VERSION ""

NS_ :

BS_:

BU_: EPB SCC ACU MDPS PGS AFLS CLU LCA iBAU TPMS LDWS_LKAS CGW

BO_ 550 NAVI_STD_STUB_E: 8 CGW
 SG_ STUB_MessageType : 0|3@1+ (1,0) [0|7] ""  SCC
 SG_ STUB_Offset : 3|13@1+ (1,0) [0|8191] ""  SCC
 SG_ STUB_CyclicCounter : 16|2@1+ (1,0) [0|3] ""  SCC
 SG_ STUB_PathIndex : 18|6@1+ (1,0) [0|63] ""  SCC
 SG_ STUB_SubPathIndex : 24|6@1+ (1,0) [0|63] ""  SCC
 SG_ STUB_Retransmission : 30|1@1+ (1,0) [0|1] ""  SCC
 SG_ STUB_Update : 31|1@1+ (1,0) [0|1] ""  SCC
 SG_ STUB_RelativeProbability : 32|5@1+ (3.333,0) [0|103.323] ""  SCC
 SG_ STUB_FunctionalRoadClass : 37|3@1+ (1,0) [0|7] ""  SCC
 SG_ STUB_CalculatedRoute : 40|2@1+ (1,0) [0|3] ""  SCC
 SG_ STUB_ComplexIntersection : 42|2@1+ (1,0) [0|3] ""  SCC
 SG_ STUB_FormOfWay : 44|4@1+ (1,0) [0|15] ""  SCC
 SG_ STUB_TurnAngle : 48|8@1+ (1.417,0) [0|361.335] ""  SCC
 SG_ STUB_LastStubAtOffset : 56|1@1+ (1,0) [0|1] ""  SCC
 SG_ STUB_RightOfWay : 57|2@1+ (1,0) [0|3] ""  SCC
 SG_ STUB_OppositeLanes : 59|2@1+ (1,0) [0|3] ""  SCC
 SG_ STUB_DirectionLanes : 61|3@1+ (1,0) [0|7] ""  SCC

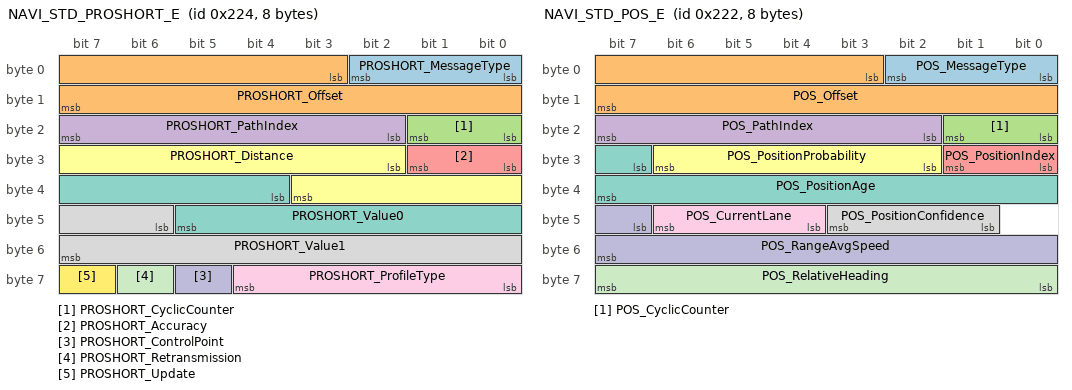
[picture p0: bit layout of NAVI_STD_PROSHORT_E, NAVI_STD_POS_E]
BO_ 548 NAVI_STD_PROSHORT_E: 8 CGW
 SG_ PROSHORT_MessageType : 0|3@1+ (1,0) [0|7] ""  SCC
 SG_ PROSHORT_Offset : 3|13@1+ (1,0) [0|8191] ""  SCC
 SG_ PROSHORT_CyclicCounter : 16|2@1+ (1,0) [0|3] ""  SCC
 SG_ PROSHORT_PathIndex : 18|6@1+ (1,0) [0|63] ""  SCC
 SG_ PROSHORT_Accuracy : 24|2@1+ (1,0) [0|3] ""  SCC
 SG_ PROSHORT_Distance : 26|10@1+ (1,0) [0|1023] ""  SCC
 SG_ PROSHORT_Value0 : 36|10@1+ (1,0) [0|1023] ""  SCC
 SG_ PROSHORT_Value1 : 46|10@1+ (1,0) [0|1023] ""  SCC
 SG_ PROSHORT_ProfileType : 56|5@1+ (1,0) [0|31] ""  SCC
 SG_ PROSHORT_ControlPoint : 61|1@1+ (1,0) [0|1] ""  SCC
 SG_ PROSHORT_Retransmission : 62|1@1+ (1,0) [0|1] ""  SCC
 SG_ PROSHORT_Update : 63|1@1+ (1,0) [0|1] ""  SCC

BO_ 549 NAVI_STD_SEG_E: 8 CGW
 SG_ SEG_MessageType : 0|3@1+ (1,0) [0|7] ""  SCC
 SG_ SEG_Offset : 3|13@1+ (1,0) [0|8191] ""  SCC
 SG_ SEG_CyclicCounter : 16|2@1+ (1,0) [0|3] ""  SCC
 SG_ SEG_PathIndex : 18|6@1+ (1,0) [0|63] ""  SCC
 SG_ SEG_Tunnel : 24|2@1+ (1,0) [0|3] ""  SCC
 SG_ SEG_Bridge : 26|2@1+ (1,0) [0|3] ""  SCC
 SG_ SEG_BuiltUpArea : 28|2@1+ (1,0) [0|3] ""  SCC
 SG_ SEG_Retransmission : 30|1@1+ (1,0) [0|1] ""  SCC
 SG_ SEG_Update : 31|1@1+ (1,0) [0|1] ""  SCC
 SG_ SEG_RelativeProbability : 32|5@1+ (3.333,0) [0|103.323] ""  SCC
 SG_ SEG_FunctionalRoadClass : 37|3@1+ (1,0) [0|7] ""  SCC
 SG_ SEG_CalculatedRoute : 40|2@1+ (1,0) [0|3] ""  SCC
 SG_ SEG_ComplexIntersection : 42|2@1+ (1,0) [0|3] ""  SCC
 SG_ SEG_FormOfWay : 44|4@1+ (1,0) [0|15] ""  SCC
 SG_ SEG_SpeedLimit : 48|5@1+ (1,0) [0|31] ""  SCC
 SG_ SEG_SpeedLimitType : 53|3@1+ (1,0) [0|7] ""  SCC
 SG_ SEG_DividedRoad : 57|2@1+ (1,0) [0|3] ""  SCC
 SG_ SEG_OppositeLanes : 59|2@1+ (1,0) [0|3] ""  SCC
 SG_ SEG_DirectionLanes : 61|3@1+ (1,0) [0|7] ""  SCC

BO_ 546 NAVI_STD_POS_E: 8 CGW
 SG_ POS_MessageType : 0|3@1+ (1,0) [0|7] ""  SCC
 SG_ POS_Offset : 3|13@1+ (1,0) [0|8191] ""  SCC
 SG_ POS_CyclicCounter : 16|2@1+ (1,0) [0|3] ""  SCC
 SG_ POS_PathIndex : 18|6@1+ (1,0) [0|63] ""  SCC
 SG_ POS_PositionIndex : 24|2@1+ (1,0) [0|3] ""  SCC
 SG_ POS_PositionProbability : 26|5@1+ (3.333,0) [0|103.323] ""  SCC
 SG_ POS_PositionAge : 31|9@1+ (5,0) [0|2555] ""  SCC
 SG_ POS_PositionConfidence : 41|3@1+ (1,0) [0|7] ""  SCC
 SG_ POS_CurrentLane : 44|3@1+ (1,0) [0|7] ""  SCC
 SG_ POS_RangeAvgSpeed : 47|9@1+ (1,0) [0|511] ""  SCC
 SG_ POS_RelativeHeading : 56|8@1+ (1.417,0) [0|361.335] ""  SCC

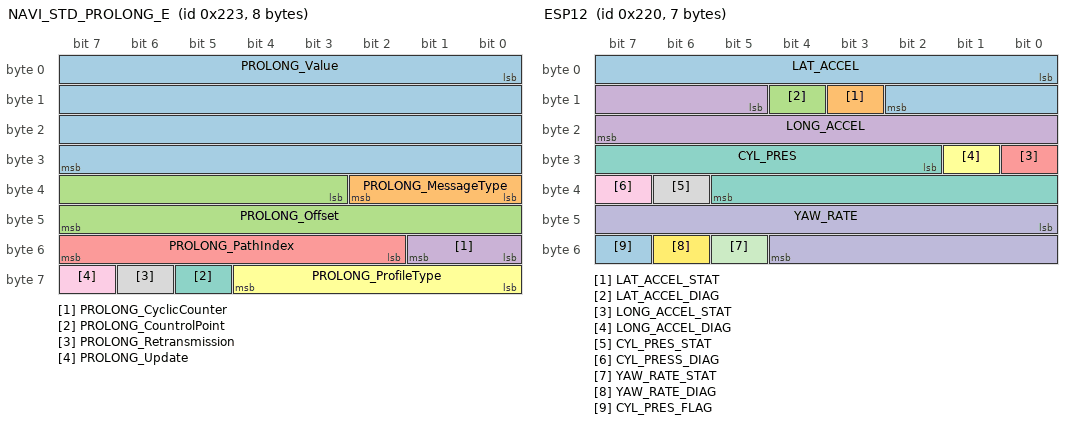
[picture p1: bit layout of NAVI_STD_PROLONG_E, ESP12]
BO_ 547 NAVI_STD_PROLONG_E: 8 CGW
 SG_ PROLONG_Value : 0|32@1+ (1,0) [0|4294967295] ""  SCC
 SG_ PROLONG_MessageType : 32|3@1+ (1,0) [0|7] ""  SCC
 SG_ PROLONG_Offset : 35|13@1+ (1,0) [0|8191] ""  SCC
 SG_ PROLONG_CyclicCounter : 48|2@1+ (1,0) [0|3] ""  SCC
 SG_ PROLONG_PathIndex : 50|6@1+ (1,0) [0|63] ""  SCC
 SG_ PROLONG_ProfileType : 56|5@1+ (1,0) [0|31] ""  SCC
 SG_ PROLONG_CountrolPoint : 61|1@1+ (1,0) [0|1] ""  SCC
 SG_ PROLONG_Retransmission : 62|1@1+ (1,0) [0|1] ""  SCC
 SG_ PROLONG_Update : 63|1@1+ (1,0) [0|1] ""  SCC

BO_ 544 ESP12: 7 iBAU
 SG_ LAT_ACCEL : 0|11@1+ (0.01,-10.23) [-10.23|10.24] "m/s^2"  LDWS_LKAS,SCC
 SG_ LAT_ACCEL_STAT : 11|1@1+ (1,0) [0|1] ""  LDWS_LKAS,SCC
 SG_ LAT_ACCEL_DIAG : 12|1@1+ (1,0) [0|1] ""  LDWS_LKAS,SCC
 SG_ LONG_ACCEL : 13|11@1+ (0.01,-10.23) [-10.23|10.24] "m/s^2"  EPB,LDWS_LKAS,SCC
 SG_ LONG_ACCEL_STAT : 24|1@1+ (1,0) [0|1] ""  EPB,LDWS_LKAS,SCC
 SG_ LONG_ACCEL_DIAG : 25|1@1+ (1,0) [0|1] ""  EPB,LDWS_LKAS,SCC
 SG_ CYL_PRES : 26|12@1+ (0.1,0) [0|409.5] "Bar"  EPB,LDWS_LKAS,SCC
 SG_ CYL_PRES_STAT : 38|1@1+ (1,0) [0|1] ""  CGW,EPB,LDWS_LKAS,SCC
 SG_ CYL_PRESS_DIAG : 39|1@1+ (1,0) [0|1] ""  EPB,LDWS_LKAS,SCC
 SG_ YAW_RATE : 40|13@1+ (0.01,-40.95) [-40.95|40.96] "˚/s"  AFLS,LCA,LDWS_LKAS,MDPS,SCC
 SG_ YAW_RATE_STAT : 53|1@1+ (1,0) [0|1] ""  AFLS,LDWS_LKAS,MDPS,SCC
 SG_ YAW_RATE_DIAG : 54|1@1+ (1,0) [0|1] ""  AFLS,LDWS_LKAS,MDPS,SCC
 SG_ CYL_PRES_FLAG : 55|1@1+ (1,0) [0|1] ""  CGW

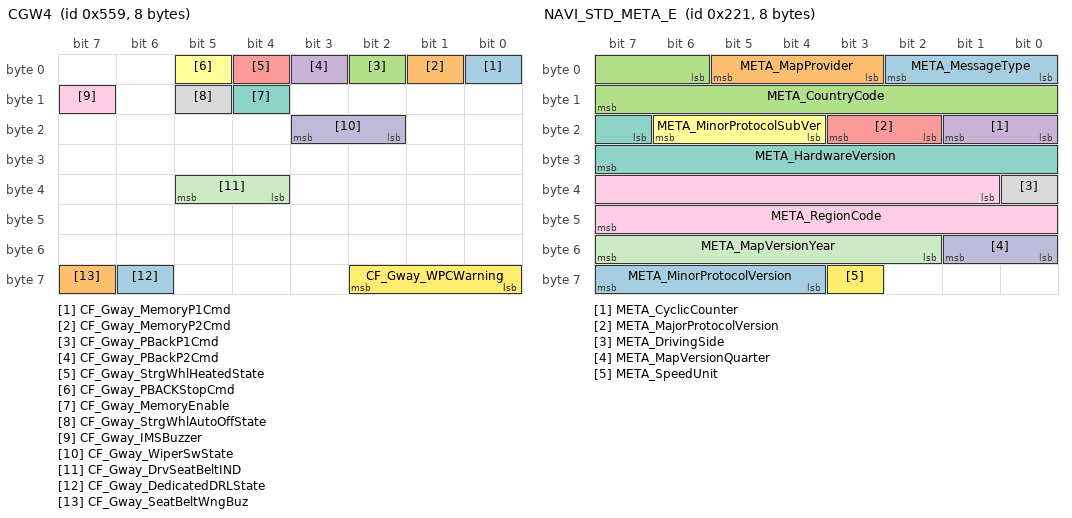
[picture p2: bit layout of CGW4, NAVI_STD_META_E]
BO_ 1369 CGW4: 8 CGW
 SG_ CF_Gway_MemoryP1Cmd : 0|1@1+ (1,0) [0|1] ""  CLU
 SG_ CF_Gway_MemoryP2Cmd : 1|1@1+ (1,0) [0|1] ""  CLU
 SG_ CF_Gway_PBackP1Cmd : 2|1@1+ (1,0) [0|1] ""  CLU
 SG_ CF_Gway_PBackP2Cmd : 3|1@1+ (1,0) [0|1] ""  CLU
 SG_ CF_Gway_StrgWhlHeatedState : 4|1@1+ (1,0) [0|1] ""  CLU
 SG_ CF_Gway_PBACKStopCmd : 5|1@1+ (1,0) [0|1] ""  CLU
 SG_ CF_Gway_MemoryEnable : 12|1@1+ (1,0) [0|1] ""  CLU
 SG_ CF_Gway_StrgWhlAutoOffState : 13|1@1+ (1,0) [0|1] ""  CLU
 SG_ CF_Gway_IMSBuzzer : 15|1@1+ (1,0) [0|1] ""  CLU
 SG_ CF_Gway_WiperSwState : 18|2@1+ (1,0) [0|3] ""  CLU
 SG_ CF_Gway_DrvSeatBeltIND : 36|2@1+ (1,0) [0|3] ""  CLU
 SG_ CF_Gway_WPCWarning : 56|3@1+ (1,0) [0|7] ""  CLU
 SG_ CF_Gway_DedicatedDRLState : 62|1@1+ (1,0) [0|1] ""  CLU
 SG_ CF_Gway_SeatBeltWngBuz : 63|1@1+ (1,0) [0|1] ""  CLU

BO_ 545 NAVI_STD_META_E: 8 CGW
 SG_ META_MessageType : 0|3@1+ (1,0) [0|7] ""  SCC
 SG_ META_MapProvider : 3|3@1+ (1,0) [0|7] ""  SCC
 SG_ META_CountryCode : 6|10@1+ (1,0) [0|1023] ""  SCC
 SG_ META_CyclicCounter : 16|2@1+ (1,0) [0|3] ""  SCC
 SG_ META_MajorProtocolVersion : 18|2@1+ (1,0) [0|3] ""  SCC
 SG_ META_MinorProtocolSubVer : 20|3@1+ (1,0) [0|7] ""  SCC
 SG_ META_HardwareVersion : 23|9@1+ (1,0) [0|511] ""  SCC
 SG_ META_DrivingSide : 32|1@1+ (1,0) [0|1] ""  SCC
 SG_ META_RegionCode : 33|15@1+ (1,0) [0|32767] ""  SCC
 SG_ META_MapVersionQuarter : 48|2@1+ (1,0) [0|3] ""  SCC
 SG_ META_MapVersionYear : 50|6@1+ (1,2000) [2000|2063] ""  SCC
 SG_ META_SpeedUnit : 59|1@1+ (1,0) [0|1] ""  SCC
 SG_ META_MinorProtocolVersion : 60|4@1+ (1,0) [0|15] ""  SCC

BO_ 1363 CGW2: 8 CGW
 SG_ CF_Gway_ExtTailAct : 8|2@1+ (1,0) [0|3] ""  CLU,LCA
 SG_ CF_Gway_AutoLightValue : 16|1@1+ (1,0) [0|1] ""  LCA
 SG_ CF_Gway_BrakeFluidSw : 17|1@1+ (1,0) [0|1] ""  CLU,iBAU
 SG_ CF_Gway_DrvSeatBeltInd : 18|2@1+ (1,0) [0|3] ""  CLU
 SG_ CF_Gway_AvTail : 20|1@1+ (1,0) [0|1] ""  CLU
 SG_ CF_Gway_RearFogAct : 21|1@1+ (1,0) [0|1] ""  CLU
 SG_ CF_Gway_RRDrSw : 23|1@1+ (1,0) [0|1] ""  CLU
 SG_ CF_Gway_RLDrSw : 24|1@1+ (1,0) [0|1] ""  CLU
 SG_ CF_Gway_IntTailAct : 25|1@1+ (1,0) [0|1] ""  CLU
 SG_ CF_Gway_WiperParkPosition : 32|1@1+ (1,0) [0|1] ""  LDWS_LKAS
 SG_ CF_Gway_ESCLFailWarn : 35|1@1+ (1,0) [0|1] ""  CLU
 SG_ CF_Gway_ESCLNotLockedWarn : 36|1@1+ (1,0) [0|1] ""  CLU
 SG_ CF_Gway_ESCLNotUnlockWarn : 37|1@1+ (1,0) [0|1] ""  CLU
 SG_ CF_Gway_IDoutWarn : 38|1@1+ (1,0) [0|1] ""  CLU
 SG_ CF_Gway_ImmoLp : 40|1@1+ (1,0) [0|1] ""  CLU
 SG_ CF_Gway_VehicleNotPWarn : 44|1@1+ (1,0) [0|1] ""  CLU
 SG_ CF_Gway_DeactivationWarn : 45|1@1+ (1,0) [0|1] ""  CLU
 SG_ CF_Gway_KeyBATDischargeWarn : 46|1@1+ (1,0) [0|1] ""  CLU
 SG_ CF_Gway_SSBWarn : 47|1@1+ (1,0) [0|1] ""  CLU
 SG_ CF_Gway_SMKRKECmd : 51|3@1+ (1,0) [0|7] ""  CLU
 SG_ CF_Gway_SJBDeliveryMode : 55|1@1+ (1,0) [0|1] ""  CLU
 SG_ CF_Gway_SMKDispWarn : 57|4@1+ (1,0) [0|15] ""  CLU
 SG_ CF_Gway_WngBuz : 61|3@1+ (1,0) [0|7] ""  CLU

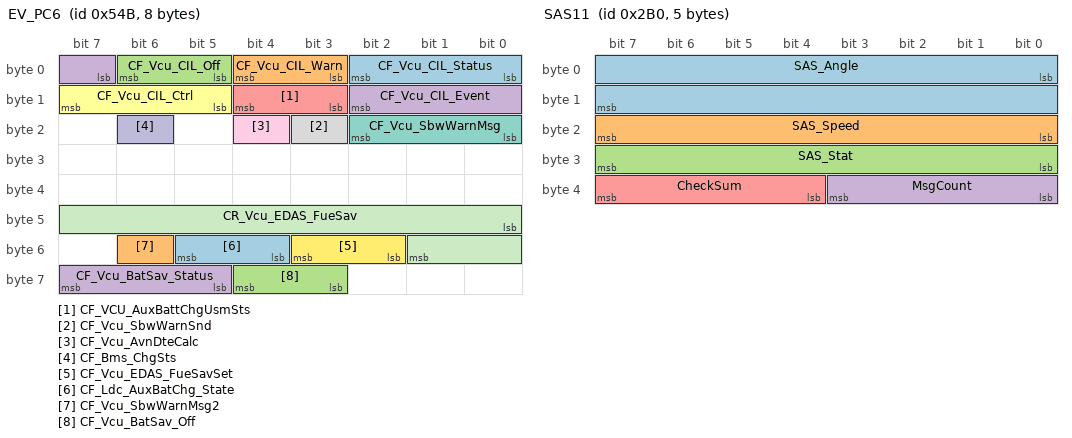
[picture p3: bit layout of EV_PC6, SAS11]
BO_ 1355 EV_PC6: 8 CGW
 SG_ CF_Vcu_CIL_Status : 0|3@1+ (1,0) [0|7] ""  CLU
 SG_ CF_Vcu_CIL_Warn : 3|2@1+ (1,0) [0|3] ""  CLU
 SG_ CF_Vcu_CIL_Off : 5|2@1+ (1,0) [0|3] ""  CLU
 SG_ CF_Vcu_CIL_Event : 7|4@1+ (1,0) [0|15] ""  CLU
 SG_ CF_VCU_AuxBattChgUsmSts : 11|2@1+ (1,0) [0|3] ""  CLU
 SG_ CF_Vcu_CIL_Ctrl : 13|3@1+ (1,0) [0|7] ""  CLU
 SG_ CF_Vcu_SbwWarnMsg : 16|3@1+ (1,0) [0|7] "flag"  CLU,EPB
 SG_ CF_Vcu_SbwWarnSnd : 19|1@1+ (1,0) [0|1] "flag"  CLU
 SG_ CF_Vcu_AvnDteCalc : 20|1@1+ (1,0) [0|1] "flag"  CLU
 SG_ CF_Bms_ChgSts : 22|1@1+ (1,0) [0|1] ""  CLU
 SG_ CR_Vcu_EDAS_FueSav : 40|10@1+ (0.01,0) [0|10] "liter"  CLU
 SG_ CF_Vcu_EDAS_FueSavSet : 50|2@1+ (1,0) [0|3] ""  CLU
 SG_ CF_Ldc_AuxBatChg_State : 52|2@1+ (1,0) [0|3] ""  CLU
 SG_ CF_Vcu_SbwWarnMsg2 : 54|1@1+ (1,0) [0|1] "flag"  CLU
 SG_ CF_Vcu_BatSav_Off : 59|2@1+ (1,0) [0|3] ""  CLU
 SG_ CF_Vcu_BatSav_Status : 61|3@1+ (1,0) [0|7] ""  CLU

BO_ 1348 NAVI_SLIF: 8 CGW
 SG_ HU_AliveStatus : 14|2@1+ (1,0) [0|3] ""  SCC

BO_ 688 SAS11: 5 MDPS
 SG_ SAS_Angle : 0|16@1- (0.1,0) [-3276.8|3276.7] "Deg"  AFLS,CGW,CLU,LCA,LDWS_LKAS,PGS,SCC,iBAU
 SG_ SAS_Speed : 16|8@1+ (4,0) [0|1016] ""  AFLS,LDWS_LKAS,SCC,iBAU
 SG_ SAS_Stat : 24|8@1+ (1,0) [0|255] ""  LDWS_LKAS,SCC,iBAU
 SG_ MsgCount : 32|4@1+ (1,0) [0|15] ""  LDWS_LKAS,SCC,iBAU
 SG_ CheckSum : 36|4@1+ (1,0) [0|15] ""  LDWS_LKAS,SCC,iBAU

BO_ 1345 CGW1: 8 CGW
 SG_ CF_Gway_IGNSw : 0|3@1+ (1,0) [0|7] ""  AFLS,CLU,EPB,LDWS_LKAS,MDPS
 SG_ CF_Gway_RKECmd : 3|3@1+ (1,0) [0|7] ""  CLU
 SG_ CF_Gway_DrvDrSw : 8|2@1+ (1,0) [0|3] ""  CLU,EPB,LDWS_LKAS,SCC
 SG_ CF_Gway_DrvSeatBeltSw : 10|2@1+ (1,0) [0|3] ""  EPB,LDWS_LKAS
 SG_ CF_Gway_TrunkTgSw : 12|2@1+ (1,0) [0|3] ""  CLU,EPB
 SG_ CF_Gway_SMKOption : 16|1@1+ (1,0) [0|1] ""  CLU
 SG_ CF_Gway_HoodSw : 17|2@1+ (1,0) [0|3] ""  CLU,EPB
 SG_ CF_Gway_TurnSigLh : 19|2@1+ (1,0) [0|3] ""  CLU,LCA,LDWS_LKAS,SCC
 SG_ CF_Gway_WiperIntT : 21|3@1+ (1,0) [0|7] ""  CLU,LDWS_LKAS
 SG_ CF_Gway_RainSnsState : 28|3@1+ (1,0) [0|7] ""  AFLS
 SG_ CF_Gway_HeadLampLow : 31|1@1+ (1,0) [0|1] ""  AFLS,CLU,LDWS_LKAS
 SG_ CF_Gway_HeadLampHigh : 32|1@1+ (1,0) [0|1] ""  AFLS,CLU,LDWS_LKAS
 SG_ CF_Gway_HazardSw : 33|2@1+ (1,0) [0|3] ""  LCA,LDWS_LKAS
 SG_ CF_Gway_AstDrSw : 35|1@1+ (1,0) [0|1] ""  CLU
 SG_ CF_Gway_LightSwState : 38|2@1+ (1,0) [0|3] ""  AFLS,CLU
 SG_ CF_Gway_TSigRHSw : 41|1@1+ (1,0) [0|1] ""  LDWS_LKAS
 SG_ CF_Gway_TSigLHSw : 42|1@1+ (1,0) [0|1] ""  LDWS_LKAS
 SG_ CF_Gway_DriveTypeOption : 43|1@1+ (1,0) [0|1] ""  CLU
 SG_ CF_Gway_PassiveAccessLock : 45|2@1+ (1,0) [0|3] ""  CLU
 SG_ CF_Gway_PassiveAccessUnlock : 48|2@1+ (1,0) [0|3] ""  CLU
 SG_ CF_Gway_PassingSW : 51|1@1+ (1,0) [0|1] ""  AFLS
 SG_ CF_Gway_HBAControlMode : 52|1@1+ (1,0) [0|1] ""  LDWS_LKAS
 SG_ CF_Gway_RainSnsOption : 56|1@1+ (1,0) [0|1] ""  CLU
 SG_ C_SunRoofOpenState : 57|1@1+ (1,0) [0|1] ""  CLU
 SG_ CF_Gway_TurnSigRh : 62|2@1+ (1,0) [0|3] ""  CLU,LCA,LDWS_LKAS,SCC

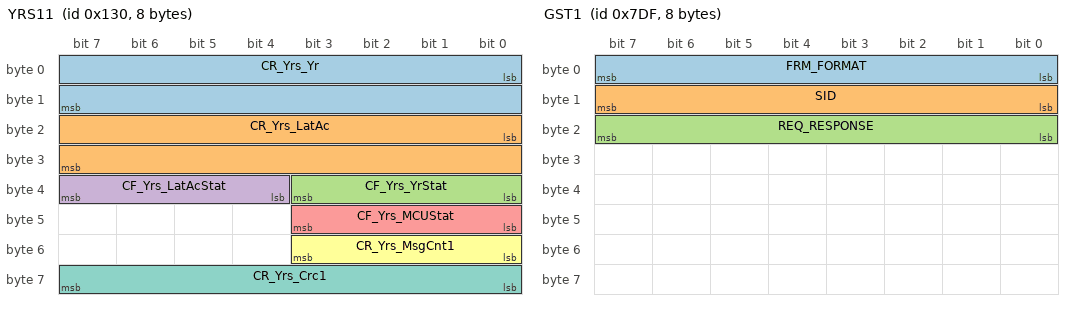
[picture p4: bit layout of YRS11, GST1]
BO_ 304 YRS11: 8 ACU
 SG_ CR_Yrs_Yr : 0|16@1+ (0.005,-163.84) [-163.84|163.83] "˚/s"  iBAU
 SG_ CR_Yrs_LatAc : 16|16@1+ (1.27465E-4,-4.17677312) [-4.17677312|4.17651819] "g"  iBAU
 SG_ CF_Yrs_YrStat : 32|4@1+ (1,0) [0|15] ""  iBAU
 SG_ CF_Yrs_LatAcStat : 36|4@1+ (1,0) [0|15] ""  iBAU
 SG_ CF_Yrs_MCUStat : 40|4@1+ (1,0) [0|15] ""  iBAU
 SG_ CR_Yrs_MsgCnt1 : 48|4@1+ (1,0) [0|15] ""  iBAU
 SG_ CR_Yrs_Crc1 : 56|8@1+ (1,0) [0|255] ""  iBAU

BO_ 1407 HU_MON_PE_01: 8 CGW
 SG_ HU_DistributeInfo : 24|8@1+ (1,0) [0|255] ""  SCC
 SG_ HU_AdasSupport : 56|3@1+ (1,0) [0|7] ""  SCC

BO_ 916 TCS13: 8 iBAU
 SG_ aBasis : 0|11@1+ (0.01,-10.23) [-10.23|10.24] "m/s^2"  Vector__XXX
 SG_ BrakeLight : 11|1@1+ (1,0) [0|1] ""  CLU,SCC
 SG_ DCEnable : 12|1@1+ (1,0) [0|1] ""  Vector__XXX
 SG_ AliveCounterTCS : 13|3@1+ (1,0) [0|7] ""  SCC
 SG_ ACCReqLim : 21|2@1+ (1,0) [0|3] ""  SCC
 SG_ TQI_ACC : 23|9@1+ (0.390625,0) [0|199.609375] "%"  Vector__XXX
 SG_ ACCEL_REF_ACC : 32|11@1+ (0.01,-10.23) [-10.23|10.24] "m/s^2"  Vector__XXX
 SG_ ACCEnable : 43|2@1+ (1,0) [0|3] ""  SCC
 SG_ DriverOverride : 45|2@1+ (1,0) [0|3] ""  SCC
 SG_ StandStill : 47|1@1+ (1,0) [0|1] ""  Vector__XXX
 SG_ CheckSum_TCS3 : 48|4@1+ (1,0) [0|15] ""  SCC
 SG_ ACC_EQUIP : 52|1@1+ (1,0) [0|1] ""  SCC
 SG_ PBRAKE_ACT : 53|1@1+ (1,0) [0|1] ""  SCC
 SG_ ACC_REQ : 54|1@1+ (1,0) [0|1] ""  Vector__XXX
 SG_ DriverBraking : 55|1@1+ (1,0) [0|1] ""  AFLS
 SG_ CF_VSM_Coded : 56|1@1+ (1,0) [0|1] ""  Vector__XXX
 SG_ CF_VSM_Avail : 57|2@1+ (1,0) [0|3] ""  CLU,SCC
 SG_ CF_VSM_Handshake : 59|1@1+ (1,0) [0|1] ""  Vector__XXX
 SG_ CF_DriBkeStat : 60|1@1+ (1,0) [0|1] ""  Vector__XXX
 SG_ CF_VSM_ConfSwi : 61|2@1+ (1,0) [0|3] ""  Vector__XXX
 SG_ AEB_EQUIP : 63|1@1+ (1,0) [0|1] ""  SCC

BO_ 1535 EV_PC10: 8 CGW
 SG_ BAT_SOC : 0|8@1+ (1,0) [0|100] "%"  CLU

BO_ 2015 GST1: 8 CGW
 SG_ FRM_FORMAT : 0|8@1+ (1,0) [0|31] ""  ACU,AFLS,EPB,LCA,LDWS_LKAS,iBAU
 SG_ SID : 8|8@1+ (1,0) [0|255] ""  ACU,AFLS,EPB,LCA,LDWS_LKAS,iBAU
 SG_ REQ_RESPONSE : 16|8@1+ (1,0) [0|2] ""  ACU,AFLS,EPB,LCA,LDWS_LKAS,iBAU

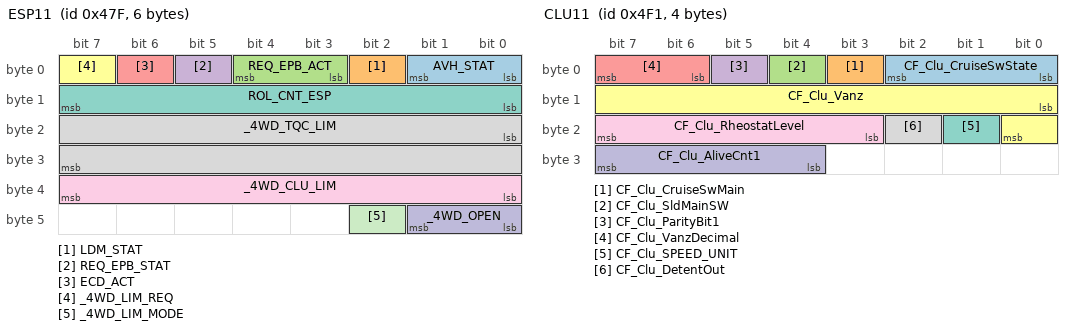
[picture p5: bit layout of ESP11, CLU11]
BO_ 1151 ESP11: 6 iBAU
 SG_ AVH_STAT : 0|2@1+ (1,0) [0|3] ""  CGW,EPB
 SG_ LDM_STAT : 2|1@1+ (1,0) [0|1] ""  EPB
 SG_ REQ_EPB_ACT : 3|2@1+ (1,0) [0|3] ""  EPB
 SG_ REQ_EPB_STAT : 5|1@1+ (1,0) [0|1] ""  EPB
 SG_ ECD_ACT : 6|1@1+ (1,0) [0|1] ""  EPB
 SG_ _4WD_LIM_REQ : 7|1@1+ (1,0) [0|1] ""  Vector__XXX
 SG_ ROL_CNT_ESP : 8|8@1+ (1,0) [0|255] ""  EPB
 SG_ _4WD_TQC_LIM : 16|16@1+ (1,0) [0|65535] "Nm"  Vector__XXX
 SG_ _4WD_CLU_LIM : 32|8@1+ (0.390625,0) [0|99.609375] "%"  Vector__XXX
 SG_ _4WD_OPEN : 40|2@1+ (1,0) [0|3] ""  Vector__XXX
 SG_ _4WD_LIM_MODE : 42|1@1+ (1,0) [0|1] ""  Vector__XXX

BO_ 1984 CAL_SAS11: 2 iBAU
 SG_ CCW : 0|4@1+ (1,0) [0|15] ""  Vector__XXX
 SG_ SAS_CID : 4|11@1+ (1,0) [0|2047] ""  Vector__XXX

BO_ 1507 VESS1: 8 CGW
 SG_ CR_VCU_EcoLvl : 0|1@1+ (1,0) [0|1] ""  CLU

BO_ 1265 CLU11: 4 CLU
 SG_ CF_Clu_CruiseSwState : 0|3@1+ (1,0) [0|7] ""  CGW,LDWS_LKAS,SCC
 SG_ CF_Clu_CruiseSwMain : 3|1@1+ (1,0) [0|1] ""  CGW,LDWS_LKAS,SCC
 SG_ CF_Clu_SldMainSW : 4|1@1+ (1,0) [0|1] ""  CGW
 SG_ CF_Clu_ParityBit1 : 5|1@1+ (1,0) [0|1] "pulse count"  Vector__XXX
 SG_ CF_Clu_VanzDecimal : 6|2@1+ (0.125,0) [0|0.375] ""  Vector__XXX
 SG_ CF_Clu_Vanz : 8|9@1+ (0.5,0) [0|255.5] "km/h or MPH"  CGW,LCA,LDWS_LKAS,MDPS,SCC,iBAU
 SG_ CF_Clu_SPEED_UNIT : 17|1@1+ (1,0) [0|1] ""  CGW,LCA,LDWS_LKAS,MDPS,SCC
 SG_ CF_Clu_DetentOut : 18|1@1+ (1,0) [0|1] ""  CGW,LCA
 SG_ CF_Clu_RheostatLevel : 19|5@1+ (1,0) [0|31] ""  CGW,LCA,MDPS
 SG_ CF_Clu_AliveCnt1 : 28|4@1+ (1,0) [0|15] ""  EPB,LDWS_LKAS,MDPS,SCC

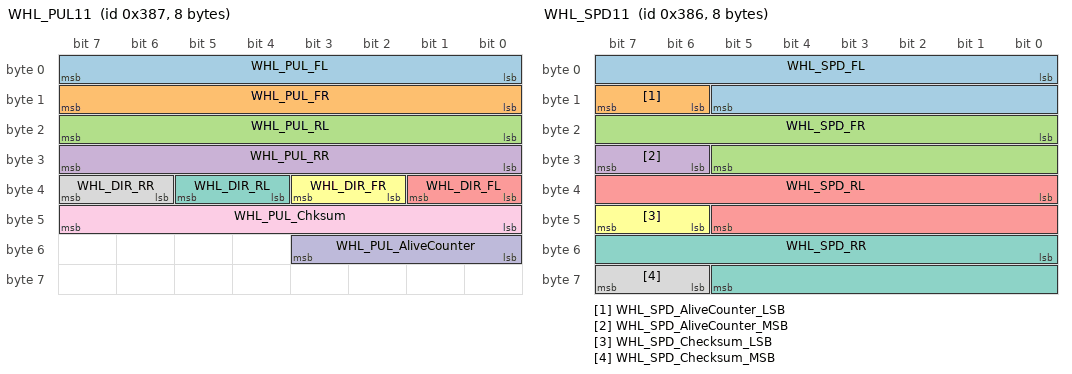
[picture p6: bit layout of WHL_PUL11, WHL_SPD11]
BO_ 903 WHL_PUL11: 8 iBAU
 SG_ WHL_PUL_FL : 0|8@1+ (0.5,0) [0|127.5] "pulse count"  EPB,TPMS
 SG_ WHL_PUL_FR : 8|8@1+ (0.5,0) [0|127.5] "pulse count"  EPB,TPMS
 SG_ WHL_PUL_RL : 16|8@1+ (0.5,0) [0|127.5] "pulse count"  EPB,TPMS
 SG_ WHL_PUL_RR : 24|8@1+ (0.5,0) [0|127.5] "pulse count"  EPB,TPMS
 SG_ WHL_DIR_FL : 32|2@1+ (1,0) [0|3] ""  EPB,TPMS
 SG_ WHL_DIR_FR : 34|2@1+ (1,0) [0|3] ""  EPB,TPMS
 SG_ WHL_DIR_RL : 36|2@1+ (1,0) [0|3] ""  EPB,TPMS
 SG_ WHL_DIR_RR : 38|2@1+ (1,0) [0|3] ""  EPB,TPMS
 SG_ WHL_PUL_Chksum : 40|8@1+ (1,0) [0|255] ""  EPB,TPMS
 SG_ WHL_PUL_AliveCounter : 48|4@1+ (1,0) [0|14] ""  SCC

BO_ 902 WHL_SPD11: 8 iBAU
 SG_ WHL_SPD_FL : 0|14@1+ (0.03125,0) [0|511.96875] "km/h"  AFLS,CLU,EPB,LCA,LDWS_LKAS,MDPS,SCC,TPMS
 SG_ WHL_SPD_AliveCounter_LSB : 14|2@1+ (1,0) [0|3] ""  Vector__XXX
 SG_ WHL_SPD_FR : 16|14@1+ (0.03125,0) [0|511.96875] "km/h"  AFLS,CLU,EPB,LCA,LDWS_LKAS,MDPS,SCC,TPMS
 SG_ WHL_SPD_AliveCounter_MSB : 30|2@1+ (1,0) [0|3] ""  Vector__XXX
 SG_ WHL_SPD_RL : 32|14@1+ (0.03125,0) [0|511.96875] "km/h"  AFLS,CLU,EPB,LCA,LDWS_LKAS,MDPS,SCC,TPMS
 SG_ WHL_SPD_Checksum_LSB : 46|2@1+ (1,0) [0|3] ""  Vector__XXX
 SG_ WHL_SPD_RR : 48|14@1+ (0.03125,0) [0|511.96875] "km/h"  AFLS,CLU,EPB,LCA,LDWS_LKAS,MDPS,SCC,TPMS
 SG_ WHL_SPD_Checksum_MSB : 62|2@1+ (1,0) [0|3] ""  Vector__XXX

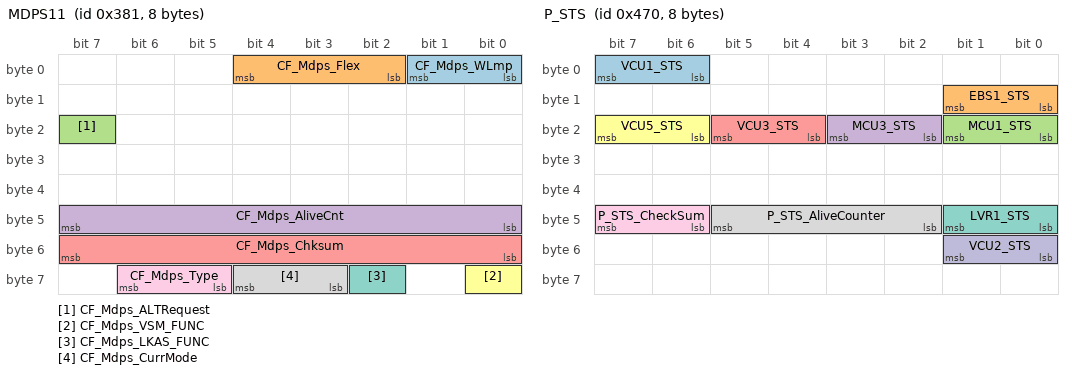
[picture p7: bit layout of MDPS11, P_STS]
BO_ 897 MDPS11: 8 MDPS
 SG_ CF_Mdps_WLmp : 0|2@1+ (1,0) [0|3] ""  CGW,CLU
 SG_ CF_Mdps_Flex : 2|3@1+ (1,0) [0|3] ""  LDWS_LKAS
 SG_ CF_Mdps_ALTRequest : 23|1@1+ (1,0) [0|1] ""  Vector__XXX
 SG_ CF_Mdps_AliveCnt : 40|8@1+ (1,0) [0|255] ""  LDWS_LKAS
 SG_ CF_Mdps_Chksum : 48|8@1+ (1,0) [0|255] ""  LDWS_LKAS
 SG_ CF_Mdps_VSM_FUNC : 56|1@1+ (1,0) [0|1] "flag"  iBAU
 SG_ CF_Mdps_LKAS_FUNC : 58|1@1+ (1,0) [0|1] "flag"  LDWS_LKAS
 SG_ CF_Mdps_CurrMode : 59|2@1+ (1,0) [0|3] ""  LDWS_LKAS
 SG_ CF_Mdps_Type : 61|2@1+ (1,0) [0|2] ""  LDWS_LKAS

BO_ 1136 P_STS: 8 CGW
 SG_ VCU1_STS : 6|2@1+ (1,0) [0|3] ""  EPB,LCA,LDWS_LKAS,MDPS,SCC
 SG_ EBS1_STS : 8|2@1+ (1,0) [0|3] ""  EPB
 SG_ MCU1_STS : 16|2@1+ (1,0) [0|3] ""  EPB
 SG_ MCU3_STS : 18|2@1+ (1,0) [0|3] ""  LCA,LDWS_LKAS,MDPS
 SG_ VCU3_STS : 20|2@1+ (1,0) [0|3] ""  EPB
 SG_ VCU5_STS : 22|2@1+ (1,0) [0|3] ""  EPB,SCC
 SG_ LVR1_STS : 40|2@1+ (1,0) [0|3] ""  LDWS_LKAS
 SG_ P_STS_AliveCounter : 42|4@1+ (1,0) [0|15] ""  LCA,LDWS_LKAS,MDPS,SCC
 SG_ P_STS_CheckSum : 46|2@1+ (1,0) [0|3] ""  LCA,LDWS_LKAS,MDPS,SCC
 SG_ VCU2_STS : 48|2@1+ (1,0) [0|3] ""  EPB,SCC

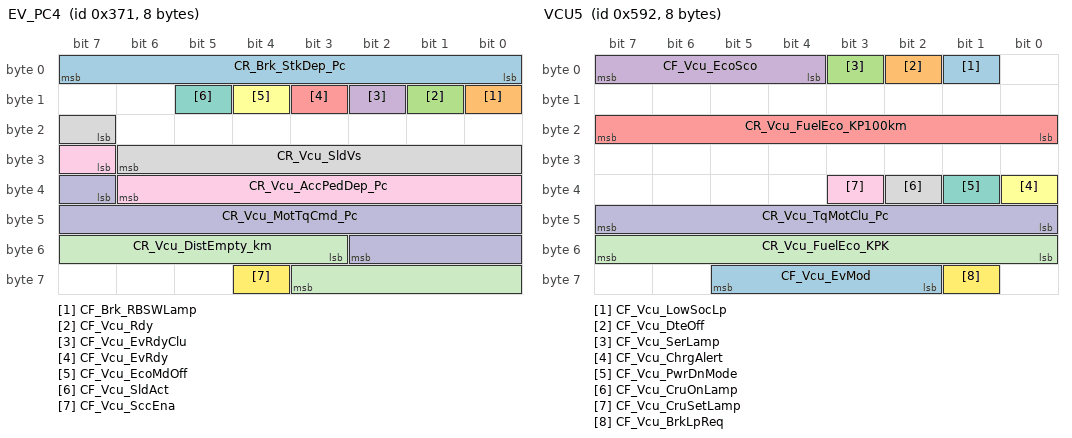
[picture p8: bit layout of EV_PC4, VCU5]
BO_ 881 EV_PC4: 8 CGW
 SG_ CR_Brk_StkDep_Pc : 0|8@1+ (1,0) [0|100] "%"  CLU,EPB,LDWS_LKAS,TPMS
 SG_ CF_Brk_RBSWLamp : 8|1@1+ (1,0) [0|1] ""  CLU
 SG_ CF_Vcu_Rdy : 9|1@1+ (1,0) [0|1] ""  EPB
 SG_ CF_Vcu_EvRdyClu : 10|1@1+ (1,0) [0|1] ""  CLU,EPB
 SG_ CF_Vcu_EvRdy : 11|1@1+ (1,0) [0|1] ""  AFLS,CLU,EPB,LCA,LDWS_LKAS,MDPS,SCC
 SG_ CF_Vcu_EcoMdOff : 12|1@1+ (1,0) [0|1] ""  CLU,EPB
 SG_ CF_Vcu_SldAct : 13|1@1+ (1,0) [0|1] ""  CLU
 SG_ CR_Vcu_SldVs : 23|8@1+ (1,0) [0|255] "km/h"  CLU
 SG_ CR_Vcu_AccPedDep_Pc : 31|8@1+ (0.3921568627,0) [0|100] "%"  CLU,EPB,LDWS_LKAS,MDPS,SCC
 SG_ CR_Vcu_MotTqCmd_Pc : 39|12@1- (0.048828125,0) [-100|99.95] "%"  EPB
 SG_ CR_Vcu_DistEmpty_km : 51|9@1+ (1,0) [0|511] "km"  CLU
 SG_ CF_Vcu_SccEna : 60|1@1+ (1,0) [0|1] ""  SCC

BO_ 1426 VCU5: 8 CGW
 SG_ CF_Vcu_LowSocLp : 1|1@1+ (1,0) [0|1] ""  CLU
 SG_ CF_Vcu_DteOff : 2|1@1+ (1,0) [0|1] ""  CLU
 SG_ CF_Vcu_SerLamp : 3|1@1+ (1,0) [0|1] ""  CLU
 SG_ CF_Vcu_EcoSco : 4|4@1+ (1,0) [0|15] ""  CLU
 SG_ CR_Vcu_FuelEco_KP100km : 16|8@1+ (0.5,0) [0|126.5] ""  CLU
 SG_ CF_Vcu_ChrgAlert : 32|1@1+ (1,0) [0|1] ""  CLU
 SG_ CF_Vcu_PwrDnMode : 33|1@1+ (1,0) [0|1] ""  CLU
 SG_ CF_Vcu_CruOnLamp : 34|1@1+ (1,0) [0|1] ""  CLU
 SG_ CF_Vcu_CruSetLamp : 35|1@1+ (1,0) [0|1] ""  CLU
 SG_ CR_Vcu_TqMotClu_Pc : 40|8@1- (1,0) [-100|100] "%"  CLU
 SG_ CR_Vcu_FuelEco_KPK : 48|8@1+ (0.1,0) [0|25.5] "km/kWh"  CLU
 SG_ CF_Vcu_BrkLpReq : 57|1@1+ (1,0) [0|1] ""  EPB,SCC
 SG_ CF_Vcu_EvMod : 58|4@1+ (1,0) [0|9] ""  CLU,EPB

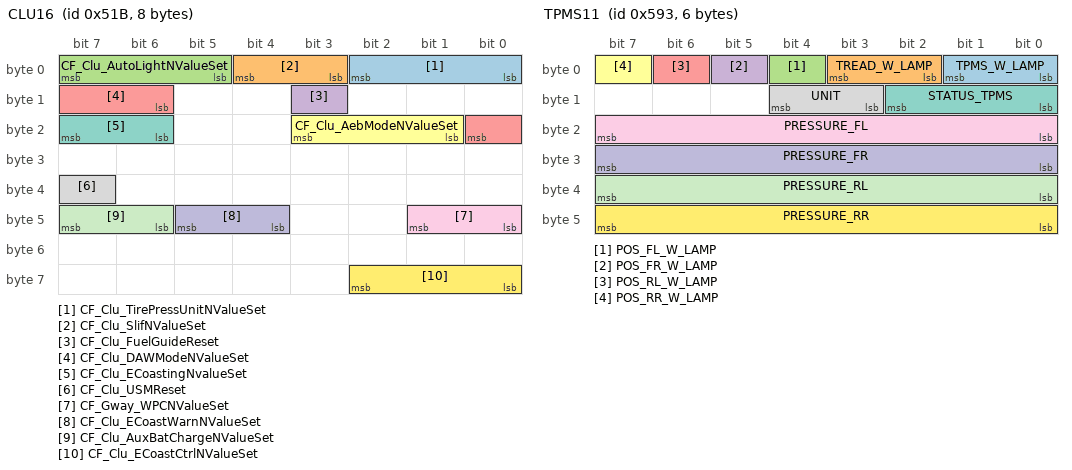
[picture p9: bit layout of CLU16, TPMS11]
BO_ 1307 CLU16: 8 CLU
 SG_ CF_Clu_TirePressUnitNValueSet : 0|3@1+ (1,0) [0|7] ""  TPMS
 SG_ CF_Clu_SlifNValueSet : 3|2@1+ (1,0) [0|3] ""  Vector__XXX
 SG_ CF_Clu_AutoLightNValueSet : 5|3@1+ (1,0) [0|7] ""  Vector__XXX
 SG_ CF_Clu_FuelGuideReset : 11|1@1+ (1,0) [0|1] ""  CGW
 SG_ CF_Clu_DAWModeNValueSet : 14|3@1+ (1,0) [0|7] ""  LDWS_LKAS
 SG_ CF_Clu_AebModeNValueSet : 17|3@1+ (1,0) [0|7] ""  SCC
 SG_ CF_Clu_ECoastingNvalueSet : 22|2@1+ (1,0) [0|1] ""  CGW
 SG_ CF_Clu_USMReset : 39|1@1+ (1,0) [0|1] ""  CGW,LCA,LDWS_LKAS,SCC,TPMS
 SG_ CF_Gway_WPCNValueSet : 40|2@1+ (1,0) [0|3] ""  CGW
 SG_ CF_Clu_ECoastWarnNValueSet : 44|2@1+ (1,0) [0|3] ""  CGW
 SG_ CF_Clu_AuxBatChargeNValueSet : 46|2@1+ (1,0) [0|3] ""  CGW
 SG_ CF_Clu_ECoastCtrlNValueSet : 56|3@1+ (1,0) [0|7] ""  CGW

BO_ 1427 TPMS11: 6 TPMS
 SG_ TPMS_W_LAMP : 0|2@1+ (1,0) [0|3] ""  CGW,CLU
 SG_ TREAD_W_LAMP : 2|2@1+ (1,0) [0|3] ""  CGW,CLU
 SG_ POS_FL_W_LAMP : 4|1@1+ (1,0) [0|1] ""  CGW,CLU
 SG_ POS_FR_W_LAMP : 5|1@1+ (1,0) [0|1] ""  CGW,CLU
 SG_ POS_RL_W_LAMP : 6|1@1+ (1,0) [0|1] ""  CGW,CLU
 SG_ POS_RR_W_LAMP : 7|1@1+ (1,0) [0|1] ""  CGW,CLU
 SG_ STATUS_TPMS : 8|3@1+ (1,0) [0|7] ""  CLU
 SG_ UNIT : 11|2@1+ (1,0) [0|3] ""  CLU
 SG_ PRESSURE_FL : 16|8@1+ (1,0) [0|255] ""  CLU
 SG_ PRESSURE_FR : 24|8@1+ (1,0) [0|255] ""  CLU
 SG_ PRESSURE_RL : 32|8@1+ (1,0) [0|255] ""  CLU
 SG_ PRESSURE_RR : 40|8@1+ (1,0) [0|255] ""  CLU

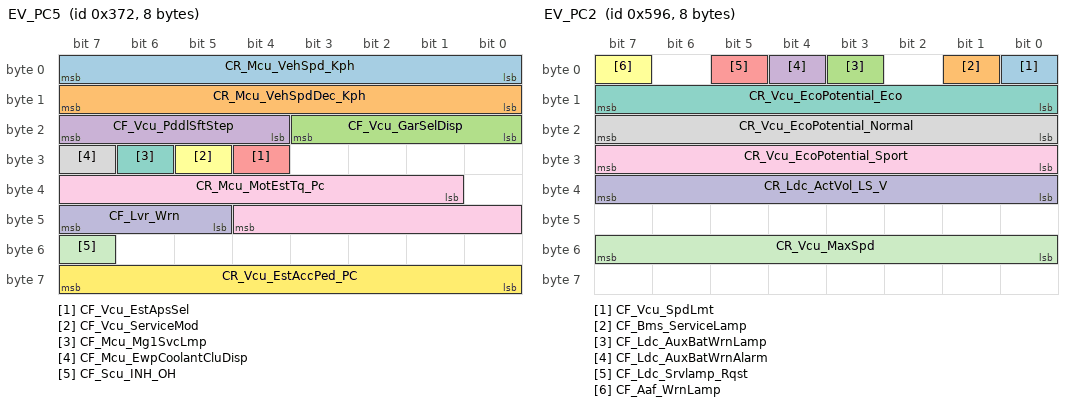
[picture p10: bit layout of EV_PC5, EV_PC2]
BO_ 882 EV_PC5: 8 CGW
 SG_ CR_Mcu_VehSpd_Kph : 0|8@1+ (1,0) [0|255] "kph"  LCA,LDWS_LKAS,MDPS
 SG_ CR_Mcu_VehSpdDec_Kph : 8|8@1+ (0.0078125,0) [0|0.99] "kph"  CLU
 SG_ CF_Vcu_GarSelDisp : 16|4@1+ (1,0) [0|15] ""  AFLS,CLU,EPB,LCA,LDWS_LKAS,MDPS,SCC,TPMS
 SG_ CF_Vcu_PddlSftStep : 20|4@1+ (1,0) [0|15] ""  CLU
 SG_ CF_Vcu_EstApsSel : 28|1@1+ (1,0) [0|1] ""  CLU
 SG_ CF_Vcu_ServiceMod : 29|1@1+ (1,0) [0|1] ""  CLU
 SG_ CF_Mcu_Mg1SvcLmp : 30|1@1+ (1,0) [0|1] ""  CLU
 SG_ CF_Mcu_EwpCoolantCluDisp : 31|1@1+ (1,0) [0|1] "flag"  CLU
 SG_ CR_Mcu_MotEstTq_Pc : 33|12@1- (0.048828125,0) [-100|99.9511718] "%"  CLU,EPB
 SG_ CF_Lvr_Wrn : 45|3@1+ (1,0) [0|7] ""  CLU
 SG_ CF_Scu_INH_OH : 55|1@1+ (1,0) [0|1] ""  CLU
 SG_ CR_Vcu_EstAccPed_PC : 56|8@1+ (0.3906,0) [0|99.61] "%"  CLU

BO_ 1425 AFLS11: 2 AFLS
 SG_ AFLS_STAT : 1|2@1+ (1,0) [0|3] ""  CLU

BO_ 339 TCS11: 8 iBAU
 SG_ TCS_REQ : 0|1@1+ (1,0) [0|1] ""  EPB
 SG_ MSR_C_REQ : 1|1@1+ (1,0) [0|1] ""  EPB
 SG_ TCS_PAS : 2|1@1+ (1,0) [0|1] ""  CLU,SCC
 SG_ TCS_GSC : 3|1@1+ (1,0) [0|1] ""  Vector__XXX
 SG_ CF_Esc_LimoInfo : 4|2@1+ (1,0) [0|3] ""  Vector__XXX
 SG_ ABS_DIAG : 6|1@1+ (1,0) [0|1] ""  CLU,EPB
 SG_ ABS_DEF : 7|1@1+ (1,0) [0|1] ""  EPB
 SG_ TCS_DEF : 8|1@1+ (1,0) [0|1] ""  EPB
 SG_ TCS_CTL : 9|1@1+ (1,0) [0|1] ""  EPB,MDPS,SCC
 SG_ ABS_ACT : 10|1@1+ (1,0) [0|1] ""  EPB,LDWS_LKAS,SCC
 SG_ EBD_DEF : 11|1@1+ (1,0) [0|1] ""  EPB
 SG_ ESP_PAS : 12|1@1+ (1,0) [0|1] ""  CLU,EPB,LDWS_LKAS,SCC
 SG_ ESP_DEF : 13|1@1+ (1,0) [0|1] ""  EPB,LDWS_LKAS
 SG_ ESP_CTL : 14|1@1+ (1,0) [0|1] ""  EPB,LDWS_LKAS,SCC
 SG_ TCS_MFRN : 15|1@1+ (1,0) [0|1] ""  EPB
 SG_ DBC_CTL : 16|1@1+ (1,0) [0|1] ""  EPB
 SG_ DBC_PAS : 17|1@1+ (1,0) [0|1] ""  EPB
 SG_ DBC_DEF : 18|1@1+ (1,0) [0|1] ""  EPB
 SG_ HAC_CTL : 19|1@1+ (1,0) [0|1] ""  CLU,EPB
 SG_ HAC_PAS : 20|1@1+ (1,0) [0|1] ""  CLU,EPB
 SG_ HAC_DEF : 21|1@1+ (1,0) [0|1] ""  CLU,EPB
 SG_ ESS_STAT : 22|2@1+ (1,0) [0|3] ""  CLU,EPB
 SG_ TQI_TCS : 24|8@1+ (0.390625,0) [0|99.609375] "%"  EPB
 SG_ TQI_MSR : 32|8@1+ (0.390625,0) [0|99.609375] "%"  EPB
 SG_ TQI_SLW_TCS : 40|8@1+ (0.390625,0) [0|99.609375] "%"  EPB
 SG_ CF_Esc_BrkCtl : 48|1@1+ (1,0) [0|1] ""  Vector__XXX
 SG_ CF_Brk_AbsNReq : 49|1@1+ (1,0) [0|1] ""  Vector__XXX
 SG_ BLA_CTL : 50|2@1+ (1,0) [0|3] ""  CGW
 SG_ AliveCounter_TCS1 : 52|4@1+ (1,0) [0|14] ""  EPB,LDWS_LKAS,MDPS,SCC
 SG_ CheckSum_TCS1 : 56|8@1+ (1,0) [0|255] ""  EPB,LDWS_LKAS,MDPS,SCC

BO_ 1430 EV_PC2: 8 CGW
 SG_ CF_Vcu_SpdLmt : 0|1@1+ (1,0) [0|1] ""  CLU
 SG_ CF_Bms_ServiceLamp : 1|1@1+ (1,0) [0|1] ""  CLU
 SG_ CF_Ldc_AuxBatWrnLamp : 3|1@1+ (1,0) [0|1] ""  CLU
 SG_ CF_Ldc_AuxBatWrnAlarm : 4|1@1+ (1,0) [0|1] ""  CLU
 SG_ CF_Ldc_Srvlamp_Rqst : 5|1@1+ (1,0) [0|1] ""  CLU
 SG_ CF_Aaf_WrnLamp : 7|1@1+ (1,0) [0|1] ""  CLU
 SG_ CR_Vcu_EcoPotential_Eco : 8|8@1+ (0.5,0) [0|100] "%"  CLU
 SG_ CR_Vcu_EcoPotential_Normal : 16|8@1+ (0.5,0) [0|100] "%"  CLU
 SG_ CR_Vcu_EcoPotential_Sport : 24|8@1+ (0.5,0) [0|100] "%"  CLU
 SG_ CR_Ldc_ActVol_LS_V : 32|8@1+ (0.1,0) [0|25.5] "V"  EPB
 SG_ CR_Vcu_MaxSpd : 48|8@1+ (1,0) [0|255] "kph"  CLU

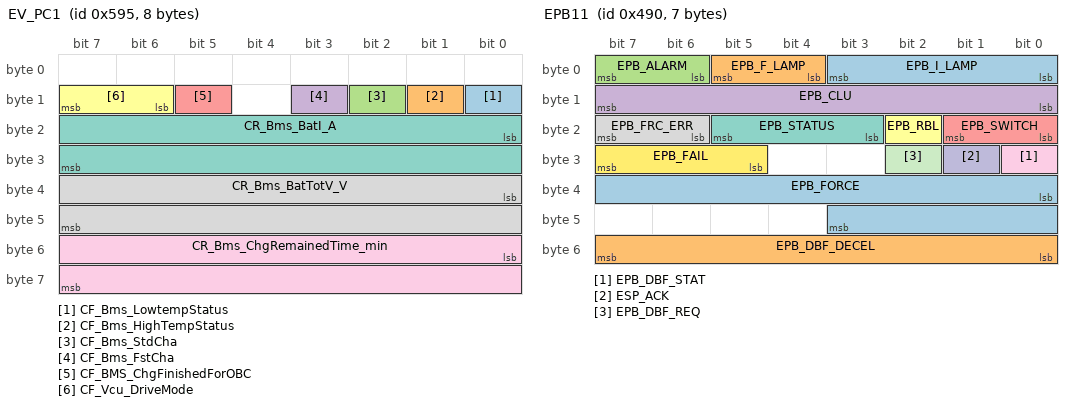
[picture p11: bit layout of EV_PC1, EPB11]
BO_ 1429 EV_PC1: 8 CGW
 SG_ CF_Bms_LowtempStatus : 8|1@1+ (1,0) [0|1] ""  CLU
 SG_ CF_Bms_HighTempStatus : 9|1@1+ (1,0) [0|1] "flag"  CLU
 SG_ CF_Bms_StdCha : 10|1@1+ (1,0) [0|1] ""  CLU
 SG_ CF_Bms_FstCha : 11|1@1+ (1,0) [0|1] ""  CLU
 SG_ CF_BMS_ChgFinishedForOBC : 13|1@1+ (1,0) [0|1] ""  CLU
 SG_ CF_Vcu_DriveMode : 14|2@1+ (1,0) [0|3] ""  CLU
 SG_ CR_Bms_BatI_A : 16|16@1- (0.1,0) [-500|500] "A"  CLU
 SG_ CR_Bms_BatTotV_V : 32|16@1+ (0.1,0) [0|500] "V"  CLU
 SG_ CR_Bms_ChgRemainedTime_min : 48|16@1+ (1,0) [0|65535] "min"  CLU

BO_ 1301 CLU14: 8 CLU
 SG_ CF_Clu_ADrUNValueSet : 0|3@1+ (1,0) [0|7] ""  CGW
 SG_ CF_Clu_ADrLNValueSet : 3|3@1+ (1,0) [0|7] ""  CGW
 SG_ CF_Clu_EscortHLNValueSet : 6|2@1+ (1,0) [0|3] ""  CGW
 SG_ CF_Clu_DoorLSNValueSet : 8|3@1+ (1,0) [0|7] ""  Vector__XXX
 SG_ CF_Clu_PSMNValueSet : 11|3@1+ (1,0) [0|7] ""  CGW
 SG_ CF_Clu_TTUnlockNValueSet : 14|2@1+ (1,0) [0|3] ""  CGW
 SG_ CF_Clu_ATTurnNValueSet : 16|2@1+ (1,0) [0|3] ""  Vector__XXX
 SG_ CF_Clu_SCMNValueSet : 18|2@1+ (1,0) [0|3] ""  Vector__XXX
 SG_ CF_Clu_WlightNValueSet : 20|2@1+ (1,0) [0|3] ""  CGW
 SG_ CF_Clu_TempUnitNValueSet : 22|2@1+ (1,0) [0|3] ""  CGW
 SG_ CF_Clu_TrfChgSet : 27|2@1+ (1,0) [0|3] ""  Vector__XXX
 SG_ CF_Clu_OTTurnNValueSet : 29|3@1+ (1,0) [0|7] ""  CGW
 SG_ CF_Clu_LcaNValueSet : 32|2@1+ (1,0) [0|3] ""  LCA
 SG_ CF_Clu_RctaNValueSet : 34|2@1+ (1,0) [0|3] ""  LCA
 SG_ CF_Clu_RcwNValueSet : 36|2@1+ (1,0) [0|3] ""  Vector__XXX
 SG_ CF_Clu_EcsOffNValueSet : 38|3@1+ (1,0) [0|3] ""  iBAU
 SG_ CF_Clu_SccNaviCrvNValueSet : 41|2@1+ (1,0) [0|3] ""  Vector__XXX
 SG_ CF_Clu_SccNaviCamNValueSet : 43|2@1+ (1,0) [0|3] ""  SCC
 SG_ CF_Clu_SccAebNValueSet : 45|2@1+ (1,0) [0|3] ""  SCC
 SG_ CF_Clu_LkasModeNValueSet : 47|2@1+ (1,0) [0|3] ""  LDWS_LKAS
 SG_ CF_Clu_FcwNValueSet : 51|2@1+ (1,0) [0|3] ""  Vector__XXX
 SG_ CF_Clu_PasSpkrLvNValueSet : 53|3@1+ (1,0) [0|7] ""  CGW
 SG_ CF_Clu_SccDrvModeNValueSet : 56|3@1+ (1,0) [0|7] ""  SCC
 SG_ CF_Clu_HAnBNValueSet : 59|2@1+ (1,0) [0|3] ""  CGW
 SG_ CF_Clu_HfreeTrunkTgNValueSet : 61|3@1+ (1,0) [0|7] ""  CGW

BO_ 1168 EPB11: 7 EPB
 SG_ EPB_I_LAMP : 0|4@1+ (1,0) [0|15] ""  CGW,CLU,iBAU
 SG_ EPB_F_LAMP : 4|2@1+ (1,0) [0|3] ""  CGW,CLU,iBAU
 SG_ EPB_ALARM : 6|2@1+ (1,0) [0|3] ""  CLU,iBAU
 SG_ EPB_CLU : 8|8@1+ (1,0) [0|255] ""  CLU,iBAU
 SG_ EPB_SWITCH : 16|2@1+ (1,0) [0|3] ""  iBAU
 SG_ EPB_RBL : 18|1@1+ (1,0) [0|1] ""  iBAU
 SG_ EPB_STATUS : 19|3@1+ (1,0) [0|7] ""  CGW,iBAU
 SG_ EPB_FRC_ERR : 22|2@1+ (1,0) [0|3] ""  iBAU
 SG_ EPB_DBF_STAT : 24|1@1+ (1,0) [0|1] ""  iBAU
 SG_ ESP_ACK : 25|1@1+ (1,0) [0|1] ""  iBAU
 SG_ EPB_DBF_REQ : 26|1@1+ (1,0) [0|1] ""  iBAU
 SG_ EPB_FAIL : 29|3@1+ (1,0) [0|7] ""  iBAU
 SG_ EPB_FORCE : 32|12@1+ (1,-1000) [-1000|3000] ""  iBAU
 SG_ EPB_DBF_DECEL : 48|8@1+ (0.01,0) [0|2.54] "g"  iBAU

BO_ 1290 SCC13: 8 SCC
 SG_ SCCDrvModeRValue : 0|3@1+ (1,0) [0|7] ""  CLU
 SG_ SCC_Equip : 3|1@1+ (1,0) [0|1] ""  iBAU
 SG_ AebDrvSetStatus : 4|3@1+ (1,0) [0|3] ""  CLU,iBAU

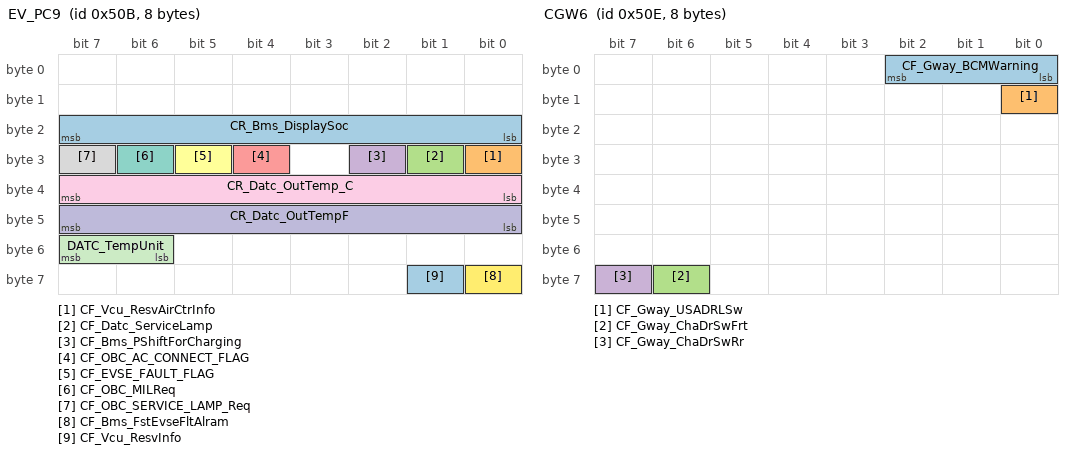
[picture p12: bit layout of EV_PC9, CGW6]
BO_ 1291 EV_PC9: 8 CGW
 SG_ CR_Bms_DisplaySoc : 16|8@1+ (0.5,0) [0|100] "%"  CLU
 SG_ CF_Vcu_ResvAirCtrInfo : 24|1@1+ (1,0) [0|1] ""  CLU
 SG_ CF_Datc_ServiceLamp : 25|1@1+ (1,0) [0|1] ""  CLU
 SG_ CF_Bms_PShiftForCharging : 26|1@1+ (1,0) [0|1] "flag"  CLU
 SG_ CF_OBC_AC_CONNECT_FLAG : 28|1@1+ (1,0) [0|1] ""  CLU
 SG_ CF_EVSE_FAULT_FLAG : 29|1@1+ (1,0) [0|1] ""  CLU
 SG_ CF_OBC_MILReq : 30|1@1+ (1,0) [0|1] ""  CLU
 SG_ CF_OBC_SERVICE_LAMP_Req : 31|1@1+ (1,0) [0|1] ""  CLU
 SG_ CR_Datc_OutTemp_C : 32|8@1+ (0.5,-41) [-41|86.5] "℃"  CLU,TPMS
 SG_ CR_Datc_OutTempF : 40|8@1+ (1,-42) [-42|213] "℃"  CLU
 SG_ DATC_TempUnit : 54|2@1+ (1,0) [0|3] "flag"  CLU
 SG_ CF_Bms_FstEvseFltAlram : 56|1@1+ (1,0) [0|1] "flag"  CLU
 SG_ CF_Vcu_ResvInfo : 57|1@1+ (1,0) [0|1] ""  CLU

BO_ 1294 CGW6: 8 CGW
 SG_ CF_Gway_BCMWarning : 0|3@1+ (1,0) [0|7] ""  CLU
 SG_ CF_Gway_USADRLSw : 8|1@1+ (1,0) [0|0] ""  CLU
 SG_ CF_Gway_ChaDrSwFrt : 62|1@1+ (1,0) [0|0] ""  CLU
 SG_ CF_Gway_ChaDrSwRr : 63|1@1+ (1,0) [0|0] ""  CLU

BO_ 1173 YRS13: 8 ACU
 SG_ YRS_SeralNo : 16|48@1+ (1,0) [0|281474976710655] ""  iBAU

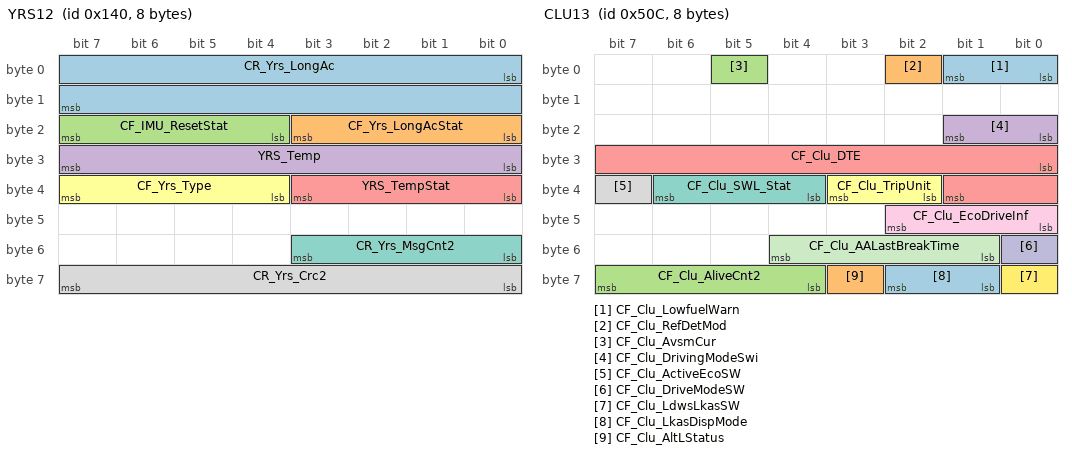
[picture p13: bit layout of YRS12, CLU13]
BO_ 320 YRS12: 8 ACU
 SG_ CR_Yrs_LongAc : 0|16@1+ (1.27465E-4,-4.17677312) [-4.17677312|4.17651819] "g"  iBAU
 SG_ CF_Yrs_LongAcStat : 16|4@1+ (1,0) [0|15] ""  iBAU
 SG_ CF_IMU_ResetStat : 20|4@1+ (1,0) [0|15] ""  iBAU
 SG_ YRS_Temp : 24|8@1+ (1,-68) [-68|187] "℃"  iBAU
 SG_ YRS_TempStat : 32|4@1+ (1,0) [0|15] ""  iBAU
 SG_ CF_Yrs_Type : 36|4@1+ (1,0) [0|15] ""  iBAU
 SG_ CR_Yrs_MsgCnt2 : 48|4@1+ (1,0) [0|15] ""  iBAU
 SG_ CR_Yrs_Crc2 : 56|8@1+ (1,0) [0|255] ""  iBAU

BO_ 1292 CLU13: 8 CLU
 SG_ CF_Clu_LowfuelWarn : 0|2@1+ (1,0) [0|3] ""  CGW
 SG_ CF_Clu_RefDetMod : 2|1@1+ (1,0) [0|1] ""  CGW
 SG_ CF_Clu_AvsmCur : 5|1@1+ (1,0) [0|1] ""  iBAU
 SG_ CF_Clu_DrivingModeSwi : 16|2@1+ (1,0) [0|3] ""  LDWS_LKAS,MDPS,iBAU
 SG_ CF_Clu_DTE : 24|10@1+ (1,0) [0|1023] ""  Vector__XXX
 SG_ CF_Clu_TripUnit : 34|2@1+ (1,0) [0|3] ""  Vector__XXX
 SG_ CF_Clu_SWL_Stat : 36|3@1+ (1,0) [0|7] ""  ACU
 SG_ CF_Clu_ActiveEcoSW : 39|1@1+ (1,0) [0|1] ""  CGW
 SG_ CF_Clu_EcoDriveInf : 40|3@1+ (1,0) [0|7] ""  Vector__XXX
 SG_ CF_Clu_DriveModeSW : 48|1@1+ (1,0) [0|1] ""  CGW
 SG_ CF_Clu_AALastBreakTime : 49|4@1+ (1,0) [0|15] ""  LDWS_LKAS
 SG_ CF_Clu_LdwsLkasSW : 56|1@1+ (1,0) [0|1] ""  Vector__XXX
 SG_ CF_Clu_LkasDispMode : 57|2@1+ (1,0) [0|3] ""  Vector__XXX
 SG_ CF_Clu_AltLStatus : 59|1@1+ (1,0) [0|1] ""  CGW
 SG_ CF_Clu_AliveCnt2 : 60|4@1+ (1,0) [0|15] ""  LDWS_LKAS

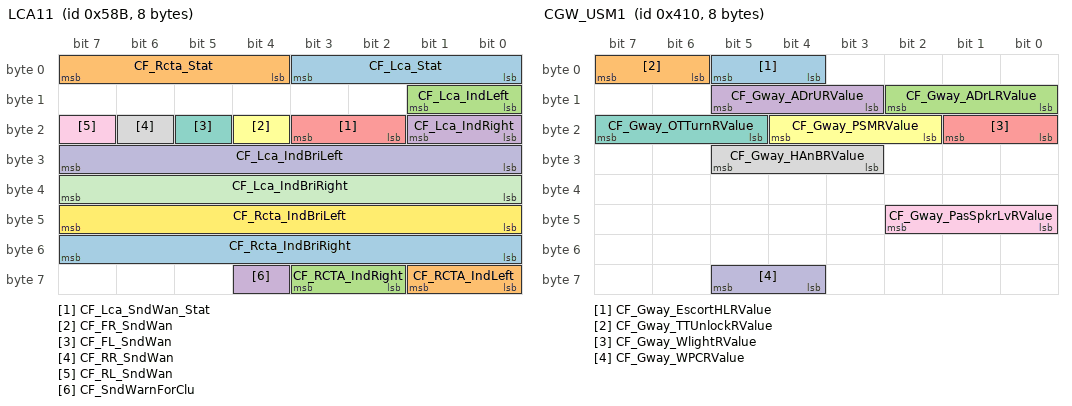
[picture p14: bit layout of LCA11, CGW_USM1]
BO_ 1419 LCA11: 8 LCA
 SG_ CF_Lca_Stat : 0|4@1+ (1,0) [0|15] ""  CLU
 SG_ CF_Rcta_Stat : 4|4@1+ (1,0) [0|15] ""  CLU
 SG_ CF_Lca_IndLeft : 8|2@1+ (1,0) [0|3] ""  CLU
 SG_ CF_Lca_IndRight : 16|2@1+ (1,0) [0|3] ""  CLU
 SG_ CF_Lca_SndWan_Stat : 18|2@1+ (1,0) [0|3] ""  CLU
 SG_ CF_FR_SndWan : 20|1@1+ (1,0) [0|1] ""  CGW,CLU
 SG_ CF_FL_SndWan : 21|1@1+ (1,0) [0|1] ""  CGW,CLU
 SG_ CF_RR_SndWan : 22|1@1+ (1,0) [0|1] ""  CGW,CLU
 SG_ CF_RL_SndWan : 23|1@1+ (1,0) [0|1] ""  CGW,CLU
 SG_ CF_Lca_IndBriLeft : 24|8@1+ (1,0) [0|255] ""  CLU
 SG_ CF_Lca_IndBriRight : 32|8@1+ (1,0) [0|255] ""  CLU
 SG_ CF_Rcta_IndBriLeft : 40|8@1+ (1,0) [0|255] ""  CLU
 SG_ CF_Rcta_IndBriRight : 48|8@1+ (1,0) [0|255] ""  CLU
 SG_ CF_RCTA_IndLeft : 56|2@1+ (1,0) [0|3] ""  CLU
 SG_ CF_RCTA_IndRight : 58|2@1+ (1,0) [0|3] ""  CLU
 SG_ CF_SndWarnForClu : 60|1@1+ (1,0) [0|1] ""  CLU

BO_ 1040 CGW_USM1: 8 CGW
 SG_ CF_Gway_EscortHLRValue : 4|2@1+ (1,0) [0|3] ""  CLU
 SG_ CF_Gway_TTUnlockRValue : 6|2@1+ (1,0) [0|3] ""  CLU
 SG_ CF_Gway_ADrLRValue : 8|3@1+ (1,0) [0|7] ""  CLU
 SG_ CF_Gway_ADrURValue : 11|3@1+ (1,0) [0|7] ""  CLU
 SG_ CF_Gway_WlightRValue : 16|2@1+ (1,0) [0|3] ""  CLU
 SG_ CF_Gway_PSMRValue : 18|3@1+ (1,0) [0|7] ""  CLU
 SG_ CF_Gway_OTTurnRValue : 21|3@1+ (1,0) [0|7] ""  CLU
 SG_ CF_Gway_HAnBRValue : 27|3@1+ (1,0) [0|7] ""  CLU
 SG_ CF_Gway_PasSpkrLvRValue : 40|3@1+ (1,0) [0|7] ""  CLU
 SG_ CF_Gway_WPCRValue : 60|2@1+ (1,0) [0|3] ""  CLU

BO_ 1280 ACU14: 1 ACU
 SG_ CF_SWL_Ind : 0|2@1+ (1,0) [0|3] ""  CLU
 SG_ CF_TTL_Ind : 2|2@1+ (1,0) [0|3] ""  Vector__XXX

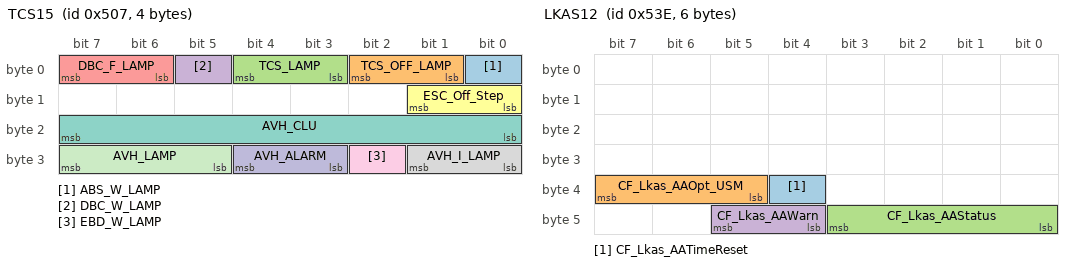
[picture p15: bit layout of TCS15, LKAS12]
BO_ 1287 TCS15: 4 iBAU
 SG_ ABS_W_LAMP : 0|1@1+ (1,0) [0|1] ""  CLU
 SG_ TCS_OFF_LAMP : 1|2@1+ (1,0) [0|1] ""  CLU
 SG_ TCS_LAMP : 3|2@1+ (1,0) [0|3] ""  CLU,SCC
 SG_ DBC_W_LAMP : 5|1@1+ (1,0) [0|1] ""  CLU
 SG_ DBC_F_LAMP : 6|2@1+ (1,0) [0|3] ""  CLU
 SG_ ESC_Off_Step : 8|2@1+ (1,0) [0|3] ""  CLU
 SG_ AVH_CLU : 16|8@1+ (1,0) [0|255] ""  CLU,EPB
 SG_ AVH_I_LAMP : 24|2@1+ (1,0) [0|3] ""  EPB
 SG_ EBD_W_LAMP : 26|1@1+ (1,0) [0|1] ""  CLU
 SG_ AVH_ALARM : 27|2@1+ (1,0) [0|3] ""  CLU
 SG_ AVH_LAMP : 29|3@1+ (1,0) [0|7] ""  CLU,EPB

BO_ 1456 CLU12: 4 CLU
 SG_ CF_Clu_Odometer : 0|24@1+ (0.1,0) [0|1677721.5] "km"  CGW,EPB,SCC

BO_ 1342 LKAS12: 6 LDWS_LKAS
 SG_ CF_Lkas_AATimeReset : 36|1@1+ (1,0) [0|1] ""  CLU
 SG_ CF_Lkas_AAOpt_USM : 37|3@1+ (1,0) [0|7] ""  CLU
 SG_ CF_Lkas_AAStatus : 40|4@1+ (1,0) [0|15] ""  CLU
 SG_ CF_Lkas_AAWarn : 44|2@1+ (1,0) [0|3] ""  CLU

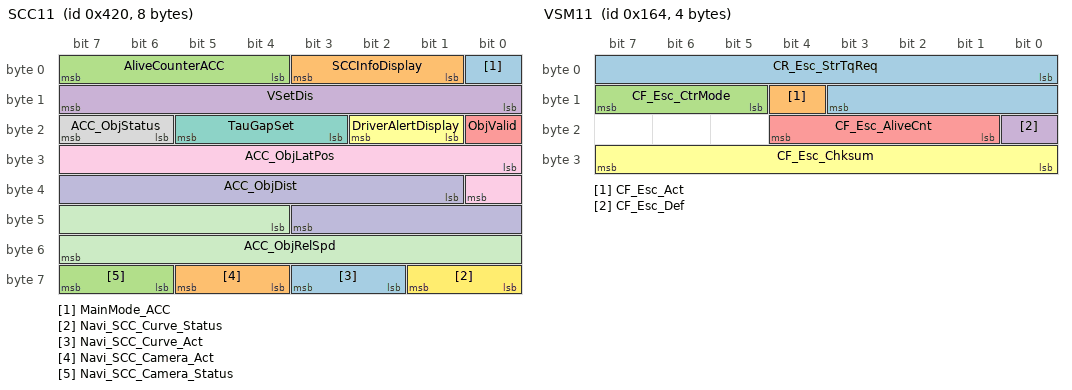
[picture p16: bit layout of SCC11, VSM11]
BO_ 1056 SCC11: 8 SCC
 SG_ MainMode_ACC : 0|1@1+ (1,0) [0|1] ""  CLU,iBAU
 SG_ SCCInfoDisplay : 1|3@1+ (1,0) [0|7] ""  CLU,iBAU
 SG_ AliveCounterACC : 4|4@1+ (1,0) [0|15] ""  CLU,iBAU
 SG_ VSetDis : 8|8@1+ (1,0) [0|255] "km/h or MPH"  CLU,iBAU
 SG_ ObjValid : 16|1@1+ (1,0) [0|1] ""  CGW,CLU,iBAU
 SG_ DriverAlertDisplay : 17|2@1+ (1,0) [0|3] ""  CLU,iBAU
 SG_ TauGapSet : 19|3@1+ (1,0) [0|7] ""  CLU,iBAU
 SG_ ACC_ObjStatus : 22|2@1+ (1,0) [0|3] ""  CGW,iBAU
 SG_ ACC_ObjLatPos : 24|9@1+ (0.1,-20) [-20|31.1] "m"  iBAU
 SG_ ACC_ObjDist : 33|11@1+ (0.1,0) [0|204.7] "m"  CGW,iBAU
 SG_ ACC_ObjRelSpd : 44|12@1+ (0.1,-170) [-170|239.5] "m/s"  CGW,iBAU
 SG_ Navi_SCC_Curve_Status : 56|2@1+ (1,0) [0|3] ""  Vector__XXX
 SG_ Navi_SCC_Curve_Act : 58|2@1+ (1,0) [0|3] ""  Vector__XXX
 SG_ Navi_SCC_Camera_Act : 60|2@1+ (1,0) [0|3] ""  CLU
 SG_ Navi_SCC_Camera_Status : 62|2@1+ (1,0) [0|3] ""  CLU

BO_ 1057 SCC12: 8 SCC
 SG_ CF_VSM_Prefill : 0|1@1+ (1,0) [0|1] ""  iBAU
 SG_ CF_VSM_DecCmdAct : 1|1@1+ (1,0) [0|1] ""  iBAU
 SG_ CF_VSM_HBACmd : 2|2@1+ (1,0) [0|3] ""  iBAU
 SG_ CF_VSM_Warn : 4|2@1+ (1,0) [0|3] ""  CLU,iBAU
 SG_ CF_VSM_Stat : 6|2@1+ (1,0) [0|3] ""  iBAU
 SG_ CF_VSM_BeltCmd : 8|3@1+ (1,0) [0|7] ""  iBAU
 SG_ ACCFailInfo : 11|2@1+ (1,0) [0|3] ""  CGW,CLU,iBAU
 SG_ ACCMode : 13|2@1+ (1,0) [0|3] ""  CGW,CLU,iBAU
 SG_ StopReq : 15|1@1+ (1,0) [0|1] ""  EPB,iBAU
 SG_ CR_VSM_DecCmd : 16|8@1+ (0.01,0) [0|2.55] "g"  iBAU
 SG_ aReqMax : 24|11@1+ (0.01,-10.23) [-10.23|10.24] "m/s^2"  iBAU
 SG_ TakeOverReq : 35|1@1+ (1,0) [0|1] ""  CLU,iBAU
 SG_ PreFill : 36|1@1+ (1,0) [0|1] ""  iBAU
 SG_ aReqMin : 37|11@1+ (0.01,-10.23) [-10.23|10.24] "m/s^2"  iBAU
 SG_ CF_VSM_ConfMode : 48|2@1+ (1,0) [0|3] ""  iBAU
 SG_ AEB_Failinfo : 50|2@1+ (1,0) [0|3] ""  CLU,iBAU
 SG_ AEB_Status : 52|2@1+ (1,0) [0|3] ""  CLU,iBAU
 SG_ AEB_CmdAct : 54|1@1+ (1,0) [0|1] ""  iBAU
 SG_ AEB_StopReq : 55|1@1+ (1,0) [0|1] ""  CLU,iBAU
 SG_ CR_VSM_Alive : 56|4@1+ (1,0) [0|15] ""  iBAU
 SG_ CR_VSM_ChkSum : 60|4@1+ (1,0) [0|15] ""  iBAU

BO_ 1470 HU_CLU_PE_05: 8 CGW
 SG_ HU_NaviStatus : 2|2@1+ (1,0) [0|3] ""  SCC
 SG_ HU_NaviCamSettingStatus : 24|8@1+ (1,0) [0|255] ""  SCC

BO_ 356 VSM11: 4 iBAU
 SG_ CR_Esc_StrTqReq : 0|12@1+ (0.01,-20.48) [-20.48|20.47] "Nm"  MDPS
 SG_ CF_Esc_Act : 12|1@1+ (1,0) [0|1] ""  LDWS_LKAS,MDPS
 SG_ CF_Esc_CtrMode : 13|3@1+ (1,0) [0|7] ""  MDPS
 SG_ CF_Esc_Def : 16|1@1+ (1,0) [0|1] ""  MDPS
 SG_ CF_Esc_AliveCnt : 17|4@1+ (1,0) [0|15] ""  LDWS_LKAS,MDPS
 SG_ CF_Esc_Chksum : 24|8@1+ (1,0) [0|255] ""  MDPS

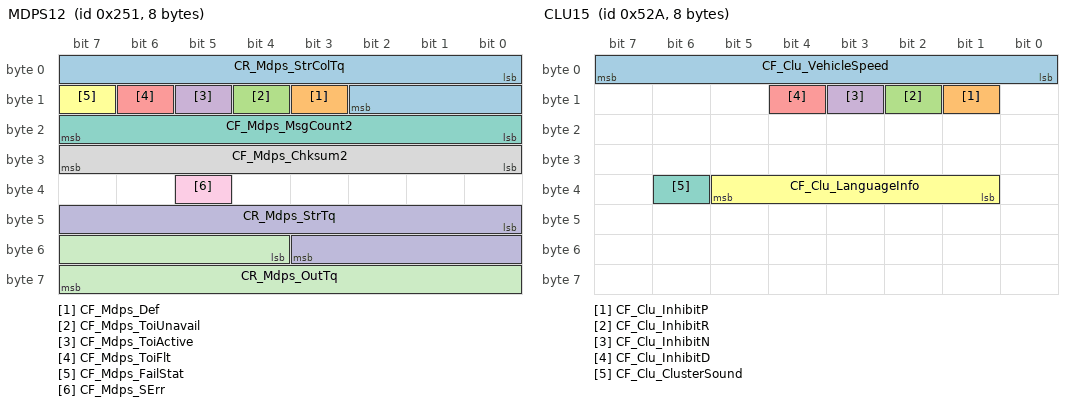
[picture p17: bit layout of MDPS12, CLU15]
BO_ 593 MDPS12: 8 MDPS
 SG_ CR_Mdps_StrColTq : 0|11@1+ (0.0078125,-8) [-8|7.9921875] "Nm"  LDWS_LKAS
 SG_ CF_Mdps_Def : 11|1@1+ (1,0) [0|1] ""  iBAU
 SG_ CF_Mdps_ToiUnavail : 12|1@1+ (1,0) [0|1] ""  LDWS_LKAS
 SG_ CF_Mdps_ToiActive : 13|1@1+ (1,0) [0|1] ""  LDWS_LKAS
 SG_ CF_Mdps_ToiFlt : 14|1@1+ (1,0) [0|1] ""  LDWS_LKAS
 SG_ CF_Mdps_FailStat : 15|1@1+ (1,0) [0|1] ""  LDWS_LKAS
 SG_ CF_Mdps_MsgCount2 : 16|8@1+ (1,0) [0|255] ""  LDWS_LKAS,iBAU
 SG_ CF_Mdps_Chksum2 : 24|8@1+ (1,0) [0|255] ""  LDWS_LKAS,iBAU
 SG_ CF_Mdps_SErr : 37|1@1+ (1,0) [0|1] ""  iBAU
 SG_ CR_Mdps_StrTq : 40|12@1+ (0.01,-20.48) [-20.48|20.47] "Nm"  iBAU
 SG_ CR_Mdps_OutTq : 52|12@1+ (0.1,-204.8) [-204.8|204.7] ""  LDWS_LKAS,iBAU

BO_ 1322 CLU15: 8 CLU
 SG_ CF_Clu_VehicleSpeed : 0|8@1+ (1,0) [0|255] ""  CGW
 SG_ CF_Clu_InhibitP : 9|1@1+ (1,0) [0|1] ""  Vector__XXX
 SG_ CF_Clu_InhibitR : 10|1@1+ (1,0) [0|1] ""  Vector__XXX
 SG_ CF_Clu_InhibitN : 11|1@1+ (1,0) [0|1] ""  Vector__XXX
 SG_ CF_Clu_InhibitD : 12|1@1+ (1,0) [0|1] ""  Vector__XXX
 SG_ CF_Clu_LanguageInfo : 33|5@1+ (1,0) [0|31] ""  PGS
 SG_ CF_Clu_ClusterSound : 38|1@1- (1,0) [0|0] ""  Vector__XXX

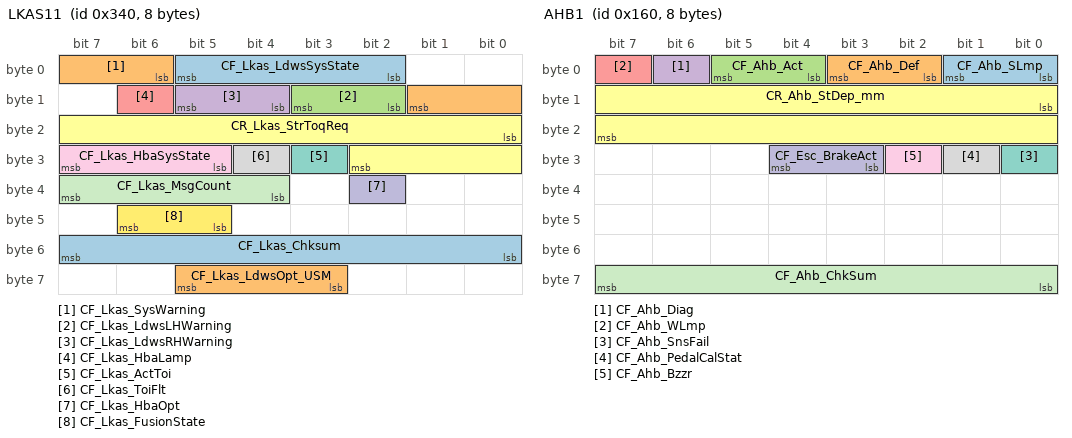
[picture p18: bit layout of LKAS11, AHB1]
BO_ 832 LKAS11: 8 LDWS_LKAS
 SG_ CF_Lkas_LdwsSysState : 2|4@1+ (1,0) [0|15] ""  CGW,CLU
 SG_ CF_Lkas_SysWarning : 6|4@1+ (1,0) [0|15] ""  CLU
 SG_ CF_Lkas_LdwsLHWarning : 10|2@1+ (1,0) [0|3] ""  CGW,CLU
 SG_ CF_Lkas_LdwsRHWarning : 12|2@1+ (1,0) [0|3] ""  CGW,CLU
 SG_ CF_Lkas_HbaLamp : 14|1@1+ (1,0) [0|1] ""  CLU
 SG_ CR_Lkas_StrToqReq : 16|11@1+ (0.0078125,-8) [-8|8] "Nm"  MDPS
 SG_ CF_Lkas_ActToi : 27|1@1+ (1,0) [0|1] ""  MDPS
 SG_ CF_Lkas_ToiFlt : 28|1@1+ (1,0) [0|1] ""  MDPS
 SG_ CF_Lkas_HbaSysState : 29|3@1+ (1,0) [0|7] ""  CGW,CLU
 SG_ CF_Lkas_HbaOpt : 34|1@1+ (1,0) [0|1] ""  CGW,CLU
 SG_ CF_Lkas_MsgCount : 36|4@1+ (1,0) [0|15] ""  MDPS,SCC
 SG_ CF_Lkas_FusionState : 45|2@1+ (1,0) [0|3] ""  SCC
 SG_ CF_Lkas_Chksum : 48|8@1+ (1,0) [0|255] ""  MDPS,SCC
 SG_ CF_Lkas_LdwsOpt_USM : 59|3@1+ (1,0) [0|7] ""  CLU,MDPS

BO_ 352 AHB1: 8 iBAU
 SG_ CF_Ahb_SLmp : 0|2@1+ (1,0) [0|3] ""  CLU
 SG_ CF_Ahb_Def : 2|2@1+ (1,0) [0|3] ""  CGW
 SG_ CF_Ahb_Act : 4|2@1+ (1,0) [0|3] ""  Vector__XXX
 SG_ CF_Ahb_Diag : 6|1@1+ (1,0) [0|1] ""  Vector__XXX
 SG_ CF_Ahb_WLmp : 7|1@1+ (1,0) [0|1] ""  CLU
 SG_ CR_Ahb_StDep_mm : 8|16@1- (0.1,0) [-3276.8|3276.7] "mm"  Vector__XXX
 SG_ CF_Ahb_SnsFail : 24|1@1+ (1,0) [0|1] ""  Vector__XXX
 SG_ CF_Ahb_PedalCalStat : 25|1@1+ (1,0) [0|1] ""  Vector__XXX
 SG_ CF_Ahb_Bzzr : 26|1@1+ (1,0) [0|1] ""  CLU
 SG_ CF_Esc_BrakeAct : 27|2@1+ (1,0) [0|3] ""  CGW,EPB
 SG_ CF_Ahb_ChkSum : 56|8@1+ (1,0) [0|255] ""  Vector__XXX

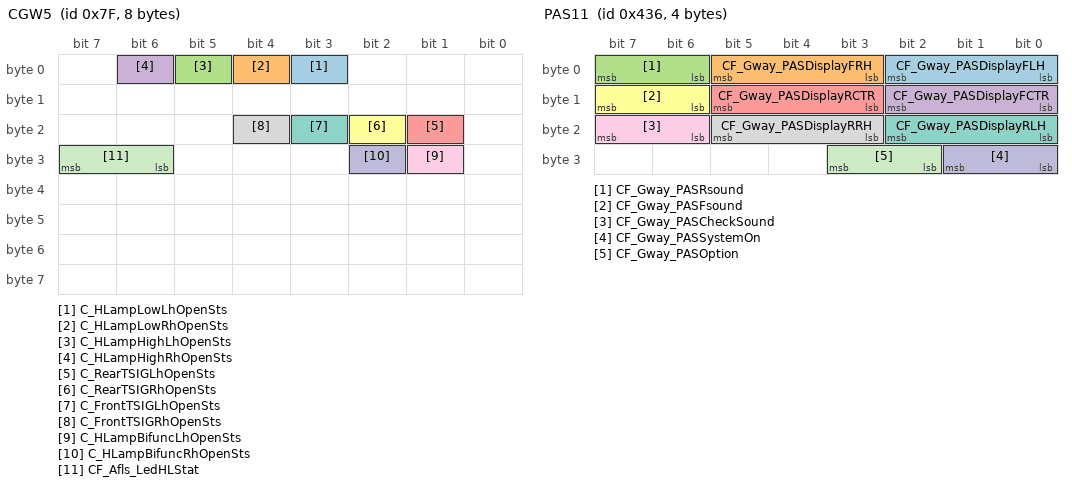
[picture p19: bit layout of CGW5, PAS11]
BO_ 127 CGW5: 8 CGW
 SG_ C_HLampLowLhOpenSts : 3|1@1+ (1,0) [0|1] ""  CLU
 SG_ C_HLampLowRhOpenSts : 4|1@1+ (1,0) [0|1] ""  CLU
 SG_ C_HLampHighLhOpenSts : 5|1@1+ (1,0) [0|1] ""  CLU
 SG_ C_HLampHighRhOpenSts : 6|1@1+ (1,0) [0|1] ""  CLU
 SG_ C_RearTSIGLhOpenSts : 17|1@1+ (1,0) [0|1] ""  CLU
 SG_ C_RearTSIGRhOpenSts : 18|1@1+ (1,0) [0|1] ""  CLU
 SG_ C_FrontTSIGLhOpenSts : 19|1@1+ (1,0) [0|1] ""  CLU
 SG_ C_FrontTSIGRhOpenSts : 20|1@1+ (1,0) [0|1] ""  CLU
 SG_ C_HLampBifuncLhOpenSts : 25|1@1+ (1,0) [0|1] ""  CLU
 SG_ C_HLampBifuncRhOpenSts : 26|1@1+ (1,0) [0|1] ""  CLU
 SG_ CF_Afls_LedHLStat : 30|2@1+ (1,0) [0|3] ""  CLU

BO_ 1078 PAS11: 4 CGW
 SG_ CF_Gway_PASDisplayFLH : 0|3@1+ (1,0) [0|7] ""  CLU
 SG_ CF_Gway_PASDisplayFRH : 3|3@1+ (1,0) [0|7] ""  CLU
 SG_ CF_Gway_PASRsound : 6|2@1+ (1,0) [0|3] ""  CLU
 SG_ CF_Gway_PASDisplayFCTR : 8|3@1+ (1,0) [0|7] ""  CLU
 SG_ CF_Gway_PASDisplayRCTR : 11|3@1+ (1,0) [0|7] ""  CLU
 SG_ CF_Gway_PASFsound : 14|2@1+ (1,0) [0|3] ""  CLU
 SG_ CF_Gway_PASDisplayRLH : 16|3@1+ (1,0) [0|7] ""  CLU
 SG_ CF_Gway_PASDisplayRRH : 19|3@1+ (1,0) [0|7] ""  CLU
 SG_ CF_Gway_PASCheckSound : 22|2@1+ (1,0) [0|3] ""  CLU
 SG_ CF_Gway_PASSystemOn : 24|2@1+ (1,0) [0|3] ""  CLU
 SG_ CF_Gway_PASOption : 26|2@1+ (1,0) [0|3] ""  CLU

CM_ BO_ 1280 "[P] Periodic";
CM_ BO_ 304 "[P] Periodic";
CM_ BO_ 320 "[P] Periodic";
CM_ BO_ 1173 "[P] Periodic";
CM_ BO_ 1425 "[P] Periodic";
CM_ BO_ 1345 "[PE] Periodic and On Event";
CM_ SG_ 1345 CF_Gway_LightSwState "This signal is for “IPM (Gateway)” applied vehicles only.";
CM_ SG_ 1345 CF_Gway_TSigRHSw "This signal is for “IPM (Gateway)” applied vehicles only.";
CM_ SG_ 1345 CF_Gway_TSigLHSw "This signal is for “IPM (Gateway)” applied vehicles only.";
CM_ SG_ 1345 CF_Gway_DriveTypeOption "This signal is for “IPM (Gateway)” applied vehicles only.";
CM_ SG_ 1345 CF_Gway_PassiveAccessLock "This signal is for “IPM (Gateway)” applied vehicles only.";
CM_ SG_ 1345 CF_Gway_PassiveAccessUnlock "This signal is for “IPM (Gateway)” applied vehicles only.";
CM_ BO_ 1363 "[PE] Periodic and On Event";
CM_ SG_ 1363 CF_Gway_ExtTailAct "This signal is for “IPM (Gateway)” applied vehicles only.";
CM_ SG_ 1363 CF_Gway_DrvSeatBeltInd "This signal is for “IPM (Gateway)” applied vehicles only.";
CM_ SG_ 1363 CF_Gway_AvTail "This signal is for “IPM (Gateway)” applied vehicles only.";
CM_ SG_ 1363 CF_Gway_RearFogAct "This signal is for “IPM (Gateway)” applied vehicles only.";
CM_ SG_ 1363 CF_Gway_RRDrSw "This signal is for “IPM (Gateway)” applied vehicles only.";
CM_ SG_ 1363 CF_Gway_RLDrSw "This signal is for “IPM (Gateway)” applied vehicles only.";
CM_ SG_ 1363 CF_Gway_IntTailAct "This signal is for “IPM (Gateway)” applied vehicles only.";
CM_ SG_ 1363 CF_Gway_ESCLFailWarn "This signal is for “IPM (Gateway)” applied vehicles only.";
CM_ SG_ 1363 CF_Gway_ESCLNotLockedWarn "This signal is for “IPM (Gateway)” applied vehicles only.";
CM_ SG_ 1363 CF_Gway_ESCLNotUnlockWarn "This signal is for “IPM (Gateway)” applied vehicles only.";
CM_ SG_ 1363 CF_Gway_IDoutWarn "This signal is for “IPM (Gateway)” applied vehicles only.";
CM_ SG_ 1363 CF_Gway_ImmoLp "This signal is for “IPM (Gateway)” applied vehicles only.";
CM_ SG_ 1363 CF_Gway_VehicleNotPWarn "This signal is for “IPM (Gateway)” applied vehicles only.";
CM_ SG_ 1363 CF_Gway_DeactivationWarn "This signal is for “IPM (Gateway)” applied vehicles only.";
CM_ SG_ 1363 CF_Gway_KeyBATDischargeWarn "This signal is for “IPM (Gateway)” applied vehicles only.";
CM_ SG_ 1363 CF_Gway_SSBWarn "This signal is for “IPM (Gateway)” applied vehicles only.";
CM_ SG_ 1363 CF_Gway_SMKRKECmd "This signal is for “IPM (Gateway)” applied vehicles only.";
CM_ SG_ 1363 CF_Gway_WngBuz "This signal is for “IPM (Gateway)” applied vehicles only.";
CM_ BO_ 1369 "[PE] Periodic and On Event";
CM_ BO_ 127 "[PE] Periodic and On Event";
CM_ SG_ 127 CF_Afls_LedHLStat "This signal is for CLU warning of LED H/LAMP with the exception of AFLS unit.";
CM_ BO_ 1294 "[PE] Periodic and On Event";
CM_ BO_ 1040 "[PE] Periodic and On Event";
CM_ SG_ 1040 CF_Gway_PasSpkrLvRValue "This signal is for “IPM (Gateway)” applied vehicles only.";
CM_ BO_ 1429 "[P] Periodic";
CM_ SG_ 1429 CF_Bms_LowtempStatus "This signal is same as another one in BMS1 message on P-CAN. It means this signal is indirectly routed from P-CAN to C-CAN through Gateway unit.";
CM_ SG_ 1429 CF_Bms_HighTempStatus "This signal is same as another one in BMS1 message on P-CAN. It means this signal is indirectly routed from P-CAN to C-CAN through Gateway unit.";
CM_ SG_ 1429 CF_Bms_StdCha "This signal is same as another one in BMS2 message on P-CAN. It means this signal is indirectly routed from P-CAN to C-CAN through Gateway unit.";
CM_ SG_ 1429 CF_Bms_FstCha "This signal is same as another one in BMS2 message on P-CAN. It means this signal is indirectly routed from P-CAN to C-CAN through Gateway unit.";
CM_ SG_ 1429 CR_Bms_BatI_A "This signal is same as another one in BMS2 message on P-CAN. It means this signal is indirectly routed from P-CAN to C-CAN through Gateway unit.";
CM_ SG_ 1429 CR_Bms_BatTotV_V "This signal is same as another one in BMS2 message on P-CAN. It means this signal is indirectly routed from P-CAN to C-CAN through Gateway unit.";
CM_ SG_ 1429 CR_Bms_ChgRemainedTime_min "This signal is same as another one in BMS3 message on P-CAN. It means this signal is indirectly routed from P-CAN to C-CAN through Gateway unit.";
CM_ BO_ 1535 "[P] Periodic";
CM_ BO_ 1430 "[P] Periodic";
CM_ SG_ 1430 CF_Bms_ServiceLamp "This signal is same as another one in BMS1 message on P-CAN. It means this signal is indirectly routed from P-CAN to C-CAN through Gateway unit.";
CM_ SG_ 1430 CF_Ldc_AuxBatWrnLamp "This signal is same as another one in LDC1 message on P-CAN. It means this signal is indirectly routed from P-CAN to C-CAN through Gateway unit.";
CM_ SG_ 1430 CF_Ldc_AuxBatWrnAlarm "This signal is same as another one in LDC1 message on P-CAN. It means this signal is indirectly routed from P-CAN to C-CAN through Gateway unit.";
CM_ SG_ 1430 CF_Ldc_Srvlamp_Rqst "This signal is same as another one in LDC1 message on P-CAN. It means this signal is indirectly routed from P-CAN to C-CAN through Gateway unit.";
CM_ SG_ 1430 CR_Ldc_ActVol_LS_V "This signal is same as another one in LDC2 message on P-CAN. It means this signal is indirectly routed from P-CAN to C-CAN through Gateway unit.";
CM_ BO_ 881 "[P] Periodic";
CM_ SG_ 881 CR_Brk_StkDep_Pc "This signal is same as another one in EBS1 message on P-CAN. It means this signal is indirectly routed from P-CAN to C-CAN through Gateway unit.";
CM_ SG_ 881 CF_Brk_RBSWLamp "This signal is same as another one in EBS1 message on P-CAN. It means this signal is indirectly routed from P-CAN to C-CAN through Gateway unit.";
CM_ SG_ 881 CF_Vcu_Rdy "This signal is same as another one in VCU1 message on P-CAN. It means this signal is indirectly routed from P-CAN to C-CAN through Gateway unit.";
CM_ SG_ 881 CF_Vcu_EvRdyClu "This signal is same as another one in VCU1 message on P-CAN. It means this signal is indirectly routed from P-CAN to C-CAN through Gateway unit.";
CM_ SG_ 881 CF_Vcu_EvRdy "This signal is same as another one in VCU1 message on P-CAN. It means this signal is indirectly routed from P-CAN to C-CAN through Gateway unit.";
CM_ SG_ 881 CF_Vcu_EcoMdOff "This signal is same as another one in VCU1 message on P-CAN. It means this signal is indirectly routed from P-CAN to C-CAN through Gateway unit.";
CM_ SG_ 881 CF_Vcu_SldAct "This signal is same as another one in VCU3 message on P-CAN. It means this signal is indirectly routed from P-CAN to C-CAN through Gateway unit.";
CM_ SG_ 881 CR_Vcu_SldVs "This signal is same as another one in VCU3 message on P-CAN. It means this signal is indirectly routed from P-CAN to C-CAN through Gateway unit.";
CM_ SG_ 881 CR_Vcu_AccPedDep_Pc "This signal is same as another one in VCU1 message on P-CAN. It means this signal is indirectly routed from P-CAN to C-CAN through Gateway unit.";
CM_ SG_ 881 CR_Vcu_MotTqCmd_Pc "This signal is same as another one in VCU3 message on P-CAN. It means this signal is indirectly routed from P-CAN to C-CAN through Gateway unit.";
CM_ SG_ 881 CR_Vcu_DistEmpty_km "This signal is same as another one in VCU1 message on P-CAN. It means this signal is indirectly routed from P-CAN to C-CAN through Gateway unit.";
CM_ BO_ 882 "[P] Periodic";
CM_ SG_ 882 CR_Mcu_VehSpd_Kph "This signal is same as another one in MCU3 message on P-CAN. It means this signal is indirectly routed from P-CAN to C-CAN through Gateway unit.";
CM_ SG_ 882 CR_Mcu_VehSpdDec_Kph "This signal is same as another one in MCU3 message on P-CAN. It means this signal is indirectly routed from P-CAN to C-CAN through Gateway unit.";
CM_ SG_ 882 CF_Vcu_GarSelDisp "This signal is same as another one in VCU1 message on P-CAN. It means this signal is indirectly routed from P-CAN to C-CAN through Gateway unit.";
CM_ SG_ 882 CF_Mcu_Mg1SvcLmp "This signal is same as another one in MCU2 message on P-CAN. It means this signal is indirectly routed from P-CAN to C-CAN through Gateway unit.";
CM_ SG_ 882 CF_Mcu_EwpCoolantCluDisp "This signal is same as another one in MCU2 message on P-CAN. It means this signal is indirectly routed from P-CAN to C-CAN through Gateway unit.";
CM_ SG_ 882 CR_Mcu_MotEstTq_Pc "This signal is same as another one in MCU1 message on P-CAN. It means this signal is indirectly routed from P-CAN to C-CAN through Gateway unit.";
CM_ BO_ 1355 "[P] Periodic";
CM_ SG_ 1355 CF_Bms_ChgSts "This signal is same as another one in BMS1 message on P-CAN. It means this signal is indirectly routed from P-CAN to C-CAN through Gateway unit.";
CM_ BO_ 1291 "[P] Periodic";
CM_ SG_ 1291 CR_Bms_DisplaySoc "This signal is same as another one in BMS8 message on P-CAN. It means this signal is indirectly routed from P-CAN to C-CAN through Gateway unit.";
CM_ SG_ 1291 CF_Vcu_ResvAirCtrInfo "This signal is same as another one in VCU10 message on P-CAN. It means this signal is indirectly routed from P-CAN to C-CAN through Gateway unit.";
CM_ SG_ 1291 CF_Datc_ServiceLamp "This signal is same as another one in DATC3 message on P-CAN. It means this signal is indirectly routed from P-CAN to C-CAN through Gateway unit.";
CM_ SG_ 1291 CF_Bms_PShiftForCharging "This signal is same as another one in BMS9 message on P-CAN. It means this signal is indirectly routed from P-CAN to C-CAN through Gateway unit.";
CM_ SG_ 1291 CF_OBC_AC_CONNECT_FLAG "This signal is same as another one in OBC1 message on P-CAN. It means this signal is indirectly routed from P-CAN to C-CAN through Gateway unit.";
CM_ SG_ 1291 CR_Datc_OutTemp_C "This signal is for “Gateway” applied vehicles only.";
CM_ SG_ 1291 CR_Datc_OutTempF "This signal is for “Gateway” applied vehicles only.";
CM_ SG_ 1291 DATC_TempUnit "This signal is for “Gateway” applied vehicles only.";
CM_ BO_ 2015 "[E] On Event";
CM_ SG_ 2015 FRM_FORMAT "If the value of this signal is not 2H, this signal can be ignored.*)
*) If an ECU has diagnostic communication on CAN service functionallty and communicate with an tester via CAN then must consider other message format. (DO NOT IGNORE OTHER CASES!)";
CM_ BO_ 1470 "[PE] Periodic and On Event";
CM_ BO_ 1407 "[PE] Periodic and On Event";
CM_ BO_ 1348 "[PE] Periodic and On Event";
CM_ BO_ 545 "[E] On Event";
CM_ SG_ 545 META_MessageType "This is Meta Data Message Type for Map Based ADAS.";
CM_ SG_ 545 META_MapProvider "This is Meta Data Map Provider for Map Based ADAS.";
CM_ SG_ 545 META_CountryCode "This is Meta Data Country Code for Map Based ADAS.";
CM_ SG_ 545 META_CyclicCounter "This is Meta Data Cyclic Counter for Map Based ADAS.";
CM_ SG_ 545 META_MajorProtocolVersion "This is Meta Data Major Protocol Version for Map Based ADAS.";
CM_ SG_ 545 META_HardwareVersion "This is Meta Data Hardware Version for Map Based ADAS.";
CM_ SG_ 545 META_DrivingSide "This is Meta Data Driving Side for Map Based ADAS.";
CM_ SG_ 545 META_RegionCode "This is Meta Data Region Code for Map Based ADAS.";
CM_ SG_ 545 META_MapVersionQuarter "This is Meta Data Map Version(Quarter) for Map Based ADAS.";
CM_ SG_ 545 META_MapVersionYear "This is Meta Data Map Version(Year) for Map Based ADAS.";
CM_ SG_ 545 META_SpeedUnit "This is Meta Dat Speed Unit for Map Based ADAS.";
CM_ SG_ 545 META_MinorProtocolVersion "This is Meta Data Minor Protocol Version for Map Based ADAS.";
CM_ BO_ 546 "[E] On Event";
CM_ SG_ 546 POS_MessageType "This is Position Message Type for Map Based ADAS.";
CM_ SG_ 546 POS_Offset "This is Position Offset for Map Based ADAS.";
CM_ SG_ 546 POS_CyclicCounter "This is Cyclic Counter for Map Based ADAS.";
CM_ SG_ 546 POS_PathIndex "This is Position Path Index for Map Based ADAS.";
CM_ SG_ 546 POS_PositionIndex "This is Position Index for Map Based ADAS.";
CM_ SG_ 546 POS_PositionProbability "This is Position Probility for Map Based ADAS.";
CM_ SG_ 546 POS_PositionAge "This is Position transmission age for Map Based ADAS.";
CM_ SG_ 546 POS_PositionConfidence "This is Position Confidence for Map Based ADAS.";
CM_ SG_ 546 POS_CurrentLane "This is Current Lane for Map Based ADAS.";
CM_ SG_ 546 POS_RangeAvgSpeed "This is range camera average speed for Map Based ADAS.";
CM_ SG_ 546 POS_RelativeHeading "This is relative heading for Map Based ADAS.";
CM_ BO_ 547 "[E] On Event";
CM_ SG_ 547 PROLONG_Value "This is Profile Long Value for Map Based ADAS.";
CM_ SG_ 547 PROLONG_MessageType "This is Profile Long MessageType for Map Based ADAS.";
CM_ SG_ 547 PROLONG_Offset "This is Profile Long Offset for Map Based ADAS.";
CM_ SG_ 547 PROLONG_CyclicCounter "This is Profile Long Cyclic Counter for Map Based ADAS.";
CM_ SG_ 547 PROLONG_PathIndex "This is Profile Long Path Index for Map Based ADAS.";
CM_ SG_ 547 PROLONG_ProfileType "This is Profile Long Type for Map Based ADAS.";
CM_ SG_ 547 PROLONG_CountrolPoint "This is Profile Long Control Point for Map Based ADAS.";
CM_ SG_ 547 PROLONG_Retransmission "This is Profile Long Retransmission Flag for Map Based ADAS.";
CM_ SG_ 547 PROLONG_Update "This is Profile Long Update flag for Map Based ADAS.";
CM_ BO_ 548 "[E] On Event";
CM_ SG_ 548 PROSHORT_MessageType "This is Profile Short Message Type for Map Based ADAS.";
CM_ SG_ 548 PROSHORT_Offset "This is Profile Short Offset for Map Based ADAS.";
CM_ SG_ 548 PROSHORT_CyclicCounter "This is Profile Short Cyclic Counter for Map Based ADAS.";
CM_ SG_ 548 PROSHORT_PathIndex "This is Profile Short Path Index for Map Based ADAS.";
CM_ SG_ 548 PROSHORT_Accuracy "This is Profile Short Accuracy for Map Based ADAS.";
CM_ SG_ 548 PROSHORT_Distance "This is Profile Short Distance for Map Based ADAS.";
CM_ SG_ 548 PROSHORT_Value0 "This is Profile Short Value at Offset for Map Based ADAS.";
CM_ SG_ 548 PROSHORT_Value1 "This is Profile Short Value at Offset+Distance1 for Map Based ADAS.";
CM_ SG_ 548 PROSHORT_ProfileType "This is Profile Short Type for Map Based ADAS.";
CM_ SG_ 548 PROSHORT_ControlPoint "This is Profile Short Control Point Flag for Map Based ADAS.";
CM_ SG_ 548 PROSHORT_Retransmission "This is Profile Short Retransmission Flag for Map Based ADAS.";
CM_ SG_ 548 PROSHORT_Update "This is Profile Short Update Flag for Map Based ADAS.";
CM_ BO_ 549 "[E] On Event";
CM_ SG_ 549 SEG_MessageType "This is Segment Message Type for Map Based ADAS.";
CM_ SG_ 549 SEG_Offset "This is Segment Offset for Map Based ADAS.";
CM_ SG_ 549 SEG_CyclicCounter "This is Segment Cyclic Counter for Map Based ADAS.";
CM_ SG_ 549 SEG_PathIndex "This is Segment Path Index for Map Based ADAS.";
CM_ SG_ 549 SEG_Tunnel "This is Segment Tunnel Information for Map Based ADAS.";
CM_ SG_ 549 SEG_Bridge "This is Segment Message for Map Based ADAS.";
CM_ SG_ 549 SEG_BuiltUpArea "This is Segment Built up Area Information for Map Based ADAS.";
CM_ SG_ 549 SEG_Retransmission "This is Segment Retransmission Flag for Map Based ADAS.";
CM_ SG_ 549 SEG_Update "This is Segment Update Flag for Map Based ADAS.";
CM_ SG_ 549 SEG_RelativeProbability "This is Segment Relative Probability for Map Based ADAS.";
CM_ SG_ 549 SEG_FunctionalRoadClass "This is Segment Road Class for Map Based ADAS.";
CM_ SG_ 549 SEG_CalculatedRoute "This is Segment Calculated Route state for Map Based ADAS.";
CM_ SG_ 549 SEG_ComplexIntersection "This is Segment Complex Intersection Information for Map Based ADAS.";
CM_ SG_ 549 SEG_FormOfWay "This is Segment Link Class for Map Based ADAS.";
CM_ SG_ 549 SEG_SpeedLimit "This is Segment Effective Speed Limit for Map Based ADAS.";
CM_ SG_ 549 SEG_SpeedLimitType "This is Segment Effective Speed Limit Type for Map Based ADAS.";
CM_ SG_ 549 SEG_DividedRoad "This is Segment Divided Road Information For Map Based ADAS.";
CM_ SG_ 549 SEG_OppositeLanes "This is Number of Segment Opposite Lanes for Map Based ADAS.";
CM_ SG_ 549 SEG_DirectionLanes "This is Number of Segment Direction Lanes for Map Based ADAS.";
CM_ BO_ 550 "[E] On Event";
CM_ SG_ 550 STUB_MessageType "This is Stub Message for Map Based ADAS.";
CM_ SG_ 550 STUB_Offset "This is Stub Offset for Map Based ADAS.";
CM_ SG_ 550 STUB_CyclicCounter "This is Stub Cyclic Counter for Map Based ADAS.";
CM_ SG_ 550 STUB_PathIndex "This is Stub Message for Map Based ADAS.";
CM_ SG_ 550 STUB_SubPathIndex "This is Stub Sub Path Index for Map Based ADAS.";
CM_ SG_ 550 STUB_Retransmission "This is Stub Retransmission Flag for Map Based ADAS.";
CM_ SG_ 550 STUB_Update "This is Stub Update Flag for Map Based ADAS.";
CM_ SG_ 550 STUB_RelativeProbability "This is Stub Message for Map Based ADAS.";
CM_ SG_ 550 STUB_FunctionalRoadClass "This is Stub Functional Road Class for Map Based ADAS.";
CM_ SG_ 550 STUB_CalculatedRoute "This is Stub Calculated Route state for Map Based ADAS.";
CM_ SG_ 550 STUB_ComplexIntersection "This is Stub Complex Intersection Information for Map Based ADAS.";
CM_ SG_ 550 STUB_FormOfWay "This is Stub Form of Way for Map Based ADAS.";
CM_ SG_ 550 STUB_TurnAngle "This is Stub Turn Angle for Map Based ADAS.";
CM_ SG_ 550 STUB_LastStubAtOffset "This is Last Stub at Offset for Map Based ADAS.";
CM_ SG_ 550 STUB_RightOfWay "This is Stub Right of Way Information for Map Based ADAS.";
CM_ SG_ 550 STUB_OppositeLanes "This is number of Stub Opposite Lanes for Map Based ADAS.";
CM_ SG_ 550 STUB_DirectionLanes "This is number of Stub Direction Lanes for Map Based ADAS.";
CM_ BO_ 1078 "[PE] Periodic and On Event";
CM_ BO_ 1136 "[P] Periodic";
CM_ BO_ 1426 "[P] Periodic";
CM_ BO_ 1507 "[PE] Periodic and On Event";
CM_ BO_ 1265 "[P] Periodic";
CM_ SG_ 1265 CF_Clu_RheostatLevel "This signal is for “IPM (Gateway)” applied vehicles only.
This signal has Validity with Battery (Not IGN1)";
CM_ SG_ 1265 CF_Clu_AliveCnt1 "In case of Delphi ECU, Output period tolerance(+1ms) will be applied to Engine Lamda3.";
CM_ BO_ 1456 "[P] Periodic";
CM_ BO_ 1292 "[P] Periodic";
CM_ SG_ 1292 CF_Clu_ActiveEcoSW "This signal is for the Active ECO equipped vehicle only.";
CM_ SG_ 1292 CF_Clu_EcoDriveInf "This signal is for “IPM (Gateway)” applied vehicles only.";
CM_ SG_ 1292 CF_Clu_AltLStatus "This signal is for “IPM (Gateway)” applied vehicles only.";
CM_ SG_ 1292 CF_Clu_AliveCnt2 "This signal is for “IPM (Gateway)” applied vehicles only.";
CM_ BO_ 1301 "[E] On Event";
CM_ SG_ 1301 CF_Clu_TrfChgSet "When this signal change, the message (CLU4) is sent 3 times.";
CM_ SG_ 1301 CF_Clu_LkasModeNValueSet "Request to set LKAS control mode";
CM_ BO_ 1322 "[PE] Periodic and On Event";
CM_ SG_ 1322 CF_Clu_ClusterSound "Sound type of Cluster";
CM_ BO_ 1307 "[E] On Event";
CM_ SG_ 1307 CF_Clu_TirePressUnitNValueSet "Request to set Tire Pressure Unit";
CM_ SG_ 1307 CF_Clu_SlifNValueSet "Request to set SLIF status";
CM_ SG_ 1307 CF_Clu_DAWModeNValueSet "This signal is used for DAW USM setting";
CM_ SG_ 1307 CF_Clu_AebModeNValueSet "-";
CM_ BO_ 1168 "[P] Periodic";
CM_ BO_ 1419 "[P] Periodic";
CM_ BO_ 832 "[P] Periodic";
CM_ SG_ 832 CF_Lkas_LdwsOpt_USM "This message is for LDWS^LKAS system";
CM_ BO_ 1342 "[P] Periodic";
CM_ SG_ 1342 CF_Lkas_AAOpt_USM "This signal is for CLU USM setting";
CM_ SG_ 1342 CF_Lkas_AAStatus "This signal is for A^Assist CLU HMI output";
CM_ SG_ 1342 CF_Lkas_AAWarn "This signal is for A^Assist CLU HMI output";
CM_ BO_ 897 "[P] Periodic";
CM_ SG_ 897 CF_Mdps_Flex "To broadcast MDPS steering support mode";
CM_ SG_ 897 CF_Mdps_AliveCnt "This message is for the “SPAS(Smart Parking Assist System)” applied vehicles only";
CM_ SG_ 897 CF_Mdps_Chksum "This message is for the “SPAS(Smart Parking Assist System)” applied vehicles only";
CM_ SG_ 897 CF_Mdps_CurrMode "To broadcast MDPS steering support mode";
CM_ BO_ 593 "[P] Periodic";
CM_ SG_ 593 CR_Mdps_StrTq "PH > 0 : Left Direction (CCW)
PH < 0 : Right Direction (CW)";
CM_ BO_ 688 "[P] Periodic";
CM_ SG_ 688 CheckSum "When MDPS ECU sends this message, this message value is valid 1.5 sec later from IG-ON.";
CM_ BO_ 1056 "[P] Periodic";
CM_ SG_ 1056 VSetDis "This signal can be sent in km^h or MPH according to the “SPEED_UNIT” signal (See CLU1 message).";
CM_ BO_ 1057 "[P] Periodic";
CM_ BO_ 1290 "[PE] Periodic and On Event";
CM_ BO_ 1427 "[P] Periodic";
CM_ BO_ 352 "[P] Periodic";
CM_ BO_ 1984 "[E] On Event";
CM_ BO_ 1151 "[P] Periodic";
CM_ SG_ 1151 AVH_STAT "This message is for “EPB (Electric Parking Brake)” system applied vehicle only.";
CM_ SG_ 1151 LDM_STAT "This message is for “EPB (Electric Parking Brake)” system applied vehicle only.";
CM_ SG_ 1151 REQ_EPB_ACT "This message is for “EPB (Electric Parking Brake)” system applied vehicle only.";
CM_ SG_ 1151 REQ_EPB_STAT "This message is for “EPB (Electric Parking Brake)” system applied vehicle only.";
CM_ SG_ 1151 ECD_ACT "This message is for “EPB (Electric Parking Brake)” system applied vehicle only.";
CM_ SG_ 1151 _4WD_LIM_REQ "This signal is for MANDO TCS^ESC system only.";
CM_ SG_ 1151 ROL_CNT_ESP "This message is for “EPB (Electric Parking Brake)” system applied vehicle only.";
CM_ BO_ 544 "[P] Periodic";
CM_ BO_ 339 "[P] Periodic";
CM_ BO_ 916 "[P] Periodic";
CM_ BO_ 1287 "[P] Periodic";
CM_ SG_ 1287 AVH_CLU "This message is for “EPB (Electric Parking Brake)” system applied vehicle only.";
CM_ SG_ 1287 AVH_I_LAMP "This message is for “EPB (Electric Parking Brake)” system applied vehicle only.";
CM_ SG_ 1287 AVH_ALARM "This message is for “EPB (Electric Parking Brake)” system applied vehicle only.";
CM_ SG_ 1287 AVH_LAMP "This message is for “EPB (Electric Parking Brake)” system applied vehicle only.";
CM_ BO_ 356 "[P] Periodic";
CM_ SG_ 356 CR_Esc_StrTqReq "(PH) > 0 : Left Direction (CCW)
(PH) < 0 : Right Direction (CW)";
CM_ BO_ 903 "[P] Periodic";
CM_ SG_ 903 WHL_PUL_FL "After IGN status is changed from ON to OFF, It is necessary to maintain transmitting this message for 3 minutes.";
CM_ SG_ 903 WHL_PUL_FR "After IGN status is changed from ON to OFF, It is necessary to maintain transmitting this message for 3 minutes.";
CM_ SG_ 903 WHL_PUL_RL "After IGN status is changed from ON to OFF, It is necessary to maintain transmitting this message for 3 minutes.";
CM_ SG_ 903 WHL_PUL_RR "After IGN status is changed from ON to OFF, It is necessary to maintain transmitting this message for 3 minutes.";
CM_ SG_ 903 WHL_DIR_FL "After IGN status is changed from ON to OFF, It is necessary to maintain transmitting this message for 3 minutes.";
CM_ SG_ 903 WHL_DIR_FR "After IGN status is changed from ON to OFF, It is necessary to maintain transmitting this message for 3 minutes.";
CM_ SG_ 903 WHL_DIR_RL "After IGN status is changed from ON to OFF, It is necessary to maintain transmitting this message for 3 minutes.";
CM_ SG_ 903 WHL_DIR_RR "After IGN status is changed from ON to OFF, It is necessary to maintain transmitting this message for 3 minutes.";
CM_ SG_ 903 WHL_PUL_Chksum "After IGN status is changed from ON to OFF, It is necessary to maintain transmitting this message for 3 minutes.";
CM_ BO_ 902 "[P] Periodic";
CM_ SG_ 902 WHL_SPD_FL "After IGN status is changed from ON to OFF, It is necessary to maintain transmitting this message for 3 minutes.";
CM_ SG_ 902 WHL_SPD_FR "After IGN status is changed from ON to OFF, It is necessary to maintain transmitting this message for 3 minutes.";
CM_ SG_ 902 WHL_SPD_RL "After IGN status is changed from ON to OFF, It is necessary to maintain transmitting this message for 3 minutes.";
CM_ SG_ 902 WHL_SPD_RR "After IGN status is changed from ON to OFF, It is necessary to maintain transmitting this message for 3 minutes.";
BA_DEF_ SG_ "GenSigEnvVarType" ENUM "Int","Float","Undef" ;
BA_DEF_ SG_ "GenSigEVName" STRING ;
BA_DEF_ SG_ "GenSigInactiveValue" INT 0 65535 ;
BA_DEF_ SG_ "GenSigSendType" ENUM "Cyclic","OnWrite","OnWriteWithRepetition","OnChange","OnChangeWithRepetition","IfActive","IfActiveWithRepetition","NoSigSendType" ;
BA_DEF_ SG_ "GenSigStartValue" INT 0 1215752192 ;
BA_DEF_ SG_ "GwSigLatencyTime" INT 0 65535 ;
BA_DEF_ SG_ "GwSigMissingSourceType" ENUM "Undef","OldValue","DefaultValue","InitialValue" ;
BA_DEF_ SG_ "SignalCategory" HEX 10 15 ;
BA_DEF_ BO_ "GenMsgCycleTime" INT 0 2000 ;
BA_DEF_ BO_ "GenMsgCycleTimeFast" INT 0 500 ;
BA_DEF_ BO_ "GenMsgDelayTime" INT 0 20 ;
BA_DEF_ BO_ "GenMsgILSupport" ENUM "No","Yes" ;
BA_DEF_ BO_ "GenMsgNrOfRepetition" INT 0 3 ;
BA_DEF_ BO_ "GenMsgSendType" ENUM "Cyclic","not_used","not_used","not_used","not_used","not_used","not_used","not_used","NoMsgSendType" ;
BA_DEF_ BO_ "GenMsgStartDelayTime" INT 0 2000 ;
BA_DEF_ BU_ "GenNodSleepTime" INT 1375 1650 ;
BA_DEF_ BU_ "ILUsed" ENUM "No","Yes" ;
BA_DEF_ BU_ "NmCAN" INT 1 2 ;
BA_DEF_ BU_ "NmStationAddress" HEX 0 255 ;
BA_DEF_ BU_ "NodeLayerModules" STRING ;
BA_DEF_ "Baudrate" INT 50000 1000000 ;
BA_DEF_ "BusType" STRING ;
BA_DEF_ "GenEnvVarEndingDsp" STRING ;
BA_DEF_ "GenEnvVarEndingSnd" STRING ;
BA_DEF_ "GenEnvVarPrefix" STRING ;
BA_DEF_ "GenNWMApBusSleep" STRING ;
BA_DEF_ "GenNWMApCanNormal" STRING ;
BA_DEF_ "GenNWMApCanOff" STRING ;
BA_DEF_ "GenNWMApCanOn" STRING ;
BA_DEF_ "GenNWMApCanSleep" STRING ;
BA_DEF_ "GenNWMApCanWakeUp" STRING ;
BA_DEF_ "GenNWMGotoMode_Awake" STRING ;
BA_DEF_ "GenNWMGotoMode_BusSleep" STRING ;
BA_DEF_ "GenNWMSleepTime" INT 1375 1650 ;
BA_DEF_ "GenNWMTalkNM" STRING ;
BA_DEF_ "Manufacturer" STRING ;
BA_DEF_ "NmBaseAddress" HEX 0 2047 ;
BA_DEF_ "NmMessageCount" INT 0 128 ;
BA_DEF_ "NmType" STRING ;
BA_DEF_ "SamplePointMax" INT 50 85 ;
BA_DEF_ "SamplePointMin" INT 55 85 ;
BA_DEF_ "SyncJumpWidthMax" INT 1 8 ;
BA_DEF_ "SyncJumpWidthMin" INT 1 4 ;
BA_DEF_ "VersionDay" INT 1 31 ;
BA_DEF_ "VersionMonth" INT 1 12 ;
BA_DEF_ "VersionWeek" INT 1 53 ;
BA_DEF_ "VersionYear" INT 0 9999 ;
BA_DEF_REL_ BU_SG_REL_ "GenSigTimeoutTime" INT 0 7000 ;
BA_DEF_DEF_ "GenSigEnvVarType" "Undef" ;
BA_DEF_DEF_ "GenSigEVName" "@Signame" ;
BA_DEF_DEF_ "GenSigInactiveValue" 0 ;
BA_DEF_DEF_ "GenSigSendType" "NoSigSendType" ;
BA_DEF_DEF_ "GenSigStartValue" 0 ;
BA_DEF_DEF_ "GwSigLatencyTime" 40 ;
BA_DEF_DEF_ "GwSigMissingSourceType" "Undef" ;
BA_DEF_DEF_ "SignalCategory" 12 ;
BA_DEF_DEF_ "GenMsgCycleTime" 10 ;
BA_DEF_DEF_ "GenMsgCycleTimeFast" 40 ;
BA_DEF_DEF_ "GenMsgDelayTime" 20 ;
BA_DEF_DEF_ "GenMsgILSupport" "Yes" ;
BA_DEF_DEF_ "GenMsgNrOfRepetition" 0 ;
BA_DEF_DEF_ "GenMsgSendType" "Cyclic" ;
BA_DEF_DEF_ "GenMsgStartDelayTime" 0 ;
BA_DEF_DEF_ "GenNodSleepTime" 1500 ;
BA_DEF_DEF_ "ILUsed" "Yes" ;
BA_DEF_DEF_ "NmCAN" 1 ;
BA_DEF_DEF_ "NmStationAddress" 0 ;
BA_DEF_DEF_ "NodeLayerModules" "oseknm01.dll" ;
BA_DEF_DEF_ "Baudrate" 500000 ;
BA_DEF_DEF_ "BusType" "CAN" ;
BA_DEF_DEF_ "GenEnvVarEndingDsp" "Dsp_" ;
BA_DEF_DEF_ "GenEnvVarEndingSnd" "_" ;
BA_DEF_DEF_ "GenEnvVarPrefix" "Env" ;
BA_DEF_DEF_ "GenNWMApBusSleep" "ApplNmCanBusSleep()" ;
BA_DEF_DEF_ "GenNWMApCanNormal" "ApplNmCanNormal()" ;
BA_DEF_DEF_ "GenNWMApCanOff" "ApplCanOffline()" ;
BA_DEF_DEF_ "GenNWMApCanOn" "ApplCanOnline()" ;
BA_DEF_DEF_ "GenNWMApCanSleep" "ApplNmCanSleep()" ;
BA_DEF_DEF_ "GenNWMApCanWakeUp" "ApplCanWakeUp()" ;
BA_DEF_DEF_ "GenNWMGotoMode_Awake" "GotoMode_Awake()" ;
BA_DEF_DEF_ "GenNWMGotoMode_BusSleep" "GotoMode_BusSleep()" ;
BA_DEF_DEF_ "GenNWMSleepTime" 1500 ;
BA_DEF_DEF_ "GenNWMTalkNM" "TalkNM()" ;
BA_DEF_DEF_ "Manufacturer" "HMC" ;
BA_DEF_DEF_ "NmBaseAddress" 1024 ;
BA_DEF_DEF_ "NmMessageCount" 128 ;
BA_DEF_DEF_ "NmType" "Vector" ;
BA_DEF_DEF_ "SamplePointMax" 82 ;
BA_DEF_DEF_ "SamplePointMin" 75 ;
BA_DEF_DEF_ "SyncJumpWidthMax" 3 ;
BA_DEF_DEF_ "SyncJumpWidthMin" 2 ;
BA_DEF_DEF_ "VersionDay" 1 ;
BA_DEF_DEF_ "VersionMonth" 1 ;
BA_DEF_DEF_ "VersionWeek" 1 ;
BA_DEF_DEF_ "VersionYear" 2010 ;
BA_DEF_DEF_REL_ "GenSigTimeoutTime" 500 ;
BA_ "GenMsgCycleTime" BO_ 1280 100;
BA_REL_ "GenSigTimeoutTime" BU_SG_REL_ CLU SG_ 1280 CF_SWL_Ind 1000;
BA_ "GenSigStartValue" SG_ 304 CR_Yrs_Yr 32768;
BA_ "GenSigStartValue" SG_ 304 CR_Yrs_LatAc 32768;
BA_ "GenSigStartValue" SG_ 304 CF_Yrs_YrStat 2;
BA_ "GenSigStartValue" SG_ 304 CF_Yrs_LatAcStat 2;
BA_ "GenSigStartValue" SG_ 320 CR_Yrs_LongAc 32768;
BA_ "GenSigStartValue" SG_ 320 CF_Yrs_LongAcStat 2;
BA_ "GenMsgCycleTime" BO_ 1173 100;
BA_ "GenMsgCycleTime" BO_ 1425 100;
BA_REL_ "GenSigTimeoutTime" BU_SG_REL_ CLU SG_ 1425 AFLS_STAT 1000;
BA_ "GenMsgCycleTime" BO_ 1345 100;
BA_ "GenMsgNrOfRepetition" BO_ 1345 3;
BA_ "GenSigSendType" SG_ 1345 CF_Gway_IGNSw 4;
BA_ "GenSigSendType" SG_ 1345 CF_Gway_RKECmd 4;
BA_ "GenSigSendType" SG_ 1345 CF_Gway_DrvDrSw 4;
BA_ "GenSigSendType" SG_ 1345 CF_Gway_DrvSeatBeltSw 4;
BA_ "GenSigSendType" SG_ 1345 CF_Gway_TrunkTgSw 4;
BA_ "GenSigSendType" SG_ 1345 CF_Gway_SMKOption 4;
BA_ "GenSigSendType" SG_ 1345 CF_Gway_HoodSw 4;
BA_ "GenSigSendType" SG_ 1345 CF_Gway_TurnSigLh 4;
BA_ "GenSigSendType" SG_ 1345 CF_Gway_WiperIntT 4;
BA_ "GenSigSendType" SG_ 1345 CF_Gway_RainSnsState 4;
BA_ "GenSigSendType" SG_ 1345 CF_Gway_HeadLampLow 4;
BA_ "GenSigSendType" SG_ 1345 CF_Gway_HeadLampHigh 4;
BA_ "GenSigSendType" SG_ 1345 CF_Gway_HazardSw 4;
BA_ "GenSigSendType" SG_ 1345 CF_Gway_AstDrSw 4;
BA_REL_ "GenSigTimeoutTime" BU_SG_REL_ AFLS SG_ 1345 CF_Gway_LightSwState 1000;
BA_REL_ "GenSigTimeoutTime" BU_SG_REL_ CLU SG_ 1345 CF_Gway_LightSwState 1000;
BA_ "GenSigSendType" SG_ 1345 CF_Gway_LightSwState 4;
BA_REL_ "GenSigTimeoutTime" BU_SG_REL_ LDWS_LKAS SG_ 1345 CF_Gway_TSigRHSw 1000;
BA_ "GenSigSendType" SG_ 1345 CF_Gway_TSigRHSw 4;
BA_REL_ "GenSigTimeoutTime" BU_SG_REL_ LDWS_LKAS SG_ 1345 CF_Gway_TSigLHSw 1000;
BA_ "GenSigSendType" SG_ 1345 CF_Gway_TSigLHSw 4;
BA_ "GenSigSendType" SG_ 1345 CF_Gway_DriveTypeOption 4;
BA_REL_ "GenSigTimeoutTime" BU_SG_REL_ CLU SG_ 1345 CF_Gway_PassiveAccessLock 1000;
BA_ "GenSigSendType" SG_ 1345 CF_Gway_PassiveAccessLock 4;
BA_REL_ "GenSigTimeoutTime" BU_SG_REL_ CLU SG_ 1345 CF_Gway_PassiveAccessUnlock 1000;
BA_ "GenSigSendType" SG_ 1345 CF_Gway_PassiveAccessUnlock 4;
BA_ "GenSigSendType" SG_ 1345 CF_Gway_PassingSW 4;
BA_ "GenSigSendType" SG_ 1345 CF_Gway_HBAControlMode 4;
BA_ "GenSigSendType" SG_ 1345 CF_Gway_RainSnsOption 4;
BA_REL_ "GenSigTimeoutTime" BU_SG_REL_ CLU SG_ 1345 C_SunRoofOpenState 1000;
BA_ "GenSigSendType" SG_ 1345 C_SunRoofOpenState 4;
BA_ "GenSigSendType" SG_ 1345 CF_Gway_TurnSigRh 4;
BA_ "GenMsgCycleTime" BO_ 1363 200;
BA_ "GenMsgNrOfRepetition" BO_ 1363 3;
BA_REL_ "GenSigTimeoutTime" BU_SG_REL_ CLU SG_ 1363 CF_Gway_ExtTailAct 1000;
BA_REL_ "GenSigTimeoutTime" BU_SG_REL_ LCA SG_ 1363 CF_Gway_ExtTailAct 1000;
BA_ "GenSigSendType" SG_ 1363 CF_Gway_ExtTailAct 4;
BA_ "GenSigSendType" SG_ 1363 CF_Gway_AutoLightValue 4;
BA_ "GenSigSendType" SG_ 1363 CF_Gway_BrakeFluidSw 4;
BA_REL_ "GenSigTimeoutTime" BU_SG_REL_ CLU SG_ 1363 CF_Gway_DrvSeatBeltInd 1000;
BA_ "GenSigSendType" SG_ 1363 CF_Gway_DrvSeatBeltInd 4;
BA_REL_ "GenSigTimeoutTime" BU_SG_REL_ CLU SG_ 1363 CF_Gway_AvTail 1000;
BA_ "GenSigSendType" SG_ 1363 CF_Gway_AvTail 4;
BA_REL_ "GenSigTimeoutTime" BU_SG_REL_ CLU SG_ 1363 CF_Gway_RearFogAct 1000;
BA_ "GenSigSendType" SG_ 1363 CF_Gway_RearFogAct 4;
BA_REL_ "GenSigTimeoutTime" BU_SG_REL_ CLU SG_ 1363 CF_Gway_RRDrSw 1000;
BA_ "GenSigSendType" SG_ 1363 CF_Gway_RRDrSw 4;
BA_REL_ "GenSigTimeoutTime" BU_SG_REL_ CLU SG_ 1363 CF_Gway_RLDrSw 1000;
BA_ "GenSigSendType" SG_ 1363 CF_Gway_RLDrSw 4;
BA_REL_ "GenSigTimeoutTime" BU_SG_REL_ CLU SG_ 1363 CF_Gway_IntTailAct 1000;
BA_ "GenSigSendType" SG_ 1363 CF_Gway_IntTailAct 4;
BA_REL_ "GenSigTimeoutTime" BU_SG_REL_ LDWS_LKAS SG_ 1363 CF_Gway_WiperParkPosition 1000;
BA_ "GenSigSendType" SG_ 1363 CF_Gway_WiperParkPosition 4;
BA_REL_ "GenSigTimeoutTime" BU_SG_REL_ CLU SG_ 1363 CF_Gway_ESCLFailWarn 1000;
BA_ "GenSigSendType" SG_ 1363 CF_Gway_ESCLFailWarn 4;
BA_REL_ "GenSigTimeoutTime" BU_SG_REL_ CLU SG_ 1363 CF_Gway_ESCLNotLockedWarn 1000;
BA_ "GenSigSendType" SG_ 1363 CF_Gway_ESCLNotLockedWarn 4;
BA_REL_ "GenSigTimeoutTime" BU_SG_REL_ CLU SG_ 1363 CF_Gway_ESCLNotUnlockWarn 1000;
BA_ "GenSigSendType" SG_ 1363 CF_Gway_ESCLNotUnlockWarn 4;
BA_REL_ "GenSigTimeoutTime" BU_SG_REL_ CLU SG_ 1363 CF_Gway_IDoutWarn 1000;
BA_ "GenSigSendType" SG_ 1363 CF_Gway_IDoutWarn 4;
BA_REL_ "GenSigTimeoutTime" BU_SG_REL_ CLU SG_ 1363 CF_Gway_ImmoLp 1000;
BA_ "GenSigSendType" SG_ 1363 CF_Gway_ImmoLp 4;
BA_REL_ "GenSigTimeoutTime" BU_SG_REL_ CLU SG_ 1363 CF_Gway_VehicleNotPWarn 1000;
BA_ "GenSigSendType" SG_ 1363 CF_Gway_VehicleNotPWarn 4;
BA_REL_ "GenSigTimeoutTime" BU_SG_REL_ CLU SG_ 1363 CF_Gway_DeactivationWarn 1000;
BA_ "GenSigSendType" SG_ 1363 CF_Gway_DeactivationWarn 4;
BA_REL_ "GenSigTimeoutTime" BU_SG_REL_ CLU SG_ 1363 CF_Gway_KeyBATDischargeWarn 1000;
BA_ "GenSigSendType" SG_ 1363 CF_Gway_KeyBATDischargeWarn 4;
BA_REL_ "GenSigTimeoutTime" BU_SG_REL_ CLU SG_ 1363 CF_Gway_SSBWarn 1000;
BA_ "GenSigSendType" SG_ 1363 CF_Gway_SSBWarn 4;
BA_REL_ "GenSigTimeoutTime" BU_SG_REL_ CLU SG_ 1363 CF_Gway_SMKRKECmd 1000;
BA_ "GenSigSendType" SG_ 1363 CF_Gway_SMKRKECmd 4;
BA_REL_ "GenSigTimeoutTime" BU_SG_REL_ CLU SG_ 1363 CF_Gway_SJBDeliveryMode 1000;
BA_ "GenSigSendType" SG_ 1363 CF_Gway_SJBDeliveryMode 4;
BA_ "GenSigStartValue" SG_ 1363 CF_Gway_SJBDeliveryMode 1;
BA_REL_ "GenSigTimeoutTime" BU_SG_REL_ CLU SG_ 1363 CF_Gway_SMKDispWarn 1000;
BA_ "GenSigSendType" SG_ 1363 CF_Gway_SMKDispWarn 4;
BA_ "GenSigSendType" SG_ 1363 CF_Gway_WngBuz 4;
BA_ "GenMsgCycleTime" BO_ 1369 200;
BA_ "GenMsgNrOfRepetition" BO_ 1369 3;
BA_ "GenSigSendType" SG_ 1369 CF_Gway_MemoryP1Cmd 4;
BA_ "GenSigSendType" SG_ 1369 CF_Gway_MemoryP2Cmd 4;
BA_ "GenSigSendType" SG_ 1369 CF_Gway_PBackP1Cmd 4;
BA_ "GenSigSendType" SG_ 1369 CF_Gway_PBackP2Cmd 4;
BA_ "GenSigSendType" SG_ 1369 CF_Gway_StrgWhlHeatedState 4;
BA_ "GenSigSendType" SG_ 1369 CF_Gway_PBACKStopCmd 4;
BA_ "GenSigSendType" SG_ 1369 CF_Gway_MemoryEnable 4;
BA_REL_ "GenSigTimeoutTime" BU_SG_REL_ CLU SG_ 1369 CF_Gway_StrgWhlAutoOffState 0;
BA_ "GenSigSendType" SG_ 1369 CF_Gway_StrgWhlAutoOffState 4;
BA_ "GenSigSendType" SG_ 1369 CF_Gway_IMSBuzzer 4;
BA_REL_ "GenSigTimeoutTime" BU_SG_REL_ CLU SG_ 1369 CF_Gway_WiperSwState 0;
BA_ "GenSigSendType" SG_ 1369 CF_Gway_WiperSwState 4;
BA_REL_ "GenSigTimeoutTime" BU_SG_REL_ CLU SG_ 1369 CF_Gway_DrvSeatBeltIND 0;
BA_ "GenSigSendType" SG_ 1369 CF_Gway_DrvSeatBeltIND 4;
BA_REL_ "GenSigTimeoutTime" BU_SG_REL_ CLU SG_ 1369 CF_Gway_WPCWarning 0;
BA_ "GenSigSendType" SG_ 1369 CF_Gway_WPCWarning 4;
BA_ "GenSigSendType" SG_ 1369 CF_Gway_DedicatedDRLState 4;
BA_REL_ "GenSigTimeoutTime" BU_SG_REL_ CLU SG_ 1369 CF_Gway_SeatBeltWngBuz 1000;
BA_ "GenSigSendType" SG_ 1369 CF_Gway_SeatBeltWngBuz 4;
BA_ "GenMsgCycleTime" BO_ 127 1000;
BA_ "GenMsgNrOfRepetition" BO_ 127 3;
BA_REL_ "GenSigTimeoutTime" BU_SG_REL_ CLU SG_ 127 C_HLampLowLhOpenSts 0;
BA_ "GenSigSendType" SG_ 127 C_HLampLowLhOpenSts 4;
BA_REL_ "GenSigTimeoutTime" BU_SG_REL_ CLU SG_ 127 C_HLampLowRhOpenSts 0;
BA_ "GenSigSendType" SG_ 127 C_HLampLowRhOpenSts 4;
BA_REL_ "GenSigTimeoutTime" BU_SG_REL_ CLU SG_ 127 C_HLampHighLhOpenSts 0;
BA_ "GenSigSendType" SG_ 127 C_HLampHighLhOpenSts 4;
BA_REL_ "GenSigTimeoutTime" BU_SG_REL_ CLU SG_ 127 C_HLampHighRhOpenSts 0;
BA_ "GenSigSendType" SG_ 127 C_HLampHighRhOpenSts 4;
BA_REL_ "GenSigTimeoutTime" BU_SG_REL_ CLU SG_ 127 C_RearTSIGLhOpenSts 0;
BA_ "GenSigSendType" SG_ 127 C_RearTSIGLhOpenSts 4;
BA_REL_ "GenSigTimeoutTime" BU_SG_REL_ CLU SG_ 127 C_RearTSIGRhOpenSts 0;
BA_ "GenSigSendType" SG_ 127 C_RearTSIGRhOpenSts 4;
BA_REL_ "GenSigTimeoutTime" BU_SG_REL_ CLU SG_ 127 C_FrontTSIGLhOpenSts 0;
BA_ "GenSigSendType" SG_ 127 C_FrontTSIGLhOpenSts 4;
BA_REL_ "GenSigTimeoutTime" BU_SG_REL_ CLU SG_ 127 C_FrontTSIGRhOpenSts 0;
BA_ "GenSigSendType" SG_ 127 C_FrontTSIGRhOpenSts 4;
BA_REL_ "GenSigTimeoutTime" BU_SG_REL_ CLU SG_ 127 C_HLampBifuncLhOpenSts 0;
BA_ "GenSigSendType" SG_ 127 C_HLampBifuncLhOpenSts 4;
BA_REL_ "GenSigTimeoutTime" BU_SG_REL_ CLU SG_ 127 C_HLampBifuncRhOpenSts 0;
BA_ "GenSigSendType" SG_ 127 C_HLampBifuncRhOpenSts 4;
BA_REL_ "GenSigTimeoutTime" BU_SG_REL_ CLU SG_ 127 CF_Afls_LedHLStat 1000;
BA_ "GenSigSendType" SG_ 127 CF_Afls_LedHLStat 4;
BA_ "GenMsgCycleTime" BO_ 1294 200;
BA_ "GenMsgNrOfRepetition" BO_ 1294 3;
BA_ "GenSigSendType" SG_ 1294 CF_Gway_BCMWarning 4;
BA_REL_ "GenSigTimeoutTime" BU_SG_REL_ CLU SG_ 1294 CF_Gway_USADRLSw 0;
BA_ "GenSigSendType" SG_ 1294 CF_Gway_USADRLSw 4;
BA_REL_ "GenSigTimeoutTime" BU_SG_REL_ CLU SG_ 1294 CF_Gway_ChaDrSwFrt 1500;
BA_ "GenSigSendType" SG_ 1294 CF_Gway_ChaDrSwFrt 4;
BA_ "SignalCategory" SG_ 1294 CF_Gway_ChaDrSwFrt 10;
BA_REL_ "GenSigTimeoutTime" BU_SG_REL_ CLU SG_ 1294 CF_Gway_ChaDrSwRr 1500;
BA_ "GenSigSendType" SG_ 1294 CF_Gway_ChaDrSwRr 4;
BA_ "SignalCategory" SG_ 1294 CF_Gway_ChaDrSwRr 10;
BA_ "GenMsgCycleTime" BO_ 1040 200;
BA_ "GenMsgNrOfRepetition" BO_ 1040 3;
BA_ "GenSigSendType" SG_ 1040 CF_Gway_EscortHLRValue 4;
BA_ "GenSigSendType" SG_ 1040 CF_Gway_TTUnlockRValue 4;
BA_ "GenSigSendType" SG_ 1040 CF_Gway_ADrLRValue 4;
BA_ "GenSigSendType" SG_ 1040 CF_Gway_ADrURValue 4;
BA_ "GenSigSendType" SG_ 1040 CF_Gway_WlightRValue 4;
BA_ "GenSigSendType" SG_ 1040 CF_Gway_PSMRValue 4;
BA_ "GenSigSendType" SG_ 1040 CF_Gway_OTTurnRValue 4;
BA_ "GenSigSendType" SG_ 1040 CF_Gway_HAnBRValue 4;
BA_ "GenSigSendType" SG_ 1040 CF_Gway_PasSpkrLvRValue 4;
BA_REL_ "GenSigTimeoutTime" BU_SG_REL_ CLU SG_ 1040 CF_Gway_WPCRValue 0;
BA_ "GenSigSendType" SG_ 1040 CF_Gway_WPCRValue 4;
BA_ "GenMsgCycleTime" BO_ 1429 100;
BA_REL_ "GenSigTimeoutTime" BU_SG_REL_ CLU SG_ 1429 CF_Bms_LowtempStatus 2000;
BA_REL_ "GenSigTimeoutTime" BU_SG_REL_ CLU SG_ 1429 CF_Bms_HighTempStatus 2000;
BA_REL_ "GenSigTimeoutTime" BU_SG_REL_ CLU SG_ 1429 CF_Bms_StdCha 2000;
BA_REL_ "GenSigTimeoutTime" BU_SG_REL_ CLU SG_ 1429 CF_Bms_FstCha 2000;
BA_REL_ "GenSigTimeoutTime" BU_SG_REL_ CLU SG_ 1429 CF_BMS_ChgFinishedForOBC 2000;
BA_REL_ "GenSigTimeoutTime" BU_SG_REL_ CLU SG_ 1429 CF_Vcu_DriveMode 2000;
BA_REL_ "GenSigTimeoutTime" BU_SG_REL_ CLU SG_ 1429 CR_Bms_BatI_A 2000;
BA_REL_ "GenSigTimeoutTime" BU_SG_REL_ CLU SG_ 1429 CR_Bms_BatTotV_V 2000;
BA_REL_ "GenSigTimeoutTime" BU_SG_REL_ CLU SG_ 1429 CR_Bms_ChgRemainedTime_min 2000;
BA_ "GenMsgCycleTime" BO_ 1535 100;
BA_ "GenMsgCycleTime" BO_ 1430 100;
BA_REL_ "GenSigTimeoutTime" BU_SG_REL_ CLU SG_ 1430 CF_Vcu_SpdLmt 2000;
BA_REL_ "GenSigTimeoutTime" BU_SG_REL_ CLU SG_ 1430 CF_Bms_ServiceLamp 2000;
BA_REL_ "GenSigTimeoutTime" BU_SG_REL_ CLU SG_ 1430 CF_Ldc_AuxBatWrnLamp 2000;
BA_REL_ "GenSigTimeoutTime" BU_SG_REL_ CLU SG_ 1430 CF_Ldc_AuxBatWrnAlarm 2000;
BA_REL_ "GenSigTimeoutTime" BU_SG_REL_ CLU SG_ 1430 CF_Ldc_Srvlamp_Rqst 2000;
BA_REL_ "GenSigTimeoutTime" BU_SG_REL_ CLU SG_ 1430 CF_Aaf_WrnLamp 1000;
BA_ "GenSigStartValue" SG_ 1430 CF_Aaf_WrnLamp 1;
BA_REL_ "GenSigTimeoutTime" BU_SG_REL_ CLU SG_ 1430 CR_Vcu_EcoPotential_Eco 2000;
BA_REL_ "GenSigTimeoutTime" BU_SG_REL_ CLU SG_ 1430 CR_Vcu_EcoPotential_Normal 2000;
BA_REL_ "GenSigTimeoutTime" BU_SG_REL_ CLU SG_ 1430 CR_Vcu_EcoPotential_Sport 2000;
BA_REL_ "GenSigTimeoutTime" BU_SG_REL_ EPB SG_ 1430 CR_Ldc_ActVol_LS_V 2000;
BA_REL_ "GenSigTimeoutTime" BU_SG_REL_ CLU SG_ 1430 CR_Vcu_MaxSpd 2000;
BA_ "GenSigStartValue" SG_ 882 CF_Vcu_GarSelDisp 9;
BA_ "GenMsgCycleTime" BO_ 1355 100;
BA_REL_ "GenSigTimeoutTime" BU_SG_REL_ CLU SG_ 1355 CF_Vcu_CIL_Status 2000;
BA_REL_ "GenSigTimeoutTime" BU_SG_REL_ CLU SG_ 1355 CF_Vcu_CIL_Warn 2000;
BA_REL_ "GenSigTimeoutTime" BU_SG_REL_ CLU SG_ 1355 CF_Vcu_CIL_Off 2000;
BA_REL_ "GenSigTimeoutTime" BU_SG_REL_ CLU SG_ 1355 CF_Vcu_CIL_Event 2000;
BA_REL_ "GenSigTimeoutTime" BU_SG_REL_ CLU SG_ 1355 CF_VCU_AuxBattChgUsmSts 2000;
BA_ "GenSigStartValue" SG_ 1355 CF_VCU_AuxBattChgUsmSts 2;
BA_REL_ "GenSigTimeoutTime" BU_SG_REL_ CLU SG_ 1355 CF_Vcu_CIL_Ctrl 0;
BA_REL_ "GenSigTimeoutTime" BU_SG_REL_ CLU SG_ 1355 CF_Vcu_SbwWarnMsg 2000;
BA_REL_ "GenSigTimeoutTime" BU_SG_REL_ EPB SG_ 1355 CF_Vcu_SbwWarnMsg 2000;
BA_REL_ "GenSigTimeoutTime" BU_SG_REL_ CLU SG_ 1355 CF_Vcu_SbwWarnSnd 2000;
BA_REL_ "GenSigTimeoutTime" BU_SG_REL_ CLU SG_ 1355 CF_Bms_ChgSts 2000;
BA_REL_ "GenSigTimeoutTime" BU_SG_REL_ CLU SG_ 1355 CR_Vcu_EDAS_FueSav 0;
BA_REL_ "GenSigTimeoutTime" BU_SG_REL_ CLU SG_ 1355 CF_Vcu_EDAS_FueSavSet 0;
BA_REL_ "GenSigTimeoutTime" BU_SG_REL_ CLU SG_ 1355 CF_Ldc_AuxBatChg_State 100;
BA_REL_ "GenSigTimeoutTime" BU_SG_REL_ CLU SG_ 1355 CF_Vcu_SbwWarnMsg2 2000;
BA_REL_ "GenSigTimeoutTime" BU_SG_REL_ CLU SG_ 1355 CF_Vcu_BatSav_Off 0;
BA_REL_ "GenSigTimeoutTime" BU_SG_REL_ CLU SG_ 1355 CF_Vcu_BatSav_Status 0;
BA_ "GenMsgCycleTime" BO_ 1291 100;
BA_REL_ "GenSigTimeoutTime" BU_SG_REL_ CLU SG_ 1291 CR_Bms_DisplaySoc 2000;
BA_REL_ "GenSigTimeoutTime" BU_SG_REL_ CLU SG_ 1291 CF_Vcu_ResvAirCtrInfo 2000;
BA_REL_ "GenSigTimeoutTime" BU_SG_REL_ CLU SG_ 1291 CF_Datc_ServiceLamp 2000;
BA_REL_ "GenSigTimeoutTime" BU_SG_REL_ CLU SG_ 1291 CF_Bms_PShiftForCharging 2000;
BA_REL_ "GenSigTimeoutTime" BU_SG_REL_ CLU SG_ 1291 CF_OBC_AC_CONNECT_FLAG 2000;
BA_REL_ "GenSigTimeoutTime" BU_SG_REL_ CLU SG_ 1291 CF_EVSE_FAULT_FLAG 2000;
BA_REL_ "GenSigTimeoutTime" BU_SG_REL_ CLU SG_ 1291 CF_OBC_MILReq 2000;
BA_REL_ "GenSigTimeoutTime" BU_SG_REL_ CLU SG_ 1291 CF_OBC_SERVICE_LAMP_Req 2000;
BA_REL_ "GenSigTimeoutTime" BU_SG_REL_ CLU SG_ 1291 CR_Datc_OutTemp_C 5000;
BA_REL_ "GenSigTimeoutTime" BU_SG_REL_ TPMS SG_ 1291 CR_Datc_OutTemp_C 5000;
BA_REL_ "GenSigTimeoutTime" BU_SG_REL_ CLU SG_ 1291 CR_Datc_OutTempF 5000;
BA_REL_ "GenSigTimeoutTime" BU_SG_REL_ CLU SG_ 1291 DATC_TempUnit 5000;
BA_ "GenSigStartValue" SG_ 1291 DATC_TempUnit 3;
BA_REL_ "GenSigTimeoutTime" BU_SG_REL_ CLU SG_ 1291 CF_Bms_FstEvseFltAlram 0;
BA_REL_ "GenSigTimeoutTime" BU_SG_REL_ CLU SG_ 1291 CF_Vcu_ResvInfo 2000;
BA_ "GenMsgSendType" BO_ 2015 8;
BA_ "GenMsgCycleTime" BO_ 2015 0;
BA_ "GenMsgNrOfRepetition" BO_ 2015 3;
BA_REL_ "GenSigTimeoutTime" BU_SG_REL_ ACU SG_ 2015 FRM_FORMAT 0;
BA_REL_ "GenSigTimeoutTime" BU_SG_REL_ AFLS SG_ 2015 FRM_FORMAT 0;
BA_REL_ "GenSigTimeoutTime" BU_SG_REL_ EPB SG_ 2015 FRM_FORMAT 0;
BA_REL_ "GenSigTimeoutTime" BU_SG_REL_ LCA SG_ 2015 FRM_FORMAT 0;
BA_REL_ "GenSigTimeoutTime" BU_SG_REL_ LDWS_LKAS SG_ 2015 FRM_FORMAT 0;
BA_REL_ "GenSigTimeoutTime" BU_SG_REL_ iBAU SG_ 2015 FRM_FORMAT 0;
BA_ "GenSigSendType" SG_ 2015 FRM_FORMAT 4;
BA_REL_ "GenSigTimeoutTime" BU_SG_REL_ ACU SG_ 2015 SID 0;
BA_REL_ "GenSigTimeoutTime" BU_SG_REL_ AFLS SG_ 2015 SID 0;
BA_REL_ "GenSigTimeoutTime" BU_SG_REL_ EPB SG_ 2015 SID 0;
BA_REL_ "GenSigTimeoutTime" BU_SG_REL_ LCA SG_ 2015 SID 0;
BA_REL_ "GenSigTimeoutTime" BU_SG_REL_ LDWS_LKAS SG_ 2015 SID 0;
BA_REL_ "GenSigTimeoutTime" BU_SG_REL_ iBAU SG_ 2015 SID 0;
BA_ "GenSigSendType" SG_ 2015 SID 4;
BA_REL_ "GenSigTimeoutTime" BU_SG_REL_ ACU SG_ 2015 REQ_RESPONSE 0;
BA_REL_ "GenSigTimeoutTime" BU_SG_REL_ AFLS SG_ 2015 REQ_RESPONSE 0;
BA_REL_ "GenSigTimeoutTime" BU_SG_REL_ EPB SG_ 2015 REQ_RESPONSE 0;
BA_REL_ "GenSigTimeoutTime" BU_SG_REL_ LCA SG_ 2015 REQ_RESPONSE 0;
BA_REL_ "GenSigTimeoutTime" BU_SG_REL_ LDWS_LKAS SG_ 2015 REQ_RESPONSE 0;
BA_REL_ "GenSigTimeoutTime" BU_SG_REL_ iBAU SG_ 2015 REQ_RESPONSE 0;
BA_ "GenSigSendType" SG_ 2015 REQ_RESPONSE 4;
BA_ "GenMsgCycleTime" BO_ 1470 1000;
BA_ "GenMsgNrOfRepetition" BO_ 1470 3;
BA_REL_ "GenSigTimeoutTime" BU_SG_REL_ SCC SG_ 1470 HU_NaviStatus 3500;
BA_ "GenSigSendType" SG_ 1470 HU_NaviStatus 4;
BA_ "GenSigStartValue" SG_ 1470 HU_NaviStatus 3;
BA_REL_ "GenSigTimeoutTime" BU_SG_REL_ SCC SG_ 1470 HU_NaviCamSettingStatus 3500;
BA_ "GenSigSendType" SG_ 1470 HU_NaviCamSettingStatus 4;
BA_ "GenMsgCycleTime" BO_ 1407 2000;
BA_ "GenMsgNrOfRepetition" BO_ 1407 3;
BA_REL_ "GenSigTimeoutTime" BU_SG_REL_ SCC SG_ 1407 HU_DistributeInfo 3500;
BA_ "GenSigSendType" SG_ 1407 HU_DistributeInfo 4;
BA_ "GenSigStartValue" SG_ 1407 HU_DistributeInfo 255;
BA_REL_ "GenSigTimeoutTime" BU_SG_REL_ SCC SG_ 1407 HU_AdasSupport 3500;
BA_ "GenSigSendType" SG_ 1407 HU_AdasSupport 4;
BA_ "GenMsgCycleTime" BO_ 1348 200;
BA_ "GenMsgNrOfRepetition" BO_ 1348 3;
BA_ "GenSigSendType" SG_ 1348 HU_AliveStatus 4;
BA_ "GenSigStartValue" SG_ 1348 HU_AliveStatus 3;
BA_ "GenMsgSendType" BO_ 545 8;
BA_ "GenMsgCycleTime" BO_ 545 0;
BA_ "GenMsgNrOfRepetition" BO_ 545 3;
BA_REL_ "GenSigTimeoutTime" BU_SG_REL_ SCC SG_ 545 META_MessageType 0;
BA_ "GenSigSendType" SG_ 545 META_MessageType 4;
BA_ "GenSigStartValue" SG_ 545 META_MessageType 7;
BA_REL_ "GenSigTimeoutTime" BU_SG_REL_ SCC SG_ 545 META_MapProvider 0;
BA_ "GenSigSendType" SG_ 545 META_MapProvider 4;
BA_ "GenSigStartValue" SG_ 545 META_MapProvider 7;
BA_REL_ "GenSigTimeoutTime" BU_SG_REL_ SCC SG_ 545 META_CountryCode 0;
BA_ "GenSigSendType" SG_ 545 META_CountryCode 4;
BA_ "GenSigStartValue" SG_ 545 META_CountryCode 1023;
BA_REL_ "GenSigTimeoutTime" BU_SG_REL_ SCC SG_ 545 META_CyclicCounter 0;
BA_ "GenSigSendType" SG_ 545 META_CyclicCounter 4;
BA_REL_ "GenSigTimeoutTime" BU_SG_REL_ SCC SG_ 545 META_MajorProtocolVersion 0;
BA_ "GenSigSendType" SG_ 545 META_MajorProtocolVersion 4;
BA_REL_ "GenSigTimeoutTime" BU_SG_REL_ SCC SG_ 545 META_MinorProtocolSubVer 0;
BA_ "GenSigSendType" SG_ 545 META_MinorProtocolSubVer 4;
BA_REL_ "GenSigTimeoutTime" BU_SG_REL_ SCC SG_ 545 META_HardwareVersion 0;
BA_ "GenSigSendType" SG_ 545 META_HardwareVersion 4;
BA_ "GenSigStartValue" SG_ 545 META_HardwareVersion 511;
BA_REL_ "GenSigTimeoutTime" BU_SG_REL_ SCC SG_ 545 META_DrivingSide 0;
BA_ "GenSigSendType" SG_ 545 META_DrivingSide 4;
BA_REL_ "GenSigTimeoutTime" BU_SG_REL_ SCC SG_ 545 META_RegionCode 0;
BA_ "GenSigSendType" SG_ 545 META_RegionCode 4;
BA_ "GenSigStartValue" SG_ 545 META_RegionCode 32767;
BA_REL_ "GenSigTimeoutTime" BU_SG_REL_ SCC SG_ 545 META_MapVersionQuarter 0;
BA_ "GenSigSendType" SG_ 545 META_MapVersionQuarter 4;
BA_REL_ "GenSigTimeoutTime" BU_SG_REL_ SCC SG_ 545 META_MapVersionYear 0;
BA_ "GenSigSendType" SG_ 545 META_MapVersionYear 4;
BA_ "GenSigStartValue" SG_ 545 META_MapVersionYear 63;
BA_REL_ "GenSigTimeoutTime" BU_SG_REL_ SCC SG_ 545 META_SpeedUnit 0;
BA_ "GenSigSendType" SG_ 545 META_SpeedUnit 4;
BA_REL_ "GenSigTimeoutTime" BU_SG_REL_ SCC SG_ 545 META_MinorProtocolVersion 0;
BA_ "GenSigSendType" SG_ 545 META_MinorProtocolVersion 4;
BA_ "GenMsgSendType" BO_ 546 8;
BA_ "GenMsgCycleTime" BO_ 546 0;
BA_ "GenMsgNrOfRepetition" BO_ 546 3;
BA_REL_ "GenSigTimeoutTime" BU_SG_REL_ SCC SG_ 546 POS_MessageType 0;
BA_ "GenSigSendType" SG_ 546 POS_MessageType 4;
BA_ "GenSigStartValue" SG_ 546 POS_MessageType 7;
BA_REL_ "GenSigTimeoutTime" BU_SG_REL_ SCC SG_ 546 POS_Offset 0;
BA_ "GenSigSendType" SG_ 546 POS_Offset 4;
BA_ "GenSigStartValue" SG_ 546 POS_Offset 8191;
BA_REL_ "GenSigTimeoutTime" BU_SG_REL_ SCC SG_ 546 POS_CyclicCounter 0;
BA_ "GenSigSendType" SG_ 546 POS_CyclicCounter 4;
BA_REL_ "GenSigTimeoutTime" BU_SG_REL_ SCC SG_ 546 POS_PathIndex 0;
BA_ "GenSigSendType" SG_ 546 POS_PathIndex 4;
BA_REL_ "GenSigTimeoutTime" BU_SG_REL_ SCC SG_ 546 POS_PositionIndex 0;
BA_ "GenSigSendType" SG_ 546 POS_PositionIndex 4;
BA_ "GenSigStartValue" SG_ 546 POS_PositionIndex 3;
BA_REL_ "GenSigTimeoutTime" BU_SG_REL_ SCC SG_ 546 POS_PositionProbability 0;
BA_ "GenSigSendType" SG_ 546 POS_PositionProbability 4;
BA_ "GenSigStartValue" SG_ 546 POS_PositionProbability 31;
BA_REL_ "GenSigTimeoutTime" BU_SG_REL_ SCC SG_ 546 POS_PositionAge 0;
BA_ "GenSigSendType" SG_ 546 POS_PositionAge 4;
BA_ "GenSigStartValue" SG_ 546 POS_PositionAge 511;
BA_REL_ "GenSigTimeoutTime" BU_SG_REL_ SCC SG_ 546 POS_PositionConfidence 0;
BA_ "GenSigSendType" SG_ 546 POS_PositionConfidence 4;
BA_ "GenSigStartValue" SG_ 546 POS_PositionConfidence 7;
BA_REL_ "GenSigTimeoutTime" BU_SG_REL_ SCC SG_ 546 POS_CurrentLane 0;
BA_ "GenSigSendType" SG_ 546 POS_CurrentLane 4;
BA_ "GenSigStartValue" SG_ 546 POS_CurrentLane 7;
BA_REL_ "GenSigTimeoutTime" BU_SG_REL_ SCC SG_ 546 POS_RangeAvgSpeed 0;
BA_ "GenSigSendType" SG_ 546 POS_RangeAvgSpeed 4;
BA_ "GenSigStartValue" SG_ 546 POS_RangeAvgSpeed 511;
BA_REL_ "GenSigTimeoutTime" BU_SG_REL_ SCC SG_ 546 POS_RelativeHeading 0;
BA_ "GenSigSendType" SG_ 546 POS_RelativeHeading 4;
BA_ "GenSigStartValue" SG_ 546 POS_RelativeHeading 255;
BA_ "GenMsgSendType" BO_ 547 8;
BA_ "GenMsgCycleTime" BO_ 547 0;
BA_ "GenMsgNrOfRepetition" BO_ 547 3;
BA_REL_ "GenSigTimeoutTime" BU_SG_REL_ SCC SG_ 547 PROLONG_Value 0;
BA_ "GenSigSendType" SG_ 547 PROLONG_Value 4;
BA_REL_ "GenSigTimeoutTime" BU_SG_REL_ SCC SG_ 547 PROLONG_MessageType 0;
BA_ "GenSigSendType" SG_ 547 PROLONG_MessageType 4;
BA_ "GenSigStartValue" SG_ 547 PROLONG_MessageType 7;
BA_REL_ "GenSigTimeoutTime" BU_SG_REL_ SCC SG_ 547 PROLONG_Offset 0;
BA_ "GenSigSendType" SG_ 547 PROLONG_Offset 4;
BA_ "GenSigStartValue" SG_ 547 PROLONG_Offset 8191;
BA_REL_ "GenSigTimeoutTime" BU_SG_REL_ SCC SG_ 547 PROLONG_CyclicCounter 0;
BA_ "GenSigSendType" SG_ 547 PROLONG_CyclicCounter 4;
BA_REL_ "GenSigTimeoutTime" BU_SG_REL_ SCC SG_ 547 PROLONG_PathIndex 0;
BA_ "GenSigSendType" SG_ 547 PROLONG_PathIndex 4;
BA_REL_ "GenSigTimeoutTime" BU_SG_REL_ SCC SG_ 547 PROLONG_ProfileType 0;
BA_ "GenSigSendType" SG_ 547 PROLONG_ProfileType 4;
BA_REL_ "GenSigTimeoutTime" BU_SG_REL_ SCC SG_ 547 PROLONG_CountrolPoint 0;
BA_ "GenSigSendType" SG_ 547 PROLONG_CountrolPoint 4;
BA_REL_ "GenSigTimeoutTime" BU_SG_REL_ SCC SG_ 547 PROLONG_Retransmission 0;
BA_ "GenSigSendType" SG_ 547 PROLONG_Retransmission 4;
BA_REL_ "GenSigTimeoutTime" BU_SG_REL_ SCC SG_ 547 PROLONG_Update 0;
BA_ "GenSigSendType" SG_ 547 PROLONG_Update 4;
BA_ "GenMsgSendType" BO_ 548 8;
BA_ "GenMsgCycleTime" BO_ 548 0;
BA_ "GenMsgNrOfRepetition" BO_ 548 3;
BA_REL_ "GenSigTimeoutTime" BU_SG_REL_ SCC SG_ 548 PROSHORT_MessageType 0;
BA_ "GenSigSendType" SG_ 548 PROSHORT_MessageType 4;
BA_ "GenSigStartValue" SG_ 548 PROSHORT_MessageType 7;
BA_REL_ "GenSigTimeoutTime" BU_SG_REL_ SCC SG_ 548 PROSHORT_Offset 0;
BA_ "GenSigSendType" SG_ 548 PROSHORT_Offset 4;
BA_ "GenSigStartValue" SG_ 548 PROSHORT_Offset 8191;
BA_REL_ "GenSigTimeoutTime" BU_SG_REL_ SCC SG_ 548 PROSHORT_CyclicCounter 0;
BA_ "GenSigSendType" SG_ 548 PROSHORT_CyclicCounter 4;
BA_REL_ "GenSigTimeoutTime" BU_SG_REL_ SCC SG_ 548 PROSHORT_PathIndex 0;
BA_ "GenSigSendType" SG_ 548 PROSHORT_PathIndex 4;
BA_REL_ "GenSigTimeoutTime" BU_SG_REL_ SCC SG_ 548 PROSHORT_Accuracy 0;
BA_ "GenSigSendType" SG_ 548 PROSHORT_Accuracy 4;
BA_ "GenSigStartValue" SG_ 548 PROSHORT_Accuracy 3;
BA_REL_ "GenSigTimeoutTime" BU_SG_REL_ SCC SG_ 548 PROSHORT_Distance 0;
BA_ "GenSigSendType" SG_ 548 PROSHORT_Distance 4;
BA_ "GenSigStartValue" SG_ 548 PROSHORT_Distance 1023;
BA_REL_ "GenSigTimeoutTime" BU_SG_REL_ SCC SG_ 548 PROSHORT_Value0 0;
BA_ "GenSigSendType" SG_ 548 PROSHORT_Value0 4;
BA_ "GenSigStartValue" SG_ 548 PROSHORT_Value0 1023;
BA_REL_ "GenSigTimeoutTime" BU_SG_REL_ SCC SG_ 548 PROSHORT_Value1 0;
BA_ "GenSigSendType" SG_ 548 PROSHORT_Value1 4;
BA_REL_ "GenSigTimeoutTime" BU_SG_REL_ SCC SG_ 548 PROSHORT_ProfileType 0;
BA_ "GenSigSendType" SG_ 548 PROSHORT_ProfileType 4;
BA_REL_ "GenSigTimeoutTime" BU_SG_REL_ SCC SG_ 548 PROSHORT_ControlPoint 0;
BA_ "GenSigSendType" SG_ 548 PROSHORT_ControlPoint 4;
BA_REL_ "GenSigTimeoutTime" BU_SG_REL_ SCC SG_ 548 PROSHORT_Retransmission 0;
BA_ "GenSigSendType" SG_ 548 PROSHORT_Retransmission 4;
BA_REL_ "GenSigTimeoutTime" BU_SG_REL_ SCC SG_ 548 PROSHORT_Update 0;
BA_ "GenSigSendType" SG_ 548 PROSHORT_Update 4;
BA_ "GenMsgSendType" BO_ 549 8;
BA_ "GenMsgCycleTime" BO_ 549 0;
BA_ "GenMsgNrOfRepetition" BO_ 549 3;
BA_REL_ "GenSigTimeoutTime" BU_SG_REL_ SCC SG_ 549 SEG_MessageType 0;
BA_ "GenSigSendType" SG_ 549 SEG_MessageType 4;
BA_ "GenSigStartValue" SG_ 549 SEG_MessageType 7;
BA_REL_ "GenSigTimeoutTime" BU_SG_REL_ SCC SG_ 549 SEG_Offset 0;
BA_ "GenSigSendType" SG_ 549 SEG_Offset 4;
BA_ "GenSigStartValue" SG_ 549 SEG_Offset 8191;
BA_REL_ "GenSigTimeoutTime" BU_SG_REL_ SCC SG_ 549 SEG_CyclicCounter 0;
BA_ "GenSigSendType" SG_ 549 SEG_CyclicCounter 4;
BA_REL_ "GenSigTimeoutTime" BU_SG_REL_ SCC SG_ 549 SEG_PathIndex 0;
BA_ "GenSigSendType" SG_ 549 SEG_PathIndex 4;
BA_REL_ "GenSigTimeoutTime" BU_SG_REL_ SCC SG_ 549 SEG_Tunnel 0;
BA_ "GenSigSendType" SG_ 549 SEG_Tunnel 4;
BA_ "GenSigStartValue" SG_ 549 SEG_Tunnel 3;
BA_REL_ "GenSigTimeoutTime" BU_SG_REL_ SCC SG_ 549 SEG_Bridge 0;
BA_ "GenSigSendType" SG_ 549 SEG_Bridge 4;
BA_ "GenSigStartValue" SG_ 549 SEG_Bridge 3;
BA_REL_ "GenSigTimeoutTime" BU_SG_REL_ SCC SG_ 549 SEG_BuiltUpArea 0;
BA_ "GenSigSendType" SG_ 549 SEG_BuiltUpArea 4;
BA_ "GenSigStartValue" SG_ 549 SEG_BuiltUpArea 3;
BA_REL_ "GenSigTimeoutTime" BU_SG_REL_ SCC SG_ 549 SEG_Retransmission 0;
BA_ "GenSigSendType" SG_ 549 SEG_Retransmission 4;
BA_REL_ "GenSigTimeoutTime" BU_SG_REL_ SCC SG_ 549 SEG_Update 0;
BA_ "GenSigSendType" SG_ 549 SEG_Update 4;
BA_REL_ "GenSigTimeoutTime" BU_SG_REL_ SCC SG_ 549 SEG_RelativeProbability 0;
BA_ "GenSigSendType" SG_ 549 SEG_RelativeProbability 4;
BA_ "GenSigStartValue" SG_ 549 SEG_RelativeProbability 31;
BA_REL_ "GenSigTimeoutTime" BU_SG_REL_ SCC SG_ 549 SEG_FunctionalRoadClass 0;
BA_ "GenSigSendType" SG_ 549 SEG_FunctionalRoadClass 4;
BA_ "GenSigStartValue" SG_ 549 SEG_FunctionalRoadClass 7;
BA_REL_ "GenSigTimeoutTime" BU_SG_REL_ SCC SG_ 549 SEG_CalculatedRoute 0;
BA_ "GenSigSendType" SG_ 549 SEG_CalculatedRoute 4;
BA_ "GenSigStartValue" SG_ 549 SEG_CalculatedRoute 3;
BA_REL_ "GenSigTimeoutTime" BU_SG_REL_ SCC SG_ 549 SEG_ComplexIntersection 0;
BA_ "GenSigSendType" SG_ 549 SEG_ComplexIntersection 4;
BA_ "GenSigStartValue" SG_ 549 SEG_ComplexIntersection 3;
BA_REL_ "GenSigTimeoutTime" BU_SG_REL_ SCC SG_ 549 SEG_FormOfWay 0;
BA_ "GenSigSendType" SG_ 549 SEG_FormOfWay 4;
BA_ "GenSigStartValue" SG_ 549 SEG_FormOfWay 15;
BA_REL_ "GenSigTimeoutTime" BU_SG_REL_ SCC SG_ 549 SEG_SpeedLimit 0;
BA_ "GenSigSendType" SG_ 549 SEG_SpeedLimit 4;
BA_ "GenSigStartValue" SG_ 549 SEG_SpeedLimit 31;
BA_REL_ "GenSigTimeoutTime" BU_SG_REL_ SCC SG_ 549 SEG_SpeedLimitType 0;
BA_ "GenSigSendType" SG_ 549 SEG_SpeedLimitType 4;
BA_ "GenSigStartValue" SG_ 549 SEG_SpeedLimitType 7;
BA_REL_ "GenSigTimeoutTime" BU_SG_REL_ SCC SG_ 549 SEG_DividedRoad 0;
BA_ "GenSigSendType" SG_ 549 SEG_DividedRoad 4;
BA_ "GenSigStartValue" SG_ 549 SEG_DividedRoad 3;
BA_REL_ "GenSigTimeoutTime" BU_SG_REL_ SCC SG_ 549 SEG_OppositeLanes 0;
BA_ "GenSigSendType" SG_ 549 SEG_OppositeLanes 4;
BA_ "GenSigStartValue" SG_ 549 SEG_OppositeLanes 3;
BA_REL_ "GenSigTimeoutTime" BU_SG_REL_ SCC SG_ 549 SEG_DirectionLanes 0;
BA_ "GenSigSendType" SG_ 549 SEG_DirectionLanes 4;
BA_ "GenSigStartValue" SG_ 549 SEG_DirectionLanes 7;
BA_ "GenMsgSendType" BO_ 550 8;
BA_ "GenMsgCycleTime" BO_ 550 0;
BA_ "GenMsgNrOfRepetition" BO_ 550 3;
BA_REL_ "GenSigTimeoutTime" BU_SG_REL_ SCC SG_ 550 STUB_MessageType 0;
BA_ "GenSigSendType" SG_ 550 STUB_MessageType 4;
BA_ "GenSigStartValue" SG_ 550 STUB_MessageType 7;
BA_REL_ "GenSigTimeoutTime" BU_SG_REL_ SCC SG_ 550 STUB_Offset 0;
BA_ "GenSigSendType" SG_ 550 STUB_Offset 4;
BA_ "GenSigStartValue" SG_ 550 STUB_Offset 8191;
BA_REL_ "GenSigTimeoutTime" BU_SG_REL_ SCC SG_ 550 STUB_CyclicCounter 0;
BA_ "GenSigSendType" SG_ 550 STUB_CyclicCounter 4;
BA_REL_ "GenSigTimeoutTime" BU_SG_REL_ SCC SG_ 550 STUB_PathIndex 0;
BA_ "GenSigSendType" SG_ 550 STUB_PathIndex 4;
BA_REL_ "GenSigTimeoutTime" BU_SG_REL_ SCC SG_ 550 STUB_SubPathIndex 0;
BA_ "GenSigSendType" SG_ 550 STUB_SubPathIndex 4;
BA_REL_ "GenSigTimeoutTime" BU_SG_REL_ SCC SG_ 550 STUB_Retransmission 0;
BA_ "GenSigSendType" SG_ 550 STUB_Retransmission 4;
BA_REL_ "GenSigTimeoutTime" BU_SG_REL_ SCC SG_ 550 STUB_Update 0;
BA_ "GenSigSendType" SG_ 550 STUB_Update 4;
BA_REL_ "GenSigTimeoutTime" BU_SG_REL_ SCC SG_ 550 STUB_RelativeProbability 0;
BA_ "GenSigSendType" SG_ 550 STUB_RelativeProbability 4;
BA_ "GenSigStartValue" SG_ 550 STUB_RelativeProbability 31;
BA_REL_ "GenSigTimeoutTime" BU_SG_REL_ SCC SG_ 550 STUB_FunctionalRoadClass 0;
BA_ "GenSigSendType" SG_ 550 STUB_FunctionalRoadClass 4;
BA_ "GenSigStartValue" SG_ 550 STUB_FunctionalRoadClass 7;
BA_REL_ "GenSigTimeoutTime" BU_SG_REL_ SCC SG_ 550 STUB_CalculatedRoute 0;
BA_ "GenSigSendType" SG_ 550 STUB_CalculatedRoute 4;
BA_ "GenSigStartValue" SG_ 550 STUB_CalculatedRoute 3;
BA_REL_ "GenSigTimeoutTime" BU_SG_REL_ SCC SG_ 550 STUB_ComplexIntersection 0;
BA_ "GenSigSendType" SG_ 550 STUB_ComplexIntersection 4;
BA_ "GenSigStartValue" SG_ 550 STUB_ComplexIntersection 3;
BA_REL_ "GenSigTimeoutTime" BU_SG_REL_ SCC SG_ 550 STUB_FormOfWay 0;
BA_ "GenSigSendType" SG_ 550 STUB_FormOfWay 4;
BA_ "GenSigStartValue" SG_ 550 STUB_FormOfWay 15;
BA_REL_ "GenSigTimeoutTime" BU_SG_REL_ SCC SG_ 550 STUB_TurnAngle 0;
BA_ "GenSigSendType" SG_ 550 STUB_TurnAngle 4;
BA_ "GenSigStartValue" SG_ 550 STUB_TurnAngle 255;
BA_REL_ "GenSigTimeoutTime" BU_SG_REL_ SCC SG_ 550 STUB_LastStubAtOffset 0;
BA_ "GenSigSendType" SG_ 550 STUB_LastStubAtOffset 4;
BA_REL_ "GenSigTimeoutTime" BU_SG_REL_ SCC SG_ 550 STUB_RightOfWay 0;
BA_ "GenSigSendType" SG_ 550 STUB_RightOfWay 4;
BA_ "GenSigStartValue" SG_ 550 STUB_RightOfWay 3;
BA_REL_ "GenSigTimeoutTime" BU_SG_REL_ SCC SG_ 550 STUB_OppositeLanes 0;
BA_ "GenSigSendType" SG_ 550 STUB_OppositeLanes 4;
BA_ "GenSigStartValue" SG_ 550 STUB_OppositeLanes 3;
BA_REL_ "GenSigTimeoutTime" BU_SG_REL_ SCC SG_ 550 STUB_DirectionLanes 0;
BA_ "GenSigSendType" SG_ 550 STUB_DirectionLanes 4;
BA_ "GenSigStartValue" SG_ 550 STUB_DirectionLanes 7;
BA_ "GenMsgCycleTime" BO_ 1078 50;
BA_ "GenMsgNrOfRepetition" BO_ 1078 3;
BA_REL_ "GenSigTimeoutTime" BU_SG_REL_ CLU SG_ 1078 CF_Gway_PASDisplayFLH 1000;
BA_ "GenSigSendType" SG_ 1078 CF_Gway_PASDisplayFLH 4;
BA_REL_ "GenSigTimeoutTime" BU_SG_REL_ CLU SG_ 1078 CF_Gway_PASDisplayFRH 1000;
BA_ "GenSigSendType" SG_ 1078 CF_Gway_PASDisplayFRH 4;
BA_REL_ "GenSigTimeoutTime" BU_SG_REL_ CLU SG_ 1078 CF_Gway_PASRsound 1000;
BA_ "GenSigSendType" SG_ 1078 CF_Gway_PASRsound 4;
BA_REL_ "GenSigTimeoutTime" BU_SG_REL_ CLU SG_ 1078 CF_Gway_PASDisplayFCTR 1000;
BA_ "GenSigSendType" SG_ 1078 CF_Gway_PASDisplayFCTR 4;
BA_REL_ "GenSigTimeoutTime" BU_SG_REL_ CLU SG_ 1078 CF_Gway_PASDisplayRCTR 1000;
BA_ "GenSigSendType" SG_ 1078 CF_Gway_PASDisplayRCTR 4;
BA_REL_ "GenSigTimeoutTime" BU_SG_REL_ CLU SG_ 1078 CF_Gway_PASFsound 1000;
BA_ "GenSigSendType" SG_ 1078 CF_Gway_PASFsound 4;
BA_REL_ "GenSigTimeoutTime" BU_SG_REL_ CLU SG_ 1078 CF_Gway_PASDisplayRLH 1000;
BA_ "GenSigSendType" SG_ 1078 CF_Gway_PASDisplayRLH 4;
BA_REL_ "GenSigTimeoutTime" BU_SG_REL_ CLU SG_ 1078 CF_Gway_PASDisplayRRH 1000;
BA_ "GenSigSendType" SG_ 1078 CF_Gway_PASDisplayRRH 4;
BA_REL_ "GenSigTimeoutTime" BU_SG_REL_ CLU SG_ 1078 CF_Gway_PASCheckSound 1000;
BA_ "GenSigSendType" SG_ 1078 CF_Gway_PASCheckSound 4;
BA_REL_ "GenSigTimeoutTime" BU_SG_REL_ CLU SG_ 1078 CF_Gway_PASSystemOn 1000;
BA_ "GenSigSendType" SG_ 1078 CF_Gway_PASSystemOn 4;
BA_REL_ "GenSigTimeoutTime" BU_SG_REL_ CLU SG_ 1078 CF_Gway_PASOption 1000;
BA_ "GenSigSendType" SG_ 1078 CF_Gway_PASOption 4;
BA_ "GenMsgCycleTime" BO_ 1136 20;
BA_ "GenSigStartValue" SG_ 1136 VCU1_STS 1;
BA_ "GenSigStartValue" SG_ 1136 EBS1_STS 1;
BA_ "GenSigStartValue" SG_ 1136 MCU1_STS 1;
BA_ "GenSigStartValue" SG_ 1136 MCU3_STS 1;
BA_ "GenSigStartValue" SG_ 1136 VCU3_STS 1;
BA_ "GenSigStartValue" SG_ 1136 VCU5_STS 1;
BA_ "GenSigStartValue" SG_ 1136 LVR1_STS 1;
BA_ "GenSigStartValue" SG_ 1136 VCU2_STS 1;
BA_ "GenMsgCycleTime" BO_ 1426 100;
BA_REL_ "GenSigTimeoutTime" BU_SG_REL_ CLU SG_ 1426 CF_Vcu_LowSocLp 2000;
BA_REL_ "GenSigTimeoutTime" BU_SG_REL_ CLU SG_ 1426 CF_Vcu_DteOff 2000;
BA_REL_ "GenSigTimeoutTime" BU_SG_REL_ CLU SG_ 1426 CF_Vcu_SerLamp 2000;
BA_REL_ "GenSigTimeoutTime" BU_SG_REL_ CLU SG_ 1426 CF_Vcu_EcoSco 2000;
BA_REL_ "GenSigTimeoutTime" BU_SG_REL_ CLU SG_ 1426 CR_Vcu_FuelEco_KP100km 2000;
BA_REL_ "GenSigTimeoutTime" BU_SG_REL_ CLU SG_ 1426 CF_Vcu_ChrgAlert 2000;
BA_REL_ "GenSigTimeoutTime" BU_SG_REL_ CLU SG_ 1426 CF_Vcu_PwrDnMode 2000;
BA_REL_ "GenSigTimeoutTime" BU_SG_REL_ CLU SG_ 1426 CF_Vcu_CruOnLamp 2000;
BA_REL_ "GenSigTimeoutTime" BU_SG_REL_ CLU SG_ 1426 CF_Vcu_CruSetLamp 2000;
BA_REL_ "GenSigTimeoutTime" BU_SG_REL_ CLU SG_ 1426 CR_Vcu_TqMotClu_Pc 2000;
BA_REL_ "GenSigTimeoutTime" BU_SG_REL_ CLU SG_ 1426 CR_Vcu_FuelEco_KPK 2000;
BA_REL_ "GenSigTimeoutTime" BU_SG_REL_ EPB SG_ 1426 CF_Vcu_BrkLpReq 2000;
BA_REL_ "GenSigTimeoutTime" BU_SG_REL_ SCC SG_ 1426 CF_Vcu_BrkLpReq 2000;
BA_REL_ "GenSigTimeoutTime" BU_SG_REL_ CLU SG_ 1426 CF_Vcu_EvMod 2000;
BA_REL_ "GenSigTimeoutTime" BU_SG_REL_ EPB SG_ 1426 CF_Vcu_EvMod 2000;
BA_ "GenMsgCycleTime" BO_ 1507 1000;
BA_ "GenMsgNrOfRepetition" BO_ 1507 3;
BA_REL_ "GenSigTimeoutTime" BU_SG_REL_ CLU SG_ 1507 CR_VCU_EcoLvl 5000;
BA_ "GenSigSendType" SG_ 1507 CR_VCU_EcoLvl 4;
BA_ "GenMsgCycleTime" BO_ 1265 20;
BA_ "GenMsgCycleTime" BO_ 1456 1000;
BA_REL_ "GenSigTimeoutTime" BU_SG_REL_ CGW SG_ 1456 CF_Clu_Odometer 5000;
BA_REL_ "GenSigTimeoutTime" BU_SG_REL_ EPB SG_ 1456 CF_Clu_Odometer 5000;
BA_REL_ "GenSigTimeoutTime" BU_SG_REL_ SCC SG_ 1456 CF_Clu_Odometer 5000;
BA_ "GenMsgCycleTime" BO_ 1292 100;
BA_REL_ "GenSigTimeoutTime" BU_SG_REL_ CGW SG_ 1292 CF_Clu_LowfuelWarn 1000;
BA_REL_ "GenSigTimeoutTime" BU_SG_REL_ CGW SG_ 1292 CF_Clu_RefDetMod 1000;
BA_REL_ "GenSigTimeoutTime" BU_SG_REL_ iBAU SG_ 1292 CF_Clu_AvsmCur 1000;
BA_REL_ "GenSigTimeoutTime" BU_SG_REL_ LDWS_LKAS SG_ 1292 CF_Clu_DrivingModeSwi 1000;
BA_REL_ "GenSigTimeoutTime" BU_SG_REL_ MDPS SG_ 1292 CF_Clu_DrivingModeSwi 1000;
BA_REL_ "GenSigTimeoutTime" BU_SG_REL_ iBAU SG_ 1292 CF_Clu_DrivingModeSwi 1000;
BA_REL_ "GenSigTimeoutTime" BU_SG_REL_ ACU SG_ 1292 CF_Clu_SWL_Stat 1000;
BA_REL_ "GenSigTimeoutTime" BU_SG_REL_ CGW SG_ 1292 CF_Clu_ActiveEcoSW 1000;
BA_REL_ "GenSigTimeoutTime" BU_SG_REL_ CGW SG_ 1292 CF_Clu_DriveModeSW 1000;
BA_REL_ "GenSigTimeoutTime" BU_SG_REL_ LDWS_LKAS SG_ 1292 CF_Clu_AALastBreakTime 1000;
BA_REL_ "GenSigTimeoutTime" BU_SG_REL_ CGW SG_ 1292 CF_Clu_AltLStatus 1000;
BA_REL_ "GenSigTimeoutTime" BU_SG_REL_ LDWS_LKAS SG_ 1292 CF_Clu_AliveCnt2 1000;
BA_ "GenMsgSendType" BO_ 1301 8;
BA_ "GenMsgCycleTime" BO_ 1301 0;
BA_ "GenMsgNrOfRepetition" BO_ 1301 3;
BA_REL_ "GenSigTimeoutTime" BU_SG_REL_ CGW SG_ 1301 CF_Clu_ADrUNValueSet 0;
BA_ "GenSigSendType" SG_ 1301 CF_Clu_ADrUNValueSet 4;
BA_REL_ "GenSigTimeoutTime" BU_SG_REL_ CGW SG_ 1301 CF_Clu_ADrLNValueSet 0;
BA_ "GenSigSendType" SG_ 1301 CF_Clu_ADrLNValueSet 4;
BA_REL_ "GenSigTimeoutTime" BU_SG_REL_ CGW SG_ 1301 CF_Clu_EscortHLNValueSet 0;
BA_ "GenSigSendType" SG_ 1301 CF_Clu_EscortHLNValueSet 4;
BA_ "GenSigSendType" SG_ 1301 CF_Clu_DoorLSNValueSet 4;
BA_REL_ "GenSigTimeoutTime" BU_SG_REL_ CGW SG_ 1301 CF_Clu_PSMNValueSet 0;
BA_ "GenSigSendType" SG_ 1301 CF_Clu_PSMNValueSet 4;
BA_REL_ "GenSigTimeoutTime" BU_SG_REL_ CGW SG_ 1301 CF_Clu_TTUnlockNValueSet 0;
BA_ "GenSigSendType" SG_ 1301 CF_Clu_TTUnlockNValueSet 4;
BA_ "GenSigSendType" SG_ 1301 CF_Clu_ATTurnNValueSet 4;
BA_ "GenSigSendType" SG_ 1301 CF_Clu_SCMNValueSet 4;
BA_REL_ "GenSigTimeoutTime" BU_SG_REL_ CGW SG_ 1301 CF_Clu_WlightNValueSet 0;
BA_ "GenSigSendType" SG_ 1301 CF_Clu_WlightNValueSet 4;
BA_REL_ "GenSigTimeoutTime" BU_SG_REL_ CGW SG_ 1301 CF_Clu_TempUnitNValueSet 0;
BA_ "GenSigSendType" SG_ 1301 CF_Clu_TempUnitNValueSet 4;
BA_ "GenSigSendType" SG_ 1301 CF_Clu_TrfChgSet 4;
BA_REL_ "GenSigTimeoutTime" BU_SG_REL_ CGW SG_ 1301 CF_Clu_OTTurnNValueSet 0;
BA_ "GenSigSendType" SG_ 1301 CF_Clu_OTTurnNValueSet 4;
BA_REL_ "GenSigTimeoutTime" BU_SG_REL_ LCA SG_ 1301 CF_Clu_LcaNValueSet 0;
BA_ "GenSigSendType" SG_ 1301 CF_Clu_LcaNValueSet 4;
BA_REL_ "GenSigTimeoutTime" BU_SG_REL_ LCA SG_ 1301 CF_Clu_RctaNValueSet 0;
BA_ "GenSigSendType" SG_ 1301 CF_Clu_RctaNValueSet 4;
BA_ "GenSigSendType" SG_ 1301 CF_Clu_RcwNValueSet 4;
BA_REL_ "GenSigTimeoutTime" BU_SG_REL_ iBAU SG_ 1301 CF_Clu_EcsOffNValueSet 0;
BA_ "GenSigSendType" SG_ 1301 CF_Clu_EcsOffNValueSet 4;
BA_ "GenSigSendType" SG_ 1301 CF_Clu_SccNaviCrvNValueSet 4;
BA_REL_ "GenSigTimeoutTime" BU_SG_REL_ SCC SG_ 1301 CF_Clu_SccNaviCamNValueSet 0;
BA_ "GenSigSendType" SG_ 1301 CF_Clu_SccNaviCamNValueSet 4;
BA_REL_ "GenSigTimeoutTime" BU_SG_REL_ SCC SG_ 1301 CF_Clu_SccAebNValueSet 0;
BA_ "GenSigSendType" SG_ 1301 CF_Clu_SccAebNValueSet 4;
BA_REL_ "GenSigTimeoutTime" BU_SG_REL_ LDWS_LKAS SG_ 1301 CF_Clu_LkasModeNValueSet 0;
BA_ "GenSigSendType" SG_ 1301 CF_Clu_LkasModeNValueSet 4;
BA_ "GenSigSendType" SG_ 1301 CF_Clu_FcwNValueSet 4;
BA_REL_ "GenSigTimeoutTime" BU_SG_REL_ CGW SG_ 1301 CF_Clu_PasSpkrLvNValueSet 0;
BA_ "GenSigSendType" SG_ 1301 CF_Clu_PasSpkrLvNValueSet 4;
BA_REL_ "GenSigTimeoutTime" BU_SG_REL_ SCC SG_ 1301 CF_Clu_SccDrvModeNValueSet 0;
BA_ "GenSigSendType" SG_ 1301 CF_Clu_SccDrvModeNValueSet 4;
BA_REL_ "GenSigTimeoutTime" BU_SG_REL_ CGW SG_ 1301 CF_Clu_HAnBNValueSet 0;
BA_ "GenSigSendType" SG_ 1301 CF_Clu_HAnBNValueSet 4;
BA_REL_ "GenSigTimeoutTime" BU_SG_REL_ CGW SG_ 1301 CF_Clu_HfreeTrunkTgNValueSet 0;
BA_ "GenSigSendType" SG_ 1301 CF_Clu_HfreeTrunkTgNValueSet 4;
BA_ "GenMsgCycleTime" BO_ 1322 200;
BA_ "GenMsgNrOfRepetition" BO_ 1322 3;
BA_REL_ "GenSigTimeoutTime" BU_SG_REL_ CGW SG_ 1322 CF_Clu_VehicleSpeed 1000;
BA_ "GenSigSendType" SG_ 1322 CF_Clu_VehicleSpeed 4;
BA_ "GenSigSendType" SG_ 1322 CF_Clu_InhibitP 4;
BA_ "GenSigSendType" SG_ 1322 CF_Clu_InhibitR 4;
BA_ "GenSigSendType" SG_ 1322 CF_Clu_InhibitN 4;
BA_ "GenSigSendType" SG_ 1322 CF_Clu_InhibitD 4;
BA_REL_ "GenSigTimeoutTime" BU_SG_REL_ PGS SG_ 1322 CF_Clu_LanguageInfo 1000;
BA_ "GenSigSendType" SG_ 1322 CF_Clu_LanguageInfo 4;
BA_ "GenSigSendType" SG_ 1322 CF_Clu_ClusterSound 4;
BA_ "GenMsgSendType" BO_ 1307 8;
BA_ "GenMsgCycleTime" BO_ 1307 0;
BA_ "GenMsgNrOfRepetition" BO_ 1307 3;
BA_REL_ "GenSigTimeoutTime" BU_SG_REL_ TPMS SG_ 1307 CF_Clu_TirePressUnitNValueSet 0;
BA_ "GenSigSendType" SG_ 1307 CF_Clu_TirePressUnitNValueSet 4;
BA_ "GenSigSendType" SG_ 1307 CF_Clu_SlifNValueSet 4;
BA_ "GenSigSendType" SG_ 1307 CF_Clu_AutoLightNValueSet 4;
BA_REL_ "GenSigTimeoutTime" BU_SG_REL_ CGW SG_ 1307 CF_Clu_FuelGuideReset 0;
BA_ "GenSigSendType" SG_ 1307 CF_Clu_FuelGuideReset 4;
BA_REL_ "GenSigTimeoutTime" BU_SG_REL_ LDWS_LKAS SG_ 1307 CF_Clu_DAWModeNValueSet 0;
BA_ "GenSigSendType" SG_ 1307 CF_Clu_DAWModeNValueSet 4;
BA_ "GenSigSendType" SG_ 1307 CF_Clu_AebModeNValueSet 4;
BA_REL_ "GenSigTimeoutTime" BU_SG_REL_ CGW SG_ 1307 CF_Clu_ECoastingNvalueSet 0;
BA_ "GenSigSendType" SG_ 1307 CF_Clu_ECoastingNvalueSet 4;
BA_REL_ "GenSigTimeoutTime" BU_SG_REL_ CGW SG_ 1307 CF_Clu_USMReset 0;
BA_REL_ "GenSigTimeoutTime" BU_SG_REL_ LCA SG_ 1307 CF_Clu_USMReset 0;
BA_REL_ "GenSigTimeoutTime" BU_SG_REL_ LDWS_LKAS SG_ 1307 CF_Clu_USMReset 0;
BA_REL_ "GenSigTimeoutTime" BU_SG_REL_ SCC SG_ 1307 CF_Clu_USMReset 0;
BA_REL_ "GenSigTimeoutTime" BU_SG_REL_ TPMS SG_ 1307 CF_Clu_USMReset 0;
BA_ "GenSigSendType" SG_ 1307 CF_Clu_USMReset 4;
BA_REL_ "GenSigTimeoutTime" BU_SG_REL_ CGW SG_ 1307 CF_Gway_WPCNValueSet 0;
BA_ "GenSigSendType" SG_ 1307 CF_Gway_WPCNValueSet 4;
BA_REL_ "GenSigTimeoutTime" BU_SG_REL_ CGW SG_ 1307 CF_Clu_ECoastWarnNValueSet 0;
BA_ "GenSigSendType" SG_ 1307 CF_Clu_ECoastWarnNValueSet 4;
BA_REL_ "GenSigTimeoutTime" BU_SG_REL_ CGW SG_ 1307 CF_Clu_AuxBatChargeNValueSet 0;
BA_ "GenSigSendType" SG_ 1307 CF_Clu_AuxBatChargeNValueSet 4;
BA_REL_ "GenSigTimeoutTime" BU_SG_REL_ CGW SG_ 1307 CF_Clu_ECoastCtrlNValueSet 0;
BA_ "GenSigSendType" SG_ 1307 CF_Clu_ECoastCtrlNValueSet 4;
BA_ "GenMsgCycleTime" BO_ 1168 50;
BA_ "GenSigStartValue" SG_ 1168 EPB_FAIL 2;
BA_ "GenSigStartValue" SG_ 1168 EPB_FORCE 1000;
BA_ "GenMsgCycleTime" BO_ 1419 50;
BA_ "GenSigStartValue" SG_ 832 CR_Lkas_StrToqReq 1024;
BA_ "GenMsgCycleTime" BO_ 1342 100;
BA_ "GenMsgCycleTime" BO_ 897 20;
BA_ "GenSigStartValue" SG_ 593 CR_Mdps_StrColTq 1024;
BA_ "GenSigStartValue" SG_ 593 CR_Mdps_StrTq 2048;
BA_ "GenSigStartValue" SG_ 593 CR_Mdps_OutTq 2048;
BA_REL_ "GenSigTimeoutTime" BU_SG_REL_ AFLS SG_ 688 SAS_Angle 100;
BA_REL_ "GenSigTimeoutTime" BU_SG_REL_ CGW SG_ 688 SAS_Angle 100;
BA_REL_ "GenSigTimeoutTime" BU_SG_REL_ CLU SG_ 688 SAS_Angle 100;
BA_REL_ "GenSigTimeoutTime" BU_SG_REL_ LCA SG_ 688 SAS_Angle 100;
BA_REL_ "GenSigTimeoutTime" BU_SG_REL_ LDWS_LKAS SG_ 688 SAS_Angle 100;
BA_REL_ "GenSigTimeoutTime" BU_SG_REL_ PGS SG_ 688 SAS_Angle 100;
BA_REL_ "GenSigTimeoutTime" BU_SG_REL_ SCC SG_ 688 SAS_Angle 100;
BA_REL_ "GenSigTimeoutTime" BU_SG_REL_ iBAU SG_ 688 SAS_Angle 100;
BA_REL_ "GenSigTimeoutTime" BU_SG_REL_ AFLS SG_ 688 SAS_Speed 100;
BA_REL_ "GenSigTimeoutTime" BU_SG_REL_ LDWS_LKAS SG_ 688 SAS_Speed 100;
BA_REL_ "GenSigTimeoutTime" BU_SG_REL_ SCC SG_ 688 SAS_Speed 100;
BA_REL_ "GenSigTimeoutTime" BU_SG_REL_ iBAU SG_ 688 SAS_Speed 100;
BA_REL_ "GenSigTimeoutTime" BU_SG_REL_ LDWS_LKAS SG_ 688 SAS_Stat 100;
BA_REL_ "GenSigTimeoutTime" BU_SG_REL_ SCC SG_ 688 SAS_Stat 100;
BA_REL_ "GenSigTimeoutTime" BU_SG_REL_ iBAU SG_ 688 SAS_Stat 100;
BA_ "GenSigStartValue" SG_ 688 SAS_Stat 7;
BA_REL_ "GenSigTimeoutTime" BU_SG_REL_ LDWS_LKAS SG_ 688 MsgCount 100;
BA_REL_ "GenSigTimeoutTime" BU_SG_REL_ SCC SG_ 688 MsgCount 100;
BA_REL_ "GenSigTimeoutTime" BU_SG_REL_ iBAU SG_ 688 MsgCount 100;
BA_REL_ "GenSigTimeoutTime" BU_SG_REL_ LDWS_LKAS SG_ 688 CheckSum 100;
BA_REL_ "GenSigTimeoutTime" BU_SG_REL_ SCC SG_ 688 CheckSum 100;
BA_REL_ "GenSigTimeoutTime" BU_SG_REL_ iBAU SG_ 688 CheckSum 100;
BA_ "GenMsgCycleTime" BO_ 1056 20;
BA_ "GenSigStartValue" SG_ 1056 ACC_ObjStatus 3;
BA_ "GenSigStartValue" SG_ 1056 ACC_ObjLatPos 511;
BA_ "GenSigStartValue" SG_ 1056 ACC_ObjDist 2047;
BA_ "GenSigStartValue" SG_ 1056 ACC_ObjRelSpd 4095;
BA_ "GenMsgCycleTime" BO_ 1057 20;
BA_ "GenMsgCycleTime" BO_ 1290 200;
BA_ "GenMsgNrOfRepetition" BO_ 1290 3;
BA_REL_ "GenSigTimeoutTime" BU_SG_REL_ CLU SG_ 1290 SCCDrvModeRValue 0;
BA_ "GenSigSendType" SG_ 1290 SCCDrvModeRValue 4;
BA_ "GenSigStartValue" SG_ 1290 SCCDrvModeRValue 2;
BA_REL_ "GenSigTimeoutTime" BU_SG_REL_ iBAU SG_ 1290 SCC_Equip 2000;
BA_ "GenSigSendType" SG_ 1290 SCC_Equip 4;
BA_REL_ "GenSigTimeoutTime" BU_SG_REL_ CLU SG_ 1290 AebDrvSetStatus 2000;
BA_REL_ "GenSigTimeoutTime" BU_SG_REL_ iBAU SG_ 1290 AebDrvSetStatus 2000;
BA_ "GenSigSendType" SG_ 1290 AebDrvSetStatus 4;
BA_ "GenSigStartValue" SG_ 1290 AebDrvSetStatus 1;
BA_ "GenMsgCycleTime" BO_ 1427 200;
BA_REL_ "GenSigTimeoutTime" BU_SG_REL_ CGW SG_ 1427 TPMS_W_LAMP 2000;
BA_REL_ "GenSigTimeoutTime" BU_SG_REL_ CLU SG_ 1427 TPMS_W_LAMP 2000;
BA_REL_ "GenSigTimeoutTime" BU_SG_REL_ CGW SG_ 1427 TREAD_W_LAMP 2000;
BA_REL_ "GenSigTimeoutTime" BU_SG_REL_ CLU SG_ 1427 TREAD_W_LAMP 2000;
BA_REL_ "GenSigTimeoutTime" BU_SG_REL_ CGW SG_ 1427 POS_FL_W_LAMP 2000;
BA_REL_ "GenSigTimeoutTime" BU_SG_REL_ CLU SG_ 1427 POS_FL_W_LAMP 2000;
BA_REL_ "GenSigTimeoutTime" BU_SG_REL_ CGW SG_ 1427 POS_FR_W_LAMP 2000;
BA_REL_ "GenSigTimeoutTime" BU_SG_REL_ CLU SG_ 1427 POS_FR_W_LAMP 2000;
BA_REL_ "GenSigTimeoutTime" BU_SG_REL_ CGW SG_ 1427 POS_RL_W_LAMP 2000;
BA_REL_ "GenSigTimeoutTime" BU_SG_REL_ CLU SG_ 1427 POS_RL_W_LAMP 2000;
BA_REL_ "GenSigTimeoutTime" BU_SG_REL_ CGW SG_ 1427 POS_RR_W_LAMP 2000;
BA_REL_ "GenSigTimeoutTime" BU_SG_REL_ CLU SG_ 1427 POS_RR_W_LAMP 2000;
BA_REL_ "GenSigTimeoutTime" BU_SG_REL_ CLU SG_ 1427 STATUS_TPMS 2000;
BA_REL_ "GenSigTimeoutTime" BU_SG_REL_ CLU SG_ 1427 UNIT 0;
BA_REL_ "GenSigTimeoutTime" BU_SG_REL_ CLU SG_ 1427 PRESSURE_FL 2000;
BA_REL_ "GenSigTimeoutTime" BU_SG_REL_ CLU SG_ 1427 PRESSURE_FR 2000;
BA_REL_ "GenSigTimeoutTime" BU_SG_REL_ CLU SG_ 1427 PRESSURE_RL 2000;
BA_REL_ "GenSigTimeoutTime" BU_SG_REL_ CLU SG_ 1427 PRESSURE_RR 2000;
BA_ "GenMsgSendType" BO_ 1984 8;
BA_ "GenMsgCycleTime" BO_ 1984 0;
BA_ "GenMsgNrOfRepetition" BO_ 1984 3;
BA_ "GenSigSendType" SG_ 1984 CCW 4;
BA_ "GenSigSendType" SG_ 1984 SAS_CID 4;
BA_ "GenSigStartValue" SG_ 1984 SAS_CID 688;
BA_ "GenMsgCycleTime" BO_ 1151 20;
BA_ "GenSigStartValue" SG_ 1151 _4WD_TQC_LIM 64255;
BA_ "GenSigStartValue" SG_ 339 TQI_TCS 255;
BA_ "GenSigStartValue" SG_ 339 TQI_SLW_TCS 255;
BA_ "GenMsgCycleTime" BO_ 916 20;
BA_ "GenMsgCycleTime" BO_ 1287 100;
BA_ "GenSigStartValue" SG_ 356 CR_Esc_StrTqReq 2048;
BA_ "GenMsgCycleTime" BO_ 903 20;
BA_ "GenMsgCycleTime" BO_ 902 20;
VAL_ 1280 CF_SWL_Ind 0 "Warning Lamp on" 1 "Warning Lamp off" 2 "Warning Lamp flash" 3 "Not used" ;
VAL_ 1280 CF_TTL_Ind 0 "Telltale Lamp on" 1 "Telltale Lamp off" 2 "Telltale Lamp flash" 3 "Not used" ;
VAL_ 1425 AFLS_STAT 0 "AFLS is in normal condition" 1 "DBL is defective(점멸/중국only)" 2 "System not Calibration" 3 "System is defective" ;
VAL_ 1345 CF_Gway_IGNSw 0 "Key Off" 1 "Key In" 2 "ACC" 3 "IGN" 4 "Start" ;
VAL_ 1345 CF_Gway_RKECmd 0 "None" 1 "Lock" 2 "Unlock" 3 "Panic" 4 "Panic Stop" 5 "Trunk(Or Tail Gate)" 6 "Reserved" 7 "Reserved" ;
VAL_ 1345 CF_Gway_DrvDrSw 0 "Close" 1 "Open" 3 "B-CAN signal Time-out" ;
VAL_ 1345 CF_Gway_DrvSeatBeltSw 0 "Unbelted" 1 "Belted" 3 "B-CAN signal Time-out" ;
VAL_ 1345 CF_Gway_TrunkTgSw 0 "Trunk Close" 1 "Trunk Open" 3 "B-CAN Time-out" ;
VAL_ 1345 CF_Gway_SMKOption 0 "Non SMK Option" 1 "SMK Option" ;
VAL_ 1345 CF_Gway_HoodSw 0 "Hood Close" 1 "Hood Open" 3 "B-CAN signal Time-out" ;
VAL_ 1345 CF_Gway_TurnSigLh 0 "Off" 1 "On" 3 "B-CAN Time-out" ;
VAL_ 1345 CF_Gway_WiperIntT 0 "Step1(SLOW)" 1 "Step2" 2 "Step3" 3 "Step4" 4 "Step5(FAST)" ;
VAL_ 1345 CF_Gway_RainSnsState 0 "OFF" 1 "Rain Detected" 2 "Low" 3 "High" 4 "Fault 1" 5 "Fault 2" 6 "Fault 3" 7 "Reserved" ;
VAL_ 1345 CF_Gway_HeadLampLow 0 "Off" 1 "On" ;
VAL_ 1345 CF_Gway_HeadLampHigh 0 "Off" 1 "On" ;
VAL_ 1345 CF_Gway_HazardSw 0 "Off" 1 "On" 3 "B-CAN signal Time-out" ;
VAL_ 1345 CF_Gway_AstDrSw 0 "Close" 1 "Open" ;
VAL_ 1345 CF_Gway_LightSwState 0 "Light Sw Off" 1 "Tail Sw On" 2 "HeadLamp Low Sw On" 3 "AutoLight Sw On or DRL Sw On (USA, Non-Autolight)" ;
VAL_ 1345 CF_Gway_TSigRHSw 0 "Off" 1 "On" ;
VAL_ 1345 CF_Gway_TSigLHSw 0 "Off" 1 "On" ;
VAL_ 1345 CF_Gway_DriveTypeOption 0 "LHD" 1 "RHD" ;
VAL_ 1345 CF_Gway_PassiveAccessLock 0 "None" 1 "Lock" 2 "PassiveTrunkLock" ;
VAL_ 1345 CF_Gway_PassiveAccessUnlock 0 "None" 1 "UnLock" 2 "Unlock only DRV Door" 3 "PIC_Key_Reminder" ;
VAL_ 1345 CF_Gway_PassingSW 0 "SW Off" 1 "SW On" ;
VAL_ 1345 CF_Gway_HBAControlMode 0 "HLamp High Control Mode by BCM" 1 "HLamp High Control Mode by HBA" ;
VAL_ 1345 CF_Gway_RainSnsOption 0 "Non Rain Sensor Option" 1 "Rain Sensor Option" ;
VAL_ 1345 C_SunRoofOpenState 0 "close" 1 "open" ;
VAL_ 1345 CF_Gway_TurnSigRh 0 "Off" 1 "On" 3 "B-CAN Time-out" ;
VAL_ 1363 CF_Gway_ExtTailAct 0 "Off" 1 "On" 3 "B-CAN Time-out" ;
VAL_ 1363 CF_Gway_AutoLightValue 0 "Off" 1 "Night" ;
VAL_ 1363 CF_Gway_BrakeFluidSw 0 "Off" 1 "On" ;
VAL_ 1363 CF_Gway_DrvSeatBeltInd 0 "Off" 1 "Blink" 2 "On" ;
VAL_ 1363 CF_Gway_AvTail 0 "Off" 1 "On" ;
VAL_ 1363 CF_Gway_RearFogAct 0 "Off" 1 "On" ;
VAL_ 1363 CF_Gway_RRDrSw 0 "Close" 1 "Open" ;
VAL_ 1363 CF_Gway_RLDrSw 0 "Close" 1 "Open" ;
VAL_ 1363 CF_Gway_IntTailAct 0 "Off" 1 "On" ;
VAL_ 1363 CF_Gway_WiperParkPosition 0 "else" 1 "Parking Position" ;
VAL_ 1363 CF_Gway_ESCLFailWarn 0 "Off" 1 "On" ;
VAL_ 1363 CF_Gway_ESCLNotLockedWarn 0 "Off" 1 "On" ;
VAL_ 1363 CF_Gway_ESCLNotUnlockWarn 0 "Off" 1 "On" ;
VAL_ 1363 CF_Gway_IDoutWarn 0 "Off" 1 "On" ;
VAL_ 1363 CF_Gway_ImmoLp 0 "Off" 1 "On" ;
VAL_ 1363 CF_Gway_VehicleNotPWarn 0 "Off" 1 "On" ;
VAL_ 1363 CF_Gway_DeactivationWarn 0 "Off" 1 "On" ;
VAL_ 1363 CF_Gway_KeyBATDischargeWarn 0 "Off" 1 "On" ;
VAL_ 1363 CF_Gway_SSBWarn 0 "Off" 1 "On" ;
VAL_ 1363 CF_Gway_SMKRKECmd 0 "None" 1 "Lock" 2 "Unlock" 3 "Trunk(or Tail Gate)" 4 "Panic" 5 "Panic Stop" 6 "Two Step Unlock Warning" ;
VAL_ 1363 CF_Gway_SJBDeliveryMode 0 "Before Delivery(Welcome Off)" 1 "After Delivery(Welcome On)" ;
VAL_ 1363 CF_Gway_SMKDispWarn 0 "Off" 1 "Shift_P_Warning" 2 "Key_Bat_Discharge_Warning" 3 "Not_Unlocked_Warning" 4 "Not_Locked_Warning" 5 "Escl_Ecu_Fail_Warning" 6 "Engine_Start_Operation_IND" 7 "Auth_Fail_Warning" 8 "Key_Removal_IND" 9 "SMK_Lamp_Warning" 10 "SSB_Warning" 11 "Auth_Fail_Warning2" 12 "Vehicle_Not_P_Warning" 13 "Stop Lamp Fuse Fail Warning" 14 "Not P_N Warning" ;
VAL_ 1363 CF_Gway_WngBuz 0 "Off" 1 "SeatBelt Warning" 2 "Key Operated Warning" 3 "Parking Brake Warning" 4 "Sun Roof Open Warning" 5 "Key Learning Sound(NoSMKOption)" 6 "ICE Warning" 7 "Rear Fog Warning" ;
VAL_ 1369 CF_Gway_MemoryP1Cmd 0 "None" 1 "P1" ;
VAL_ 1369 CF_Gway_MemoryP2Cmd 0 "None" 1 "P2" ;
VAL_ 1369 CF_Gway_PBackP1Cmd 0 "None" 1 "P1" ;
VAL_ 1369 CF_Gway_PBackP2Cmd 0 "None" 1 "P2" ;
VAL_ 1369 CF_Gway_StrgWhlHeatedState 0 "Off" 1 "On" ;
VAL_ 1369 CF_Gway_PBACKStopCmd 0 "Off" 1 "Stop" ;
VAL_ 1369 CF_Gway_MemoryEnable 0 "Disable" 1 "Enable" ;
VAL_ 1369 CF_Gway_StrgWhlAutoOffState 0 "Manual Off or Fail Off or On or Default Value" 1 "Automatically Off by Timer" ;
VAL_ 1369 CF_Gway_IMSBuzzer 0 "off" 1 "0n" ;
VAL_ 1369 CF_Gway_WiperSwState 0 "Wiper Sw Off" 1 "Wiper Int or Auto Sw On (Refer to CF_Gway_RainSnsOption)" 2 "Wiper Low Sw On" 3 "Wiper High Sw On" ;
VAL_ 1369 CF_Gway_DrvSeatBeltIND 0 "Off" 1 "Blinking" 2 "On" ;
VAL_ 1369 CF_Gway_WPCWarning 0 "Off" 1 "Phone Left Warning" 2 "Charging" 3 "Charging complete" 4 "Reserved" 5 "Reserved" 6 "Reserved" 7 "Invalid" ;
VAL_ 1369 CF_Gway_DedicatedDRLState 0 "Off" 1 "On(Dedicated DRL Option)" ;
VAL_ 1369 CF_Gway_SeatBeltWngBuz 0 "Off" 1 "On" ;
VAL_ 127 C_HLampLowLhOpenSts 0 "Normal" 1 "Open Status" ;
VAL_ 127 C_HLampLowRhOpenSts 0 "Normal" 1 "Open Status" ;
VAL_ 127 C_HLampHighLhOpenSts 0 "Normal" 1 "Open Status" ;
VAL_ 127 C_HLampHighRhOpenSts 0 "Normal" 1 "Open Status" ;
VAL_ 127 C_RearTSIGLhOpenSts 0 "Normal" 1 "Open Status" ;
VAL_ 127 C_RearTSIGRhOpenSts 0 "Normal" 1 "Open Status" ;
VAL_ 127 C_FrontTSIGLhOpenSts 0 "Normal" 1 "Open Status" ;
VAL_ 127 C_FrontTSIGRhOpenSts 0 "Normal" 1 "Open Status" ;
VAL_ 127 C_HLampBifuncLhOpenSts 0 "Normal" 1 "Open Status" ;
VAL_ 127 C_HLampBifuncRhOpenSts 0 "Normal" 1 "Open Status" ;
VAL_ 127 CF_Afls_LedHLStat 0 "LED Headlamp is in nornal condition" 1 "FAN fail" 2 "LED Fail" 3 "Reserved" ;
VAL_ 1294 CF_Gway_BCMWarning 0 "Off" 1 "Power off warning" 2 "Shift p warning" 3 "Reserved" 4 "Reserved" 5 "Reserved" 6 "Reserved" 7 "Reserved" ;
VAL_ 1294 CF_Gway_USADRLSw 0 "Off" 1 "On" ;
VAL_ 1294 CF_Gway_ChaDrSwFrt 0 "Close" 1 "Open" ;
VAL_ 1294 CF_Gway_ChaDrSwRr 0 "Close" 1 "Open" ;
VAL_ 1040 CF_Gway_EscortHLRValue 0 "Default Value" 1 "Escort Off" 2 "Escort On" 3 "Invalid" ;
VAL_ 1040 CF_Gway_TTUnlockRValue 0 "Default" 1 "Ttunlock Off" 2 "Ttunlock On" 3 "Invalid" ;
VAL_ 1040 CF_Gway_ADrLRValue 0 "Default Value" 1 "Off" 2 "Vehicle Speed On(15km)" 3 "Shift Lever On" 4 "Invalid" ;
VAL_ 1040 CF_Gway_ADrURValue 0 "Default" 1 "Off" 2 "Key Out On" 3 "Shift Lever On" 4 "Override" 5 "Invalid" ;
VAL_ 1040 CF_Gway_WlightRValue 0 "Default Value" 1 "Welcome Light Off" 2 "Welcome Light On" 3 "Invalid" ;
VAL_ 1040 CF_Gway_PSMRValue 0 "Default Value" 1 "Off (Disable)" 2 "50mmOn (Enable)" 3 "75mmOn (Enable)" 4 "Reserved" 5 "Reserved" 6 "Reserved" 7 "Invalid" ;
VAL_ 1040 CF_Gway_OTTurnRValue 0 "Default" 1 "One Touch Turn Off" 2 "3 Flashing" 3 "5 Flashing" 4 "7 Flashing" 5 "Invalid" ;
VAL_ 1040 CF_Gway_HAnBRValue 0 "Default Value" 1 "Arm Disarm Buzzer Off" 2 "Arm Disarm Buzzer On" 3 "Invalid" ;
VAL_ 1040 CF_Gway_PasSpkrLvRValue 0 "Default" 1 "Level 1" 2 "Level 2" 3 "Level 3" 4 "Reserved" 5 "Reserved" 6 "Reserved" 7 "Invalid (Error Value)" ;
VAL_ 1040 CF_Gway_WPCRValue 0 "Default" 1 "Off(Disable)" 2 "On(Enable)" 3 "Invalid" ;
VAL_ 1429 CF_Bms_LowtempStatus 0 "Noraml" 1 "Low temperature" ;
VAL_ 1429 CF_Bms_HighTempStatus 0 "Normal" 1 "High Temp Status" ;
VAL_ 1429 CF_Bms_StdCha 0 "None" 1 "Standard Charging" ;
VAL_ 1429 CF_Bms_FstCha 0 "None" 1 "Fast Charging" ;
VAL_ 1429 CF_BMS_ChgFinishedForOBC 0 "Normal" 1 "Charge Finish" ;
VAL_ 1429 CF_Vcu_DriveMode 0 "Eco mode" 1 "Normal mode" 2 "Sport mode" 3 "Invalid" ;
VAL_ 1430 CF_Vcu_SpdLmt 0 "None" 1 "Limited" ;
VAL_ 1430 CF_Bms_ServiceLamp 0 "Off" 1 "Service Lamp On" ;
VAL_ 1430 CF_Ldc_AuxBatWrnLamp 0 "Aux Bat warning lamp off" 1 "Aux Bat warning lamp request" ;
VAL_ 1430 CF_Ldc_AuxBatWrnAlarm 0 "Aux Bat warning alarm off" 1 "Aux Bat warning alarm request" ;
VAL_ 1430 CF_Ldc_Srvlamp_Rqst 0 "Normal status" 1 "Service lamp request" ;
VAL_ 1430 CF_Aaf_WrnLamp 0 "Warning Lamp/Message Off" 1 "Warning Lamp/Message On" ;
VAL_ 881 CF_Brk_RBSWLamp 0 "RBS Warning Lamp OFF" 1 "RBS Warning Lamp ON" ;
VAL_ 881 CF_Vcu_Rdy 0 "None" 1 "VCU Control Board Ready" ;
VAL_ 881 CF_Vcu_EvRdyClu 0 "Ready Lamp Off" 1 "Ready Lamp On" ;
VAL_ 881 CF_Vcu_EvRdy 0 "None" 1 "EV Drivable" ;
VAL_ 881 CF_Vcu_EcoMdOff 0 "Normal" 1 "Eco Off Mode" ;
VAL_ 881 CF_Vcu_SldAct 0 "Speed Limiter Lamp Off" 1 "Speed Limiter Lamp On" ;
VAL_ 881 CF_Vcu_SccEna 0 "SCC Impossible" 1 "SCC Possible" ;
VAL_ 882 CF_Vcu_GarSelDisp 0 "P" 1 "B" 2 "Not used" 3 "Not used" 4 "Not used" 5 "D" 6 "N" 7 "R" 8 "Not used" 9 "Not Display at Cluster" 10 "reserved" 11 "reserved" 12 "reserved" 13 "reserved" 14 "Intermediate Position" 15 "Fault" ;
VAL_ 882 CF_Vcu_PddlSftStep 0 "None" 1 "1st" 2 "2nd" 3 "3rd" 4 "4th" 5 "5th" 6 "6th" 7 "reserved" 8 "reserved" 9 "reserved" 10 "reserved" 11 "reserved" 12 "reserved" 13 "reserved" 14 "reserved" 15 "Fault" ;
VAL_ 882 CF_Vcu_EstApsSel 0 "VCU Real APS use" 1 "VCU Estimated APS use" ;
VAL_ 882 CF_Vcu_ServiceMod 0 "Normal mode" 1 "2WD Test mode" ;
VAL_ 882 CF_Mcu_Mg1SvcLmp 0 "ServiceLamp Off" 1 "ServiceLamp On" ;
VAL_ 882 CF_Mcu_EwpCoolantCluDisp 0 "Normal" 1 "Insufficient" ;
VAL_ 882 CF_Lvr_Wrn 0 "Warning OFF" 1 "Gear Button Failure" 2 "P Pelease Button Failure" 6 "Button Stuck Failure" 3 "Reserved" 4 "Reserved" 5 "Reserved" 7 "Reserved" ;
VAL_ 882 CF_Scu_INH_OH 0 "Normal" 1 "Reject" ;
VAL_ 1355 CF_Vcu_CIL_Status 0 "default" 1 "ready" 2 "set" 3 "reserved" 4 "reserved" 5 "reserved" 6 "reserved" 7 "Invalid" ;
VAL_ 1355 CF_Vcu_CIL_Warn 0 "Default" 1 "On" 2 "Off" 3 "Invalid" ;
VAL_ 1355 CF_Vcu_CIL_Off 0 "Default" 1 "On" 2 "Off" 3 "Invalid" ;
VAL_ 1355 CF_Vcu_CIL_Event 0 "Default" 1 "Right Turn" 2 "Left Turn" 3 "Right side of Y branch" 4 "Left side of Y branch" 5 "U Turn" 6 "Rotary Entry" 7 "Highway Exit-Right" 8 "Highway Exit-Left" 9 "Highway Entry-Right" 10 "Highway Entry-Left" 11 "Destination" 12 "Tollgate" 13 "Over Speed" 14 "Speed Limit" 15 "Invalid" ;
VAL_ 1355 CF_VCU_AuxBattChgUsmSts 0 "Default (USM 비활성)" 1 "Disable (Off)" 2 "Enable (On)" 3 "Invalid (USM 비활성)" ;
VAL_ 1355 CF_Vcu_CIL_Ctrl 0 "Default" 1 "Long distance" 2 "Middle distance" 3 "Short distance" 4 "Reserved" 5 "Reserved" 6 "Reserved" 7 "Invalid" ;
VAL_ 1355 CF_Vcu_SbwWarnMsg 0 "Off" 1 "Warning Message 1 - SCU/Parking system failure" 2 "Warning Message 2 - Unavailable to shift gear" 3 "Warning Message 3 - Brake on for gear shift" 4 "Warning Message 4 - Unavailable to park" 5 "Warning Message 5 - Auto-parked" 6 "Warning Message 6 - Unavailable to release park" 7 "Reserved" ;
VAL_ 1355 CF_Vcu_SbwWarnSnd 0 "Warning sound off" 1 "Warning sound on" ;
VAL_ 1355 CF_Vcu_AvnDteCalc 0 "Display DTE value" 1 "Display 'Recalculating'" ;
VAL_ 1355 CF_Bms_ChgSts 0 "None" 1 "Charging" ;
VAL_ 1355 CR_Vcu_EDAS_FueSav 0 "0x0~0x3E8:0~10.00" 1000 "0x0~0x3E8:0~10.00" 1001 "Reserved" 1002 "Reserved" 1003 "Reserved" 1004 "Reserved" 1005 "Reserved" 1006 "Reserved" 1007 "Reserved" 1008 "Reserved" 1009 "Reserved" 1010 "Reserved" 1011 "Reserved" 1012 "Reserved" 1013 "Reserved" 1014 "Reserved" 1015 "Reserved" 1016 "Reserved" 1017 "Reserved" 1018 "Reserved" 1019 "Reserved" 1020 "Reserved" 1021 "Reserved" 1022 "Reserved" 1023 "Invalid" ;
VAL_ 1355 CF_Vcu_EDAS_FueSavSet 0 "Default" 1 "No display" 2 "Display" 3 "Invalid" ;
VAL_ 1355 CF_Ldc_AuxBatChg_State 0 "Default" 1 "Aux Bat Charge Activated" 2 "Aux Bat Charge Completed" 3 "Aux Bat Charge Inhibited" ;
VAL_ 1355 CF_Vcu_SbwWarnMsg2 0 "Off" 1 "Warning Message 1 - SCU/Parking system failure" ;
VAL_ 1355 CF_Vcu_BatSav_Off 0 "Default" 1 "On" 2 "Off" 3 "Invalid" ;
VAL_ 1355 CF_Vcu_BatSav_Status 0 "Default" 1 "Active" 2 "Finished" 3 "Warning" 4 "12V Power Off" 5 "reserved" 6 "reserved" 7 "Invalid" ;
VAL_ 1291 CF_Vcu_ResvAirCtrInfo 0 "Reservation Airconditioner Control Not Set" 1 "Reservation Set" ;
VAL_ 1291 CF_Datc_ServiceLamp 0 "Service Lamp(for FATC) Off" 1 "Service Lamp(for FATC) On" ;
VAL_ 1291 CF_Bms_PShiftForCharging 0 "Normal" 1 "P Shift For Charging" ;
VAL_ 1291 CF_OBC_AC_CONNECT_FLAG 0 "AC Plug Disconnected" 1 "AC Plug Connected" ;
VAL_ 1291 CF_EVSE_FAULT_FLAG 0 "Normal" 1 "Fault" ;
VAL_ 1291 CF_OBC_MILReq 0 "off" 1 "on" ;
VAL_ 1291 CF_OBC_SERVICE_LAMP_Req 0 "OFF" 1 "ON" ;
VAL_ 1291 CR_Datc_OutTemp_C 0 "Blnak Display" 1 "Blank Display" 254 "Sensor Fail (--Display)" 255 "Invalid" ;
VAL_ 1291 CR_Datc_OutTempF 0 "Blank Display" 1 "Blank Display" 254 "Sensor Fail ( - - Display )" 255 "Invalid" ;
VAL_ 1291 DATC_TempUnit 0 "Centigrade" 1 "Fahrenheit" 2 "Not Used" 3 "Invalid" ;
VAL_ 1291 CF_Bms_FstEvseFltAlram 0 "Normal" 1 "Alraming By QCS Fault" ;
VAL_ 1291 CF_Vcu_ResvInfo 0 "Reservation not set" 1 "Reservation set" ;
VAL_ 2015 FRM_FORMAT 2 "Single frame and should analyze next two data of this message" ;
VAL_ 2015 SID 40 "Disable transmission of normal CAN messages. (Stop normal CAN communication)" 41 "Enable transmission of normal CAN messages. (Resume normal CAN communication)" ;
VAL_ 2015 REQ_RESPONSE 0 "Reserved" 1 "Response required" 2 "No response required" ;
VAL_ 1470 HU_NaviStatus 0 "Booting" 1 "Normal Operation" 2 "No SD Card" 3 "Invalid" ;
VAL_ 1470 HU_NaviCamSettingStatus 0 "Navi Camera Alert Setting Status" 1 "Navi Camera Alert Setting Status" 2 "Navi Camera Alert Setting Status" 3 "Navi Camera Alert Setting Status" 4 "Navi Camera Alert Setting Status" 5 "Navi Camera Alert Setting Status" 6 "Navi Camera Alert Setting Status" 7 "Navi Camera Alert Setting Status" 8 "Navi Camera Alert Setting Status" 9 "Navi Camera Alert Setting Status" 10 "Navi Camera Alert Setting Status" 11 "Navi Camera Alert Setting Status" 12 "Navi Camera Alert Setting Status" 13 "Navi Camera Alert Setting Status" 14 "Navi Camera Alert Setting Status" 15 "Navi Camera Alert Setting Status" 16 "Navi Camera Alert Setting Status" 17 "Navi Camera Alert Setting Status" 18 "Navi Camera Alert Setting Status" 19 "Navi Camera Alert Setting Status" 20 "Navi Camera Alert Setting Status" 21 "Navi Camera Alert Setting Status" 22 "Navi Camera Alert Setting Status" 23 "Navi Camera Alert Setting Status" 24 "Navi Camera Alert Setting Status" 25 "Navi Camera Alert Setting Status" 26 "Navi Camera Alert Setting Status" 27 "Navi Camera Alert Setting Status" 28 "Navi Camera Alert Setting Status" 29 "Navi Camera Alert Setting Status" 30 "Navi Camera Alert Setting Status" 31 "Navi Camera Alert Setting Status" 32 "0x20~0xFE:Reserved" 254 "0x20~0xFE:Reserved" 255 "Invalid" ;
VAL_ 1407 HU_DistributeInfo 255 "Invalid" 1 "KOREA" 2 "NORTH AMERICA" 3 "CANADA" 4 "EAST EUROPE" 5 "WEST EUROPE" 6 "CHINA" 7 "INDIA" 8 "AUSTRALIA" 9 "MIDDLE EAST" 10 "AFRICA" 11 "SOUTH AMERICA" 12 "RESERVED" 13 "RESERVED" 14 "GENERAL" 15 "RESERVED" ;
VAL_ 1407 HU_AdasSupport 0 "Not Support" 1 "ADAS Support(General Map)" 2 "ADAS Support(Precise Map)" 3 "Reserved" 4 "Reserved" 5 "Reserved" 6 "Reserved" 7 "Invalid" ;
VAL_ 1348 HU_AliveStatus 0 "Not Ready" 1 "On Mode" 2 "Head Unit Update Mode" 3 "Invalid" ;
VAL_ 545 META_MessageType 0 "Reserved" 1 "Position" 2 "Segment" 3 "Stub" 4 "Profile Short" 5 "Profile Long" 6 "Meta Data" 7 "Invalid" ;
VAL_ 545 META_MapProvider 0 "Unknown" 1 "NAVTEQ" 2 "TeleAtlas" 3 "Zenrin" 4 "HMNS" 5 "Reserved" 6 "Reserved" 7 "Invalid" ;
VAL_ 545 META_CountryCode 0 "Unknown" 1 "0x1~0x3FE:ISO 3166-1 numeric values" 1022 "0x1~0x3FE:ISO 3166-1 numeric values" 1023 "Invalid" ;
VAL_ 545 META_CyclicCounter 0 "Cyclic Counter" 1 "Cyclic Counter" 2 "Cyclic Counter" 3 "Cyclic Counter" ;
VAL_ 545 META_MajorProtocolVersion 0 "Major version value" 1 "Major version value" 2 "Major version value" 3 "Major version value" ;
VAL_ 545 META_MinorProtocolSubVer 0 "Minor sub-version value" 1 "Minor sub-version value" 2 "Minor sub-version value" 3 "Minor sub-version value" 4 "Minor sub-version value" 5 "Minor sub-version value" 6 "Minor sub-version value" 7 "Minor sub-version value" ;
VAL_ 545 META_HardwareVersion 0 "Unknown" 1 "0x1~0x1FE:Hardware version value" 510 "0x1~0x1FE:Hardware version value" 511 "Invalid" ;
VAL_ 545 META_DrivingSide 0 "Driving Side Left" 1 "Driving Side Right" ;
VAL_ 545 META_RegionCode 0 "Unknown" 1 "0x1~0x7FFE:ISO 3166-2 values" 32766 "0x1~0x7FFE:ISO 3166-2 values" 32767 "Invalid" ;
VAL_ 545 META_MapVersionQuarter 0 "Q1" 1 "Q2" 2 "Q3" 3 "Q4" ;
VAL_ 545 META_MapVersionYear 0 "Year" 1 "Year" 2 "Year" 3 "Year" 4 "Year" 5 "Year" 6 "Year" 7 "Year" 8 "Year" 9 "Year" 10 "Year" 11 "Year" 12 "Year" 13 "Year" 14 "Year" 15 "Year" 16 "Year" 17 "Year" 18 "Year" 19 "Year" 20 "Year" 21 "Year" 22 "Year" 23 "Year" 24 "Year" 25 "Year" 26 "Year" 27 "Year" 28 "Year" 29 "Year" 30 "Year" 31 "Year" 32 "Year" 33 "Year" 34 "Year" 35 "Year" 36 "Year" 37 "Year" 38 "Year" 39 "Year" 40 "Year" 41 "Year" 42 "Year" 43 "Year" 44 "Year" 45 "Year" 46 "Year" 47 "Year" 48 "Year" 49 "Year" 50 "Year" 51 "Year" 52 "Year" 53 "Year" 54 "Year" 55 "Year" 56 "Year" 57 "Year" 58 "Year" 59 "Year" 60 "Year" 61 "Year" 62 "Year" 63 "Invalid" ;
VAL_ 545 META_SpeedUnit 0 "Kilometers per hour" 1 "Mile per hour" ;
VAL_ 545 META_MinorProtocolVersion 0 "Minor version value" 1 "Minor version value" 2 "Minor version value" 3 "Minor version value" 4 "Minor version value" 5 "Minor version value" 6 "Minor version value" 7 "Minor version value" 8 "Minor version value" 9 "Minor version value" 10 "Minor version value" 11 "Minor version value" 12 "Minor version value" 13 "Minor version value" 14 "Minor version value" 15 "Minor version value" ;
VAL_ 546 POS_MessageType 0 "Reserved" 1 "Position" 2 "Segment" 3 "Stub" 4 "Profile Short" 5 "Profile Long" 6 "Meta Data" 7 "Invalid" ;
VAL_ 546 POS_Offset 0 "0x0~0x1FFE:Distance" 8190 "0x0~0x1FFE:Distance" 8191 "Invalid" ;
VAL_ 546 POS_CyclicCounter 0 "Cyclic Counter" 1 "Cyclic Counter" 2 "Cyclic Counter" 3 "Cyclic Counter" ;
VAL_ 546 POS_PathIndex 0 "Unknown" 1 "Reserved" 2 "Reserved" 3 "Reserved" 4 "Reserved" 5 "Reserved" 6 "Reserved" 7 "Reserved" 8 "General Path Index" 9 "General Path Index" 10 "General Path Index" 11 "General Path Index" 12 "General Path Index" 13 "General Path Index" 14 "General Path Index" 15 "General Path Index" 16 "General Path Index" 17 "General Path Index" 18 "General Path Index" 19 "General Path Index" 20 "General Path Index" 21 "General Path Index" 22 "General Path Index" 23 "General Path Index" 24 "General Path Index" 25 "General Path Index" 26 "General Path Index" 27 "General Path Index" 28 "General Path Index" 29 "General Path Index" 30 "General Path Index" 31 "General Path Index" 32 "General Path Index" 33 "General Path Index" 34 "General Path Index" 35 "General Path Index" 36 "General Path Index" 37 "General Path Index" 38 "General Path Index" 39 "General Path Index" 40 "General Path Index" 41 "General Path Index" 42 "General Path Index" 43 "General Path Index" 44 "General Path Index" 45 "General Path Index" 46 "General Path Index" 47 "General Path Index" 48 "General Path Index" 49 "General Path Index" 50 "General Path Index" 51 "General Path Index" 52 "General Path Index" 53 "General Path Index" 54 "General Path Index" 55 "General Path Index" 56 "General Path Index" 57 "General Path Index" 58 "General Path Index" 59 "General Path Index" 60 "General Path Index" 61 "General Path Index" 62 "General Path Index" 63 "General Path Index" ;
VAL_ 546 POS_PositionIndex 0 "Most probable position" 1 "Second candidate" 2 "Third candidate" 3 "Invalid" ;
VAL_ 546 POS_PositionProbability 0 "Unknown" 1 "Position Probability" 2 "Position Probability" 3 "Position Probability" 4 "Position Probability" 5 "Position Probability" 6 "Position Probability" 7 "Position Probability" 8 "Position Probability" 9 "Position Probability" 10 "Position Probability" 11 "Position Probability" 12 "Position Probability" 13 "Position Probability" 14 "Position Probability" 15 "Position Probability" 16 "Position Probability" 17 "Position Probability" 18 "Position Probability" 19 "Position Probability" 20 "Position Probability" 21 "Position Probability" 22 "Position Probability" 23 "Position Probability" 24 "Position Probability" 25 "Position Probability" 26 "Position Probability" 27 "Position Probability" 28 "Position Probability" 29 "Position Probability" 30 "Position Probability" 31 "Invalid" ;
VAL_ 546 POS_PositionAge 0 "Unknown" 1 "0x1~0xFE:Position Age" 254 "0x1~0xFE:Position Age" 511 "Invalid" ;
VAL_ 546 POS_PositionConfidence 0 "Highest confidence" 1 "Position confidence" 2 "Position confidence" 3 "Position confidence" 4 "Position confidence" 5 "Position confidence" 6 "lowest confidence" 7 "Invalid" ;
VAL_ 546 POS_CurrentLane 0 "Unknown" 1 "Energency lane" 2 "Single lane road" 3 "Left most lane" 4 "Right most lane" 5 "One of middle over three lanes" 6 "Reserved" 7 "Invalid" ;
VAL_ 546 POS_RangeAvgSpeed 0 "0x0~0xFE:Range Camera Average Speed" 254 "0x0~0xFE:Range Camera Average Speed" 255 "0xFF~0x1FD:Reserved" 509 "0xFF~0x1FD:Reserved" 510 "Timeout" 511 "Invalid" ;
VAL_ 546 POS_RelativeHeading 0 "In real north direction" 1 "1.417 degrees right" 2 "0x2~0x7D:Right from real north direction" 125 "0x2~0x7D:Right from real north direction" 126 "178.583 degrees right" 127 "Opposite direction" 128 "178.583 degrees left" 129 "0x81~0xFC:Left from real north direction" 252 "0x81~0xFC:Left from real north direction" 253 "1.417 degrees left" 254 "Unknown" 255 "Invalid" ;
VAL_ 547 PROLONG_Value 0 "0x0~0xFFFFFFFE:Profile value at Offset" 2147483647 "0x0~0xFFFFFFFE:Profile value at Offset" 2147483647 "Invalid" ;
VAL_ 547 PROLONG_MessageType 0 "Reserved" 1 "Position" 2 "Segment" 3 "Stub" 4 "Profile Short" 5 "Profile Long" 6 "Meta Data" 7 "Invalid" ;
VAL_ 547 PROLONG_Offset 0 "0x0~0x1FFE:Distance" 8190 "0x0~0x1FFE:Distance" 8191 "Invalid" ;
VAL_ 547 PROLONG_CyclicCounter 0 "Cyclic Counter" 1 "Cyclic Counter" 2 "Cyclic Counter" 3 "Cyclic Counter" ;
VAL_ 547 PROLONG_PathIndex 0 "Unknown" 1 "Reserved" 2 "Reserved" 3 "Reserved" 4 "Reserved" 5 "Reserved" 6 "Reserved" 7 "Reserved" 8 "General Path Index" 9 "General Path Index" 10 "General Path Index" 11 "General Path Index" 12 "General Path Index" 13 "General Path Index" 14 "General Path Index" 15 "General Path Index" 16 "General Path Index" 17 "General Path Index" 18 "General Path Index" 19 "General Path Index" 20 "General Path Index" 21 "General Path Index" 22 "General Path Index" 23 "General Path Index" 24 "General Path Index" 25 "General Path Index" 26 "General Path Index" 27 "General Path Index" 28 "General Path Index" 29 "General Path Index" 30 "General Path Index" 31 "General Path Index" 32 "General Path Index" 33 "General Path Index" 34 "General Path Index" 35 "General Path Index" 36 "General Path Index" 37 "General Path Index" 38 "General Path Index" 39 "General Path Index" 40 "General Path Index" 41 "General Path Index" 42 "General Path Index" 43 "General Path Index" 44 "General Path Index" 45 "General Path Index" 46 "General Path Index" 47 "General Path Index" 48 "General Path Index" 49 "General Path Index" 50 "General Path Index" 51 "General Path Index" 52 "General Path Index" 53 "General Path Index" 54 "General Path Index" 55 "General Path Index" 56 "General Path Index" 57 "General Path Index" 58 "General Path Index" 59 "General Path Index" 60 "General Path Index" 61 "General Path Index" 62 "General Path Index" 63 "General Path Index" ;
VAL_ 547 PROLONG_ProfileType 0 "Invalid" 1 "Longitude" 2 "Latitude" 3 "Altitude" 4 "Control Point Longitude(Bezier)" 5 "Control Point Latitude(Bezier)" 6 "Control Point Altitude(Bezier)" 7 "Link Identifier" 8 "Traffic Sign" 9 "Reserved for standard type" 10 "Reserved for standard type" 11 "Reserved for standard type" 12 "Reserved for standard type" 13 "Reserved for standard type" 14 "Reserved for standard type" 15 "Reserved for standard type" 16 "Alert Information Spot" 17 "Reserved for system specific types" 18 "Reserved for system specific types" 19 "Reserved for system specific types" 20 "Reserved for system specific types" 21 "Reserved for system specific types" 22 "Reserved for system specific types" 23 "Reserved for system specific types" 24 "Reserved for system specific types" 25 "Reserved for system specific types" 26 "Reserved for system specific types" 27 "Reserved for system specific types" 28 "Reserved for system specific types" 29 "Reserved for system specific types" 30 "Reserved for system specific types" 31 "Reserved for system specific types" ;
VAL_ 547 PROLONG_CountrolPoint 0 "False" 1 "True" ;
VAL_ 547 PROLONG_Retransmission 0 "False" 1 "True" ;
VAL_ 547 PROLONG_Update 0 "False" 1 "True" ;
VAL_ 548 PROSHORT_MessageType 0 "Reserved" 1 "Position" 2 "Segment" 3 "Stub" 4 "Profile Short" 5 "Profile Long" 6 "Meta Data" 7 "Invalid" ;
VAL_ 548 PROSHORT_Offset 0 "0x0~0x1FFE:Distance" 8190 "0x0~0x1FFE:Distance" 8191 "Invalid" ;
VAL_ 548 PROSHORT_CyclicCounter 0 "Cyclic Counter" 1 "Cyclic Counter" 2 "Cyclic Counter" 3 "Cyclic Counter" ;
VAL_ 548 PROSHORT_PathIndex 0 "Unknown" 1 "Reserved" 2 "Reserved" 3 "Reserved" 4 "Reserved" 5 "Reserved" 6 "Reserved" 7 "Reserved" 8 "General Path Index" 9 "General Path Index" 10 "General Path Index" 11 "General Path Index" 12 "General Path Index" 13 "General Path Index" 14 "General Path Index" 15 "General Path Index" 16 "General Path Index" 17 "General Path Index" 18 "General Path Index" 19 "General Path Index" 20 "General Path Index" 21 "General Path Index" 22 "General Path Index" 23 "General Path Index" 24 "General Path Index" 25 "General Path Index" 26 "General Path Index" 27 "General Path Index" 28 "General Path Index" 29 "General Path Index" 30 "General Path Index" 31 "General Path Index" 32 "General Path Index" 33 "General Path Index" 34 "General Path Index" 35 "General Path Index" 36 "General Path Index" 37 "General Path Index" 38 "General Path Index" 39 "General Path Index" 40 "General Path Index" 41 "General Path Index" 42 "General Path Index" 43 "General Path Index" 44 "General Path Index" 45 "General Path Index" 46 "General Path Index" 47 "General Path Index" 48 "General Path Index" 49 "General Path Index" 50 "General Path Index" 51 "General Path Index" 52 "General Path Index" 53 "General Path Index" 54 "General Path Index" 55 "General Path Index" 56 "General Path Index" 57 "General Path Index" 58 "General Path Index" 59 "General Path Index" 60 "General Path Index" 61 "General Path Index" 62 "General Path Index" 63 "General Path Index" ;
VAL_ 548 PROSHORT_Accuracy 0 "High Accuracy" 1 "Middle Accuracy" 2 "Low Accuracy" 3 "Unknown" ;
VAL_ 548 PROSHORT_Distance 0 "0x0~0x3FE:Distance" 1022 "0x0~0x3FE:Distance" 1023 "Invalid" ;
VAL_ 548 PROSHORT_Value0 0 "0x0~0x3FE:Profile Vaue at Offset" 1022 "0x0~0x3FE:Profile Vaue at Offset" 1023 "Invalid" ;
VAL_ 548 PROSHORT_Value1 0 "0x0~0x3FE:Profile value at Offset+Distance1" 1022 "0x0~0x3FE:Profile value at Offset+Distance1" 1023 "Invalid" ;
VAL_ 548 PROSHORT_ProfileType 0 "Invalid" 1 "Curvature" 2 "Route Number types" 3 "Slope(step)" 4 "Slope(Linear)" 5 "Road Accessibility" 6 "Road condition" 7 "Variable Speed Sign Position" 8 "Heading Change" 9 "Reserved for standard type" 10 "Reserved for standard type" 11 "Reserved for standard type" 12 "Reserved for standard type" 13 "Reserved for standard type" 14 "Reserved for standard type" 15 "Reserved for standard type" 16 "Alert Information Section" 17 "Curvature Average Speed" 18 "Reserved for system specific types" 19 "Reserved for system specific types" 20 "Reserved for system specific types" 21 "Reserved for system specific types" 22 "Reserved for system specific types" 23 "Reserved for system specific types" 24 "Reserved for system specific types" 25 "Reserved for system specific types" 26 "Reserved for system specific types" 27 "Reserved for system specific types" 28 "Reserved for system specific types" 29 "Reserved for system specific types" 30 "Reserved for system specific types" 31 "Reserved for system specific types" ;
VAL_ 548 PROSHORT_ControlPoint 0 "False" 1 "True" ;
VAL_ 548 PROSHORT_Retransmission 0 "False" 1 "True" ;
VAL_ 548 PROSHORT_Update 0 "False" 1 "True" ;
VAL_ 549 SEG_MessageType 0 "Reserved" 1 "Position" 2 "Segment" 3 "Stub" 4 "Profile Short" 5 "Profile Long" 6 "Meta Data" 7 "Invalid" ;
VAL_ 549 SEG_Offset 0 "0x0~0x1FFE:Distance" 8190 "0x0~0x1FFE:Distance" 8191 "Invalid" ;
VAL_ 549 SEG_CyclicCounter 0 "Cyclic Counter" 1 "Cyclic Counter" 2 "Cyclic Counter" 3 "Cyclic Counter" ;
VAL_ 549 SEG_PathIndex 0 "Unknown" 1 "Reserved" 2 "Reserved" 3 "Reserved" 4 "Reserved" 5 "Reserved" 6 "Reserved" 7 "Reserved" 8 "General Path Index" 9 "General Path Index" 10 "General Path Index" 11 "General Path Index" 12 "General Path Index" 13 "General Path Index" 14 "General Path Index" 15 "General Path Index" 16 "General Path Index" 17 "General Path Index" 18 "General Path Index" 19 "General Path Index" 20 "General Path Index" 21 "General Path Index" 22 "General Path Index" 23 "General Path Index" 24 "General Path Index" 25 "General Path Index" 26 "General Path Index" 27 "General Path Index" 28 "General Path Index" 29 "General Path Index" 30 "General Path Index" 31 "General Path Index" 32 "General Path Index" 33 "General Path Index" 34 "General Path Index" 35 "General Path Index" 36 "General Path Index" 37 "General Path Index" 38 "General Path Index" 39 "General Path Index" 40 "General Path Index" 41 "General Path Index" 42 "General Path Index" 43 "General Path Index" 44 "General Path Index" 45 "General Path Index" 46 "General Path Index" 47 "General Path Index" 48 "General Path Index" 49 "General Path Index" 50 "General Path Index" 51 "General Path Index" 52 "General Path Index" 53 "General Path Index" 54 "General Path Index" 55 "General Path Index" 56 "General Path Index" 57 "General Path Index" 58 "General Path Index" 59 "General Path Index" 60 "General Path Index" 61 "General Path Index" 62 "General Path Index" 63 "General Path Index" ;
VAL_ 549 SEG_Tunnel 0 "Not part of a tunnel" 1 "Part of a tunnel" 2 "Unknown" 3 "Invalid" ;
VAL_ 549 SEG_Bridge 0 "Not part of a bridge" 1 "Part of a bridge" 2 "Unknown" 3 "Invalid" ;
VAL_ 549 SEG_BuiltUpArea 0 "Not part of built-up area" 1 "Part of built-up area" 2 "Unknown" 3 "Invalid" ;
VAL_ 549 SEG_Retransmission 0 "False" 1 "True" ;
VAL_ 549 SEG_Update 0 "False" 1 "True" ;
VAL_ 549 SEG_RelativeProbability 0 "Driving not allowed" 1 "Relative probability" 2 "Relative probability" 3 "Relative probability" 4 "Relative probability" 5 "Relative probability" 6 "Relative probability" 7 "Relative probability" 8 "Relative probability" 9 "Relative probability" 10 "Relative probability" 11 "Relative probability" 12 "Relative probability" 13 "Relative probability" 14 "Relative probability" 15 "Relative probability" 16 "Relative probability" 17 "Relative probability" 18 "Relative probability" 19 "Relative probability" 20 "Relative probability" 21 "Relative probability" 22 "Relative probability" 23 "Relative probability" 24 "Relative probability" 25 "Relative probability" 26 "Relative probability" 27 "Relative probability" 28 "Relative probability" 29 "Relative probability" 30 "Relative probability" 31 "Invalid" ;
VAL_ 549 SEG_FunctionalRoadClass 0 "Unknown" 1 "Freeway" 2 "Arterial(City freeway)" 3 "County" 4 "Collector" 5 "Local" 6 "Etc(ferry unpaved)" 7 "Invalid" ;
VAL_ 549 SEG_CalculatedRoute 0 "Not Calculated Route(MPP)" 1 "Part of Calculated Route" 2 "Off Route or Recalculating" 3 "Invalid" ;
VAL_ 549 SEG_ComplexIntersection 0 "Not part of complex intersection" 1 "Part of of complex intersection" 2 "Unknown" 3 "Invalid" ;
VAL_ 549 SEG_FormOfWay 0 "Unkonwn" 1 "Main road(nondisjunction)" 2 "Main road(disjunction)" 3 "JC" 4 "Plural Junction M" 5 "IC" 6 "Reserved" 7 "Service Area" 8 "Reserved" 9 "Roundabout" 10 "P turn" 11 "U trun" 12 "Pedestrian" 13 "Frontage Road" 14 "Intersection internal" 15 "Invalid" ;
VAL_ 549 SEG_SpeedLimit 0 "Unknown" 1 "Under 5kph(mph)" 2 "7kph(mph)" 3 "10kph(mph)" 4 "15kph(mph)" 5 "20kph(mph)" 6 "25kph(mph)" 7 "30kph(mph)" 8 "35kph(mph)" 9 "40kph(mph)" 10 "45kph(mph)" 11 "50kph(mph)" 12 "55kph(mph)" 13 "60kph(mph)" 14 "65kph(mph)" 15 "70kph(mph)" 16 "75kph(mph)" 17 "80kph(mph)" 18 "85kph(mph)" 19 "90kph(mph)" 20 "95kph(mph)" 21 "100kph(mph)" 22 "105kph(mph)" 23 "110kph(mph)" 24 "115kph(mph)" 25 "120kph(mph)" 26 "130kph(mph)" 27 "140kph(mph)" 28 "150kph(mph)" 29 "160kph(mph)" 30 "Unlimited" 31 "Invalid" ;
VAL_ 549 SEG_SpeedLimitType 0 "Implicit(default)" 1 "Explicit(on traffic sign)" 2 "Explicit(by night)" 3 "Explicit(by day)" 4 "Explicit(time of day)" 5 "Explicit(rain)" 6 "Explicit(snow)" 7 "Unknown" ;
VAL_ 549 SEG_DividedRoad 0 "Not part of a divided road" 1 "Part of a divided road" 2 "Unknown" 3 "Invalid" ;
VAL_ 549 SEG_OppositeLanes 0 "Unknown" 1 "one lane only" 2 "2 or more lanes" 3 "Invalid" ;
VAL_ 549 SEG_DirectionLanes 0 "Unknown" 1 "Lane count" 2 "Lane count" 3 "Lane count" 4 "Lane count" 5 "Lane count" 6 "6 or more lanes" 7 "Invalid" ;
VAL_ 550 STUB_MessageType 0 "Reserved" 1 "Position" 2 "Segment" 3 "Stub" 4 "Profile Short" 5 "Profile Long" 6 "Meta Data" 7 "Invalid" ;
VAL_ 550 STUB_Offset 0 "0x0~0x1FFE:Distance" 8190 "0x0~0x1FFE:Distance" 8191 "Invalid" ;
VAL_ 550 STUB_CyclicCounter 0 "Cyclic Counter" 1 "Cyclic Counter" 2 "Cyclic Counter" 3 "Cyclic Counter" ;
VAL_ 550 STUB_PathIndex 0 "first path in the Horizon" 1 "Reserved" 2 "Reserved" 3 "Reserved" 4 "Reserved" 5 "Reserved" 6 "Reserved" 7 "Reserved" 8 "General Path Index" 9 "General Path Index" 10 "General Path Index" 11 "General Path Index" 12 "General Path Index" 13 "General Path Index" 14 "General Path Index" 15 "General Path Index" 16 "General Path Index" 17 "General Path Index" 18 "General Path Index" 19 "General Path Index" 20 "General Path Index" 21 "General Path Index" 22 "General Path Index" 23 "General Path Index" 24 "General Path Index" 25 "General Path Index" 26 "General Path Index" 27 "General Path Index" 28 "General Path Index" 29 "General Path Index" 30 "General Path Index" 31 "General Path Index" 32 "General Path Index" 33 "General Path Index" 34 "General Path Index" 35 "General Path Index" 36 "General Path Index" 37 "General Path Index" 38 "General Path Index" 39 "General Path Index" 40 "General Path Index" 41 "General Path Index" 42 "General Path Index" 43 "General Path Index" 44 "General Path Index" 45 "General Path Index" 46 "General Path Index" 47 "General Path Index" 48 "General Path Index" 49 "General Path Index" 50 "General Path Index" 51 "General Path Index" 52 "General Path Index" 53 "General Path Index" 54 "General Path Index" 55 "General Path Index" 56 "General Path Index" 57 "General Path Index" 58 "General Path Index" 59 "General Path Index" 60 "General Path Index" 61 "General Path Index" 62 "General Path Index" 63 "General Path Index" ;
VAL_ 550 STUB_SubPathIndex 0 "Unknown" 1 "Reserved" 2 "Reserved" 3 "Reserved" 4 "Reserved" 5 "Reserved" 6 "Reserved" 7 "Reserved" 8 "General Path Index" 9 "General Path Index" 10 "General Path Index" 11 "General Path Index" 12 "General Path Index" 13 "General Path Index" 14 "General Path Index" 15 "General Path Index" 16 "General Path Index" 17 "General Path Index" 18 "General Path Index" 19 "General Path Index" 20 "General Path Index" 21 "General Path Index" 22 "General Path Index" 23 "General Path Index" 24 "General Path Index" 25 "General Path Index" 26 "General Path Index" 27 "General Path Index" 28 "General Path Index" 29 "General Path Index" 30 "General Path Index" 31 "General Path Index" 32 "General Path Index" 33 "General Path Index" 34 "General Path Index" 35 "General Path Index" 36 "General Path Index" 37 "General Path Index" 38 "General Path Index" 39 "General Path Index" 40 "General Path Index" 41 "General Path Index" 42 "General Path Index" 43 "General Path Index" 44 "General Path Index" 45 "General Path Index" 46 "General Path Index" 47 "General Path Index" 48 "General Path Index" 49 "General Path Index" 50 "General Path Index" 51 "General Path Index" 52 "General Path Index" 53 "General Path Index" 54 "General Path Index" 55 "General Path Index" 56 "General Path Index" 57 "General Path Index" 58 "General Path Index" 59 "General Path Index" 60 "General Path Index" 61 "General Path Index" 62 "General Path Index" 63 "General Path Index" ;
VAL_ 550 STUB_Retransmission 0 "False" 1 "True" ;
VAL_ 550 STUB_Update 0 "False" 1 "True" ;
VAL_ 550 STUB_RelativeProbability 0 "Turn not allowed" 1 "Relative probability" 2 "Relative probability" 3 "Relative probability" 4 "Relative probability" 5 "Relative probability" 6 "Relative probability" 7 "Relative probability" 8 "Relative probability" 9 "Relative probability" 10 "Relative probability" 11 "Relative probability" 12 "Relative probability" 13 "Relative probability" 14 "Relative probability" 15 "Relative probability" 16 "Relative probability" 17 "Relative probability" 18 "Relative probability" 19 "Relative probability" 20 "Relative probability" 21 "Relative probability" 22 "Relative probability" 23 "Relative probability" 24 "Relative probability" 25 "Relative probability" 26 "Relative probability" 27 "Relative probability" 28 "Relative probability" 29 "Relative probability" 30 "Relative probability" 31 "Invalid" ;
VAL_ 550 STUB_FunctionalRoadClass 0 "Unknown" 1 "Freeway" 2 "Arterial(City freeway)" 3 "County" 4 "Collector" 5 "Local" 6 "Etc(ferry unpaved)" 7 "Invalid" ;
VAL_ 550 STUB_CalculatedRoute 0 "Not Calculated Route(MPP)" 1 "Part of Calculated Route" 2 "Off Route or Recalculating Route" 3 "Invalid" ;
VAL_ 550 STUB_ComplexIntersection 0 "Not part of complex intersection" 1 "Part of of complex intersection" 2 "Unknown" 3 "Invalid" ;
VAL_ 550 STUB_FormOfWay 0 "Unknown" 1 "Main path(nondisjunction)" 2 "Main path(disjunction)" 3 "JC" 4 "Plural Junction M" 5 "IC" 6 "Reserved" 7 "Service Area" 8 "Reserved" 9 "Roundabout" 10 "P turn" 11 "U trun" 12 "Pedestrian" 13 "Frontage Road" 14 "Intersection internal" 15 "Invalid" ;
VAL_ 550 STUB_TurnAngle 0 "In path direction" 1 "1.417 degrees right" 2 "0x2~0x7D:Right from real north direction" 125 "0x2~0x7D:Right from real north direction" 126 "178.583 degrees right" 127 "Opposite direction" 128 "178.583 degrees left" 129 "0x81~0xFC:Left from real north direction" 252 "0x81~0xFC:Left from real north direction" 253 "1.417 degrees left" 254 "Unknown" 255 "Invalid" ;
VAL_ 550 STUB_LastStubAtOffset 0 "more STUB messages will be sent" 1 "last one of given parent" ;
VAL_ 550 STUB_RightOfWay 0 "Parent path has right of way" 1 "Sub-path has right of way" 2 "Unknown" 3 "Invalid" ;
VAL_ 550 STUB_OppositeLanes 0 "Unknown" 1 "One lane only" 2 "2 or more lanes" 3 "Invalid" ;
VAL_ 550 STUB_DirectionLanes 0 "Unknown" 1 "Lane count" 2 "Lane count" 3 "Lane count" 4 "Lane count" 5 "Lane count" 6 "6 or more lanes" 7 "Invalid" ;
VAL_ 1078 CF_Gway_PASDisplayFLH 0 "Off" 1 "1st warning" 2 "2nd warning" 3 "3rd warning" 4 "Error" ;
VAL_ 1078 CF_Gway_PASDisplayFRH 0 "Off" 1 "1st warning" 2 "2nd warning" 3 "3rd warning" 4 "Error" ;
VAL_ 1078 CF_Gway_PASRsound 0 "OFF (No warning alarm)" 1 "1st warning" 2 "2nd warning" 3 "3rd warning" ;
VAL_ 1078 CF_Gway_PASDisplayFCTR 0 "Off" 1 "1st warning" 2 "2nd warning" 3 "3rd warning" 4 "Error" ;
VAL_ 1078 CF_Gway_PASDisplayRCTR 0 "Off" 1 "1st warning" 2 "2nd warning" 3 "3rd warning" 4 "Error" ;
VAL_ 1078 CF_Gway_PASFsound 0 "OFF (No warning alarm)" 1 "1st warning" 2 "2nd warning" 3 "3rd warning" ;
VAL_ 1078 CF_Gway_PASDisplayRLH 0 "Off" 1 "1st warning" 2 "2nd warning" 3 "3rd warning" 4 "Error" ;
VAL_ 1078 CF_Gway_PASDisplayRRH 0 "Off" 1 "1st warning" 2 "2nd warning" 3 "3rd warning" 4 "Error" ;
VAL_ 1078 CF_Gway_PASCheckSound 0 "Off" 1 "R_Confirm" 2 "Error" 3 "Reserved" ;
VAL_ 1078 CF_Gway_PASSystemOn 0 "OFF" 1 "ON" 2 "reserved" 3 "reserved" ;
VAL_ 1078 CF_Gway_PASOption 0 "Non" 1 "RPAS" 2 "PAS" 3 "reserved" ;
VAL_ 1136 VCU1_STS 0 "Normal status" 1 "Not Received" 2 "Reserved" 3 "Invalid" ;
VAL_ 1136 EBS1_STS 0 "Normal status" 1 "Not Received" 2 "Reserved" 3 "Invalid" ;
VAL_ 1136 MCU1_STS 0 "Normal status" 1 "Not Received" 2 "Reserved" 3 "Invalid" ;
VAL_ 1136 MCU3_STS 0 "Normal status" 1 "Not Received" 2 "Reserved" 3 "Invalid" ;
VAL_ 1136 VCU3_STS 0 "Normal status" 1 "Not Received" 2 "Reserved" 3 "Invalid" ;
VAL_ 1136 VCU5_STS 0 "Normal status" 1 "Not Received" 2 "Reserved" 3 "Invalid" ;
VAL_ 1136 LVR1_STS 0 "Normal status" 1 "Not Received" 2 "Reserved" 3 "Invalid" ;
VAL_ 1136 VCU2_STS 0 "Normal status" 1 "Not Received" 2 "Reserved" 3 "Invalid" ;
VAL_ 1426 CF_Vcu_LowSocLp 0 "Lamp Off" 1 "Lamp On" ;
VAL_ 1426 CF_Vcu_DteOff 0 "None" 1 "DTE Off('---' Display)" ;
VAL_ 1426 CF_Vcu_SerLamp 0 "None" 1 "Service Lamp On" ;
VAL_ 1426 CF_Vcu_ChrgAlert 0 "Not display" 1 "Display" ;
VAL_ 1426 CF_Vcu_PwrDnMode 0 "None" 1 "Set" ;
VAL_ 1426 CF_Vcu_CruOnLamp 0 "Lamp Off" 1 "Lamp On" ;
VAL_ 1426 CF_Vcu_CruSetLamp 0 "Lamp Off" 1 "Lamp On" ;
VAL_ 1426 CF_Vcu_BrkLpReq 0 "None" 1 "Lamp On Request" ;
VAL_ 1426 CF_Vcu_EvMod 0 "None" 1 "Vehicle Stop" 2 "EV Propulsion" 3 "Not used" 4 "Not used" 5 "Not used" 6 "Regeneration" 7 "Not used" 8 "Not used" 9 "Not used" ;
VAL_ 1507 CR_VCU_EcoLvl 0 "Nomal (not display)" 1 "Fail (repair display)" ;
VAL_ 1265 CF_Clu_CruiseSwState 0 "Idle Position" 1 "Resume/Plus" 2 "Set/Minus" 3 "Time gap (Distance, SCC only)" 4 "ACC/SCC cancel" 7 "Reserved" ;
VAL_ 1265 CF_Clu_CruiseSwMain 0 "Off" 1 "On" ;
VAL_ 1265 CF_Clu_SldMainSW 0 "Off" 1 "On" ;
VAL_ 1265 CF_Clu_VanzDecimal 0 "0" 1 "0.125" 2 "0.250" 3 "0.375" ;
VAL_ 1265 CF_Clu_SPEED_UNIT 0 "km/h" 1 "MPH" ;
VAL_ 1265 CF_Clu_DetentOut 0 "Detent Off" 1 "Detent On" ;
VAL_ 1265 CF_Clu_RheostatLevel 0 "Reserved" 1 "Step 1" 2 "Step 2" 3 "Step 3" 4 "Step 4" 5 "Step 5" 6 "Step 6" 7 "Step 7" 8 "Step 8" 9 "Step 9" 10 "Step 10" 11 "Step 11" 12 "Step 12" 13 "Step 13" 14 "Step 14" 15 "Step 15" 16 "Step 16" 17 "Step 17" 18 "Step 18" 19 "Step 19" 20 "Step 20 (Reset Value)" 21 "Step 21 (Detent)" ;
VAL_ 1292 CF_Clu_LowfuelWarn 0 "Low fuel Warning is off" 1 "Low fuel Warning is on" 2 "Not used" 3 "Invalid" ;
VAL_ 1292 CF_Clu_RefDetMod 0 "Non refuel detected" 1 "Refuel detected" ;
VAL_ 1292 CF_Clu_AvsmCur 0 "AVSM SYSTEM ON" 1 "AVSM SYSTEM OFF" ;
VAL_ 1292 CF_Clu_DrivingModeSwi 0 "Normal" 1 "Sports" 2 "Snow" 3 "Eco" ;
VAL_ 1292 CF_Clu_TripUnit 0 "Not Used" 1 "km" 2 "mile" 3 "Invailid" ;
VAL_ 1292 CF_Clu_SWL_Stat 0 "Lamp OFF" 1 "Lamp On" 2 "Lamp Flashing" 3 "ACU message error" 7 "Lamp Circuit Failure" ;
VAL_ 1292 CF_Clu_ActiveEcoSW 0 "Off" 1 "On" ;
VAL_ 1292 CF_Clu_EcoDriveInf 0 "Not Activated" 1 "Green Lamp On" 2 "Yellow Lamp On" 3 "Red Lamp On" 7 "Error" ;
VAL_ 1292 CF_Clu_DriveModeSW 0 "off" 1 "on" ;
VAL_ 1292 CF_Clu_AALastBreakTime 0 "0" 1 "30min" 2 "1hour" 3 "1hour 30min" 4 "2hour" 5 "2hour 30min" 6 "3hour" 7 "3hour 30min" 8 "4hour" 9 "4hour 30min" 10 "5hour" 11 "5hour 30min" 12 "6hour" 13 "6hour 30min" 14 "7hour or more than" 15 "Invalid" ;
VAL_ 1292 CF_Clu_LdwsLkasSW 0 "Off" 1 "On" ;
VAL_ 1292 CF_Clu_LkasDispMode 0 "Unavailable" 1 "LDW only" 2 "LKA+LDW (default)" 3 "Reserved" ;
VAL_ 1292 CF_Clu_AltLStatus 0 "Off (Low)" 1 "On (Open or High)" ;
VAL_ 1301 CF_Clu_ADrUNValueSet 0 "Default" 1 "Off" 2 "Key Out On" 3 "Shift Lever On" 4 "Override" 5 "Invalid" ;
VAL_ 1301 CF_Clu_ADrLNValueSet 0 "Default" 1 "Off" 2 "Vehicle Speed On (15Km)" 3 "Shift Lever On" 4 "Invalid" ;
VAL_ 1301 CF_Clu_EscortHLNValueSet 0 "Default Value" 1 "Escort Off" 2 "Escort On" 3 "Invalid" ;
VAL_ 1301 CF_Clu_DoorLSNValueSet 0 "Off" 1 "Disable" 2 "Enable" 3 "Invalid" ;
VAL_ 1301 CF_Clu_PSMNValueSet 0 "Default Value" 1 "Off (Disable)" 2 "50mmOn (Enable)" 3 "75mmOn (Enable)" 4 "Reserved" 5 "Reserved" 6 "Reserved" 7 "Invalid" ;
VAL_ 1301 CF_Clu_TTUnlockNValueSet 0 "Default" 1 "Off" 2 "On" 3 "Invalid" ;
VAL_ 1301 CF_Clu_ATTurnNValueSet 0 "Default Value" 1 "Auto Triple Turn Off" 2 "Auto Triple Turn On" 3 "Invalid" ;
VAL_ 1301 CF_Clu_SCMNValueSet 0 "Default" 1 "Steering Off" 2 "Steering On" 3 "Invalid" ;
VAL_ 1301 CF_Clu_WlightNValueSet 0 "Default Value" 1 "Welcome Light Off" 2 "Welcome Light On" 3 "Invalid" ;
VAL_ 1301 CF_Clu_TempUnitNValueSet 0 "Off" 1 "Centigrade(℃)" 2 "Fahrenheit(℉)" 3 "Invalid" ;
VAL_ 1301 CF_Clu_TrfChgSet 0 "Off" 1 "On" 2 "Invalid" 3 "Invalid" ;
VAL_ 1301 CF_Clu_OTTurnNValueSet 0 "Default" 1 "One Touch Turn Off" 2 "3 Flashing" 3 "5 Flashing" 4 "7 Flashing" 5 "Invalid" 6 "Reserved" 7 "Reserved" ;
VAL_ 1301 CF_Clu_LcaNValueSet 0 "Off" 1 "Disable" 2 "Enable" 3 "Invalid" ;
VAL_ 1301 CF_Clu_RctaNValueSet 0 "Off" 1 "Disable" 2 "Enable" 3 "Invalid" ;
VAL_ 1301 CF_Clu_RcwNValueSet 0 "Off" 1 "Disable" 2 "Enable" 3 "Invalid" ;
VAL_ 1301 CF_Clu_EcsOffNValueSet 0 "Off" 1 "Disable" 2 "Enable" 3 "Invalid" ;
VAL_ 1301 CF_Clu_SccNaviCrvNValueSet 0 "Default" 1 "Disable" 2 "Enable" 3 "Invalid" ;
VAL_ 1301 CF_Clu_SccNaviCamNValueSet 0 "Default" 1 "Disable" 2 "Enable" 3 "Invalid" ;
VAL_ 1301 CF_Clu_SccAebNValueSet 0 "Default" 1 "Disable" 2 "Enable" 3 "Invalid" ;
VAL_ 1301 CF_Clu_LkasModeNValueSet 0 "Default Value" 1 "LDW Mode" 2 "Standard LKA" 3 "Active LKA" ;
VAL_ 1301 CF_Clu_FcwNValueSet 0 "Default" 1 "Disable" 2 "Enable" 3 "Invalid" ;
VAL_ 1301 CF_Clu_PasSpkrLvNValueSet 0 "Default" 1 "Level 1" 2 "Level 2" 3 "Level 3" 4 "Reserved" 5 "Reserved" 6 "Reserved" 7 "Invalid (Error Value)" ;
VAL_ 1301 CF_Clu_SccDrvModeNValueSet 0 "Default" 1 "Slow" 2 "Normal" 3 "Fast" 4 "Reserved" 5 "Reserved" 6 "Reserved" 7 "Invalid" ;
VAL_ 1301 CF_Clu_HAnBNValueSet 0 "Default" 1 "Arm Disarm Buzzer Off" 2 "Arm Disarm Buzzer On" 3 "Invalid" ;
VAL_ 1301 CF_Clu_HfreeTrunkTgNValueSet 0 "Default" 1 "HandsFree Off" 2 "HandsFree On" 3 "Reserved" 4 "Invalid" ;
VAL_ 1322 CF_Clu_VehicleSpeed 0 "0x0~0xFE:Speed" 254 "0x0~0xFE:Speed" 255 "Error" ;
VAL_ 1322 CF_Clu_InhibitP 0 "Off" 1 "(On)P" ;
VAL_ 1322 CF_Clu_InhibitR 0 "Off" 1 "(On)R" ;
VAL_ 1322 CF_Clu_InhibitN 0 "Off" 1 "(On)N" ;
VAL_ 1322 CF_Clu_InhibitD 0 "Off" 1 "(On)D" ;
VAL_ 1322 CF_Clu_LanguageInfo 0 "Off" 1 "Korean" 2 "English(US)" 3 "English(UK)" 4 "Chinese(Mandarin)" 5 "Chinese(Cantonese)" 6 "French(EU)" 7 "Spanish(EU)" 8 "Arabic" 9 "Czech" 10 "Danish" 11 "German" 12 "Italian" 13 "Dutch" 14 "Polish" 15 "Portuguese" 16 "Russian" 17 "Slovak" 18 "Swedish" 19 "Turkish" 20 "French(US)" 21 "Spanish(US)" 22 "Reserved" 23 "Reserved" 24 "Reserved" 25 "Reserved" 26 "Reserved" 27 "Reserved" 28 "Reserved" 29 "Reserved" 30 "Reserved" 31 "Invalid" ;
VAL_ 1322 CF_Clu_ClusterSound 0 "Cluster applied speaker" 1 "Cluster applied buzzer" ;
VAL_ 1307 CF_Clu_TirePressUnitNValueSet 0 "Default Value" 1 "psi" 2 "kpa" 3 "bar" 4 "Reserved" 5 "Reserved" 6 "Reserved" 7 "Invalid" ;
VAL_ 1307 CF_Clu_SlifNValueSet 0 "Default Value" 1 "Disable" 2 "Enable" 3 "Invalid" ;
VAL_ 1307 CF_Clu_AutoLightNValueSet 0 "Default" 1 "Bright" 2 "Normal" 3 "Overcast" 4 "Reserved" 5 "Reserved" 6 "Reserved" 7 "Invalid" ;
VAL_ 1307 CF_Clu_FuelGuideReset 0 "Default" 1 "Reset Request" ;
VAL_ 1307 CF_Clu_DAWModeNValueSet 0 "Defaul" 1 "OFF" 2 "Late" 3 "Normal" 4 "Early" 5 "Reserved" 6 "Reserved" 7 "Invalid" ;
VAL_ 1307 CF_Clu_AebModeNValueSet 0 "Default" 1 "On (Late)" 2 "ON (Normal)" 3 "ON (Early)" 4 "Reserved" 5 "Reserved" 6 "Reserved" 7 "Invalid" ;
VAL_ 1307 CF_Clu_ECoastingNvalueSet 0 "Default" 1 "Disable" 2 "Enable" 3 "Invalid" ;
VAL_ 1307 CF_Clu_USMReset 0 "Defualt" 1 "Reset" ;
VAL_ 1307 CF_Gway_WPCNValueSet 0 "Default" 1 "Off(Disable)" 2 "On(Enable)" 3 "Invalid" ;
VAL_ 1307 CF_Clu_ECoastWarnNValueSet 0 "Default" 1 "Disable" 2 "Enable" 3 "Invalid" ;
VAL_ 1307 CF_Clu_AuxBatChargeNValueSet 0 "Default" 1 "Disable" 2 "Enable" 3 "Invalid" ;
VAL_ 1307 CF_Clu_ECoastCtrlNValueSet 0 "Default" 1 "Long distance" 2 "Middle distance" 3 "Short distance" 4 "Reserved" 5 "Reserved" 6 "Reserved" 7 "Invalid" ;
VAL_ 1168 EPB_I_LAMP 0 "Release State (EPB/ AVH)" 1 "Apply State (EPB)" 2 "Dynamic Braking (EPB) or Driver Action Requested" ;
VAL_ 1168 EPB_F_LAMP 0 "No failure" 1 "Failure detected or in diagnosis mode" 2 "EOL configuration not done or Emergency released" 3 "Reserved" ;
VAL_ 1168 EPB_ALARM 0 "Off" 1 "Comfortable tone (Sound once)" 2 "Uncomfortable tone" 3 "Reserved" ;
VAL_ 1168 EPB_CLU 0 "Off" 1 "EPB is in maintenance mode" 2 "Driver tries to DAR but safety condition is not satisfied" 3 "EPB applies by ESC request" 4 "Driver tries to DAR but safety condition is not satisfied for China" ;
VAL_ 1168 EPB_SWITCH 0 "Neutral position" 1 "Apply position (pull)" 2 "Release position (push)" 3 "Switch failure" ;
VAL_ 1168 EPB_RBL 0 "No request" 1 "Request to turn on rear brake lights" ;
VAL_ 1168 EPB_STATUS 0 "See details in EPB_FRC_ERR" 1 "Released" 2 "Clamped" 3 "Clamping in progress without switch" 4 "Releasing in progress without switch" 5 "Dynamic braking via EPB" 6 "Releasing in progress by switch" 7 "Clamping in progress by switch" ;
VAL_ 1168 EPB_FRC_ERR 0 "No failure" 1 "Clamp position not reached" 2 "Emergency release" 3 "Force not measurable (e.g. sensor failure)" ;
VAL_ 1168 EPB_DBF_STAT 0 "EPB_DBF_REQ signal is valid" 1 "EPB_DBF_REQ signal is invalid" ;
VAL_ 1168 ESP_ACK 0 "Idle / No acknowledge" 1 "Acknowledge for external ESC request" ;
VAL_ 1168 EPB_DBF_REQ 0 "No Request" 1 "Dynamic braking request" ;
VAL_ 1168 EPB_FAIL 0 "Not valid" 1 "EPB No failure" 2 "EPB Initialization State" 3 "EPB Diagnostic" 4 "EPB Temporarily Not Available" 5 "EPB Permanently Not Available" ;
VAL_ 1168 EPB_FORCE 0 "EPB Fully released" ;
VAL_ 1419 CF_Lca_Stat 0 "System is Off" 1 "System Passive" 2 "System Active" 3 "System Failure" 4 "System Blockage" 5 "System Overtemperature" 6 "System minor failure" ;
VAL_ 1419 CF_Rcta_Stat 0 "System is Off" 1 "System Passive" 2 "System Active" 3 "System Failure" 4 "System Blockage" 5 "System Overtemperature" 6 "System minor failure" ;
VAL_ 1419 CF_Lca_IndLeft 0 "Indicator output off" 1 "Indicator on (information)" 2 "Indicator blinking(warning)" 3 "Indicator output check" ;
VAL_ 1419 CF_Lca_IndRight 0 "Indicator output off" 1 "Indicator on (information)" 2 "Indicator blinking(warning)" 3 "Indicator output check" ;
VAL_ 1419 CF_Lca_SndWan_Stat 0 "Off" 1 "On" 2 "Off failure" 3 "On failure" ;
VAL_ 1419 CF_FR_SndWan 0 "Speaker is Off" 1 "Speaker On" ;
VAL_ 1419 CF_FL_SndWan 0 "Speaker is Off" 1 "Speaker On" ;
VAL_ 1419 CF_RR_SndWan 0 "Speaker is Off" 1 "Speaker On" ;
VAL_ 1419 CF_RL_SndWan 0 "Speaker is Off" 1 "Speaker On" ;
VAL_ 1419 CF_RCTA_IndLeft 0 "Warning is Off" 1 "Warning On" ;
VAL_ 1419 CF_RCTA_IndRight 0 "Warning is Off" 1 "Warning On" ;
VAL_ 832 CF_Lkas_LdwsSysState 0 "System OFF" 1 "Low Vehicle Speed" 2 "System Unavailable" 3 "MDPS Control_Full Lane Recognized" 4 "Full Lane Recognized" 5 "Left Line Recognized" 6 "Right Line Recognized" 7 "MDPS Control_Left Line Recognized" 8 "MDPS Control_Right Line Recognized" 14 "System Not Calibrated" 15 "System Failure" ;
VAL_ 832 CF_Lkas_SysWarning 0 "No Info" 4 "Hands-Off Warning" 9 "System Automatic off" ;
VAL_ 832 CF_Lkas_LdwsLHWarning 0 "No Warning" 1 "HAPTIC Warning and Display" 2 "Acoustic Warning and Display" ;
VAL_ 832 CF_Lkas_LdwsRHWarning 0 "No Warning" 1 "HAPTIC Warning and Display" 2 "Acoustic Warning and Display" ;
VAL_ 832 CF_Lkas_HbaLamp 0 "HBA Indicator Lamp Off" 1 "HBA Indicator Lamp On" ;
VAL_ 832 CF_Lkas_ActToi 0 "De-activate TOI" 1 "Activate TOI" ;
VAL_ 832 CF_Lkas_ToiFlt 0 "No Fault" 1 "Fault Present" ;
VAL_ 832 CF_Lkas_HbaSysState 0 "Default (Disable)" 1 "HBA Enable & High Beam Off" 2 "HBA Enable & High Beam On" 7 "System Fail" ;
VAL_ 832 CF_Lkas_HbaOpt 0 "None HBA Option (Default)" 1 "HBA System Enable" ;
VAL_ 832 CF_Lkas_FusionState 0 "Normal" 1 "Fusion Disabled" 2 "SCC Communication Error" 3 "Camera Blockage" ;
VAL_ 832 CF_Lkas_LdwsOpt_USM 0 "Invalid" 1 "LDW Mode" 2 "Standard LKA" 3 "Active LKA" 4 "LDWS Only (None LKAS)" ;
VAL_ 1342 CF_Lkas_AATimeReset 0 "No Signal" 1 "Time Reset" ;
VAL_ 1342 CF_Lkas_AAOpt_USM 0 "None AA option(Default)" 1 "System OFF" 2 "Late" 3 "Normal" 4 "Early" 5 "Reserved" 6 "Reserved" 7 "Invalid" ;
VAL_ 1342 CF_Lkas_AAStatus 0 "System OFF" 1 "Attention Level1" 2 "Attention Level2" 3 "Attention Level3" 4 "Attention Level4" 5 "Attention Level5" 6 "Reserved" 7 "Reserved" 8 "Reserved" 9 "Reserved" 10 "Reserved" 11 "Reserved" 12 "Reserved" 13 "Reserved" 14 "System Standby" 15 "System Fail" ;
VAL_ 1342 CF_Lkas_AAWarn 0 "No Warning" 1 "Rest Recommend Warning" 2 "Reserved" 3 "Reserved" ;
VAL_ 897 CF_Mdps_WLmp 0 "MDPS Malfunction Warning lamp OFF" 1 "MDPS Malfunciton Warning lamp BLANKING(2Hz)" 2 "MDPS Malfunction Warning lamp ON" 3 "MDPS Malfunction Warning lamp BLANKING(1Hz)" ;
VAL_ 897 CF_Mdps_Flex 0 "Standard Mode" 1 "Sport Mode" 2 "Comport Mode" 3 "Reserved" ;
VAL_ 897 CF_Mdps_ALTRequest 0 "Current consumption is low" 1 "Current consumption is high" ;
VAL_ 897 CF_Mdps_VSM_FUNC 0 "The VSM function of MDPS is not plugged in (unplugged)." 1 "The VSM function of MDPS is plugged in." ;
VAL_ 897 CF_Mdps_LKAS_FUNC 0 "The LKAS function of MDPS is not plugged in (unplugged)." 1 "The LKAS function of MDPS is plugged in." ;
VAL_ 897 CF_Mdps_CurrMode 0 "Standard Mode" 1 "Sport Mode" 2 "Comfort Mode" 3 "Reserved" ;
VAL_ 897 CF_Mdps_Type 0 "C-MDPS" 1 "R-MDPS(Dual Pinion)" 2 "R-MDPS(Belt)" 3 "Reserved" ;
VAL_ 593 CF_Mdps_Def 0 "MDPS is not defective" 1 "MDPS is defective" ;
VAL_ 593 CF_Mdps_ToiUnavail 0 "Available" 1 "Unavailable" ;
VAL_ 593 CF_Mdps_ToiActive 0 "Deactivated" 1 "Activated" ;
VAL_ 593 CF_Mdps_ToiFlt 0 "No fault" 1 "Faulty" ;
VAL_ 593 CF_Mdps_FailStat 0 "Not in fail state" 1 "In fail state" ;
VAL_ 593 CF_Mdps_SErr 0 "VSM1 signal is not error" 1 "VSM1 signal is error" ;
VAL_ 1056 MainMode_ACC 0 "OFF" 1 "ON" ;
VAL_ 1056 SCCInfoDisplay 0 "-" 1 "Display “SCC Mode”" 2 "Display “Conventional Cruise Mode”" 3 "Display “Object disappeared at low speed”" 4 "Display “Available to resume acceleration control”" ;
VAL_ 1056 ObjValid 0 "No in-path object detected" 1 "In-path object detected" ;
VAL_ 1056 DriverAlertDisplay 0 "-" 1 "Display “SCC Disengaged“" 2 "Display “No SCC Engage Condition!“" 3 "Display “SCC Disengaged When The Vehicle Stops&quot;" ;
VAL_ 1056 TauGapSet 0 "No time gap set" 1 "1st level distance" 2 "2nd level distance" 3 "3rd level distance" 4 "4th level distance" ;
VAL_ 1056 ACC_ObjStatus 0 "No SCC object detected" 1 "SCC Object detected" 2 "Reserved" 3 "SCC Pre-Safe I/F inactive (No VI platform detected)" ;
VAL_ 1056 Navi_SCC_Curve_Status 0 "Not Applied" 1 "Function Off" 2 "Function On" 3 "Invalid(Fail)" ;
VAL_ 1056 Navi_SCC_Curve_Act 0 "Off" 1 "Ready" 2 "Act" 3 "Reserved" ;
VAL_ 1056 Navi_SCC_Camera_Act 0 "Off" 1 "Ready" 2 "Act" 3 "Reserved" ;
VAL_ 1056 Navi_SCC_Camera_Status 0 "Not Applied" 1 "Function Off" 2 "Function On" 3 "Invalid(Fail)" ;
VAL_ 1057 CF_VSM_Prefill 0 "No pre-fill" 1 "Pre-fill" ;
VAL_ 1057 CF_VSM_DecCmdAct 0 "No request" 1 "Request valid" ;
VAL_ 1057 CF_VSM_HBACmd 0 "Standard threshold" 1 "Lowered threshold 1" 2 "Lowered threshold 2" 3 "Lowered threshold 3" ;
VAL_ 1057 CF_VSM_Warn 0 "No warning" 1 "Warning level 1" 2 "Warning level 2" 3 "Warning level 3" ;
VAL_ 1057 CF_VSM_Stat 0 "Not applicable" 1 "Available" 2 "Temporarily not available" 3 "Permanently not available" ;
VAL_ 1057 CF_VSM_BeltCmd 0 "Release / No alert" 1 "Pre-crash full retraction" 2 "Haptic warning" ;
VAL_ 1057 ACCFailInfo 0 "System without error" 1 "Performance degredation" 2 "System temporairy unavailable" 3 "SCC Service Required" ;
VAL_ 1057 ACCMode 0 "Off" 1 "Engaged" 2 "Override" 3 "Shutoff" ;
VAL_ 1057 StopReq 0 "No request" 1 "Stop control is required" ;
VAL_ 1057 TakeOverReq 0 "No takeover request" 1 "Takeover request" ;
VAL_ 1057 PreFill 0 "No pre-filling of the brake system is required" 1 "Pre-filling of the brake system is required" ;
VAL_ 1057 CF_VSM_ConfMode 0 "Reserved" 1 "CDM Off" 2 "CDM On" 3 "Reserved" ;
VAL_ 1057 AEB_Failinfo 0 "Normal" 1 "Temp. Unavailable by Camera" 2 "Temp. Unavailavle by Radar" 3 "Service Required" ;
VAL_ 1057 AEB_Status 0 "Not Applied" 1 "System Off" 2 "System On" 3 "Invalid (Fail)" ;
VAL_ 1057 AEB_CmdAct 0 "No request" 1 "Request valid" ;
VAL_ 1057 AEB_StopReq 0 "No request" 1 "Stop control is required" ;
VAL_ 1057 CR_VSM_Alive 15 "Signal Invalid" ;
VAL_ 1290 SCCDrvModeRValue 0 "Default" 1 "Comfort Mode" 2 "Normal Mode" 3 "Dynamic Mode" 4 "Reserved" 5 "Reserved" 6 "Reserved" 7 "Invalid" ;
VAL_ 1290 SCC_Equip 0 "Not Applied" 1 "Applied" ;
VAL_ 1290 AebDrvSetStatus 0 "Off" 1 "Late" 2 "Normal" 3 "Early" 4 "Reserved" 5 "Reserved" 6 "Not Applied" 7 "Invalid" ;
VAL_ 1427 TPMS_W_LAMP 0 "TPMS Malfunction Warning lamp OFF" 1 "TPMS Malfunction Warning lamp ON" 2 "TPMS Malfunction Warning lamp BLINKING(2Hz)" 3 "Reserved" ;
VAL_ 1427 TREAD_W_LAMP 0 "TREAD Warning lamp OFF" 1 "TREAD Warning lamp ON" 2 "TREAD Warning lamp BLINKING(2Hz)" 3 "Reserved" ;
VAL_ 1427 POS_FL_W_LAMP 0 "FL POSITION Warning lamp OFF" 1 "FL POSITION Warning lamp ON" ;
VAL_ 1427 POS_FR_W_LAMP 0 "FR POSITION Warning lamp OFF" 1 "FR POSITION Warning lamp ON" ;
VAL_ 1427 POS_RL_W_LAMP 0 "RL POSITION Warning lamp OFF" 1 "RL POSITION Warning lamp ON" ;
VAL_ 1427 POS_RR_W_LAMP 0 "RR POSITION Warning lamp OFF" 1 "RR POSITION Warning lamp ON" ;
VAL_ 1427 STATUS_TPMS 0 "inactive" 1 "active" 2 "reserved" 3 "reserved" 4 "reserved" 5 "reserved" 6 "reserved" 7 "reserved" ;
VAL_ 1427 UNIT 0 "psi" 1 "kpa" 2 "bar" 3 "reserved" ;
VAL_ 352 CF_Ahb_SLmp 0 "AHB Service Lamp is Off" 1 "AHB Service Lamp is On" 2 "AHB Service Lamp is BLINKING(2HZ)" 3 "Reserved" ;
VAL_ 352 CF_Ahb_Def 0 "AHB is normal mode" 1 "AHB is degraded mode" 2 "AHB is defective mode" 3 "Reserved" ;
VAL_ 352 CF_Ahb_Act 0 "All Control Inactive" 1 "Charging Active" 2 "AHB Control Active" 3 "Chaging Active + AHB Control Active" ;
VAL_ 352 CF_Ahb_Diag 0 "AHB is not diagnostic mode" 1 "AHB is diagnostic mode" ;
VAL_ 352 CF_Ahb_WLmp 0 "AHB Warning Lamp is Off" 1 "AHB Warning Lamp is On" ;
VAL_ 352 CF_Ahb_SnsFail 0 "Normal" 1 "Fail" ;
VAL_ 352 CF_Ahb_PedalCalStat 0 "Not complete" 1 "Complete" ;
VAL_ 352 CF_Ahb_Bzzr 0 "Buzzer is Off" 1 "Buzzer is On" ;
VAL_ 352 CF_Esc_BrakeAct 0 "ECU does not support this function." 1 "Brake switch is not pressed (OFF)" 2 "Brake switch is pressed (ON)" 3 "Brake switch failure" ;
VAL_ 1984 CCW 3 "Request calibration and acceptance of SAS_CID" 5 "Reset SAS_CAL flag" ;
VAL_ 1151 AVH_STAT 0 "No apply" 1 "Vehicle is held by the service brake" 2 "Being released" 3 "Reserved" ;
VAL_ 1151 LDM_STAT 0 "ESC ready to DBF/AVH (requested by switch)" 1 "ESC can’t perform DBF/AVH (requested by switch)" ;
VAL_ 1151 REQ_EPB_ACT 0 "No request" 1 "Release request" 2 "Close request in comfort mode" 3 "Close request in secure mode" ;
VAL_ 1151 REQ_EPB_STAT 0 "REQ_EPB_ACT signal is valid" 1 "REQ_EPB_ACT signal is invalid" ;
VAL_ 1151 ECD_ACT 0 "ECD is not active" 1 "ECD is active(operating)" ;
VAL_ 1151 _4WD_LIM_REQ 0 "No request from ESC" 1 "Request duty limit from ESC" ;
VAL_ 1151 _4WD_OPEN 0 "Passive" 1 "Clutch off" 2 "Torque limit" 3 "Error" ;
VAL_ 1151 _4WD_LIM_MODE 0 "Maximum limitation mode" 1 "Minimum limitation mode" ;
VAL_ 544 LAT_ACCEL_STAT 0 "Lateral acceleration signal is valid" 1 "Lateral acceleration signal is invalid" ;
VAL_ 544 LAT_ACCEL_DIAG 0 "Lateral acceleration signal is available" 1 "Lateral acceleration signal is not available temporarily" ;
VAL_ 544 LONG_ACCEL_STAT 0 "Longitudinal acceleration signal is valid" 1 "Longitudinal acceleration signal is invalid" ;
VAL_ 544 LONG_ACCEL_DIAG 0 "Longitudinal acceleration signal is available" 1 "Longitudinal acceleration signal is not available temporarily" ;
VAL_ 544 CYL_PRES_STAT 0 "Master cylinder pressure signal is valid" 1 "Master cylinder pressure signal is invalid" ;
VAL_ 544 CYL_PRESS_DIAG 0 "Master cylinder pressure signal is available" 1 "Master cylinder pressure is not available temporarily" ;
VAL_ 544 YAW_RATE_STAT 0 "Yaw rate sensor signal is valid" 1 "Yaw rate sensor signal is invalid" ;
VAL_ 544 YAW_RATE_DIAG 0 "Yaw rate signal is available" 1 "Yaw rate signal is not available temporarily" ;
VAL_ 544 CYL_PRES_FLAG 0 "Off" 1 "On" ;
VAL_ 339 TCS_REQ 0 "Passive" 1 "TCS/ESC control active" ;
VAL_ 339 MSR_C_REQ 0 "Passive or TCS function" 1 "MSR control active" ;
VAL_ 339 TCS_PAS 1 "TCS is disabled by user" ;
VAL_ 339 TCS_GSC 0 "passive (gear change allowed)" 1 "active (gear change not allowed)" ;
VAL_ 339 CF_Esc_LimoInfo 0 "Invalid" 1 "Invalid" 2 "Vehicle is not Limo" 3 "Vehicle is Limo" ;
VAL_ 339 ABS_DIAG 0 "ABS/TCS/ESC is not diagnostic mode" 1 "ABS/TCS/ESC is diagnostic mode" ;
VAL_ 339 ABS_DEF 0 "ABS is not defective" 1 "ABS is defective" ;
VAL_ 339 TCS_DEF 1 "TCS is defective (failed)" ;
VAL_ 339 TCS_CTL 1 "TCS Active" ;
VAL_ 339 ABS_ACT 0 "ABS control inactive" 1 "ABS control active" ;
VAL_ 339 EBD_DEF 0 "EBD is not defective" 1 "EBD is defective" ;
VAL_ 339 ESP_PAS 1 "ESC disabled by user (SW off)" ;
VAL_ 339 ESP_DEF 1 "ESC is defective (failed)" ;
VAL_ 339 ESP_CTL 1 "ESC active" ;
VAL_ 339 TCS_MFRN 0 "Using both TQI_TCS and TQI_SLW_TCS" 1 "Using TQI_TCS only (Not using TQI_SLW_TCS)" ;
VAL_ 339 DBC_CTL 1 "DBC is Active" ;
VAL_ 339 DBC_PAS 1 "DBC is stand by (SW ON)" ;
VAL_ 339 DBC_DEF 1 "DBC is defective (failed)" ;
VAL_ 339 HAC_CTL 1 "HAC is Active" ;
VAL_ 339 HAC_PAS 1 "HAC is stand by (SW ON) If SW is applied" ;
VAL_ 339 HAC_DEF 1 "HAC is defective (failed)" ;
VAL_ 339 ESS_STAT 0 "ESS control “inactive” (Normal condition)" 1 "ESS control “active” (Emergency stop condition)" 2 "ESS system is defective" 3 "ESS extended function active (Hazard lamp blinking)" ;
VAL_ 339 CF_Esc_BrkCtl 0 "Brake control is not in activation" 1 "Brake control is in activation" ;
VAL_ 339 CF_Brk_AbsNReq 0 "Inactive" 1 "N Gear position Request Active" ;
VAL_ 339 BLA_CTL 0 "No request" 1 "Activate brake lights" 2 "Reserved" 3 "Reserved" ;
VAL_ 916 BrakeLight 0 "No request" 1 "Activate brake lights" ;
VAL_ 916 DCEnable 0 "Disable deceleration control" 1 "Enable deceleration control" ;
VAL_ 916 ACCReqLim 0 "No request" 1 "Limited No Limitation" 2 "Acceleration Limited" 3 "Deceleration Limited" ;
VAL_ 916 ACCEnable 0 "SCC enabled" 1 "SCC disabled reversible" 2 "SCC disabled irreversible" 3 "SCC disabled irreversible due to communication error" ;
VAL_ 916 DriverOverride 0 "No override" 1 "Override by acceleration pedal" 2 "Override by deceleration" 3 "Not defined" ;
VAL_ 916 StandStill 0 "No stand still detected" 1 "stand still detected" ;
VAL_ 916 ACC_EQUIP 0 "SCC is not equipped" 1 "SCC is equipped" ;
VAL_ 916 PBRAKE_ACT 0 "Parking brake is not activated" 1 "Parking brake is activated" ;
VAL_ 916 ACC_REQ 0 "No request" 1 "Enable SCC torque request" ;
VAL_ 916 DriverBraking 0 "Brake pedal not pressed" 1 "Brake pedal pressed" ;
VAL_ 916 CF_VSM_Coded 0 "Not coded" 1 "Coded" ;
VAL_ 916 CF_VSM_Avail 0 "Not available" 1 "Available" 2 "Temporarily not available" 3 "Permanently not available" ;
VAL_ 916 CF_VSM_Handshake 0 "Not okay" 1 "Okay" ;
VAL_ 916 CF_DriBkeStat 0 "Driver is not braking / failure" 1 "Driver is braking" ;
VAL_ 916 CF_VSM_ConfSwi 0 "Switch Not Pressed" 1 "Switch Pressed" 2 "Reserved" 3 "Error Identifier (switch failure detected by ESC or CAN communication failure)" ;
VAL_ 916 AEB_EQUIP 0 "AEB is not equipped" 1 "AEB is equipped" ;
VAL_ 1287 ABS_W_LAMP 0 "ABS Warning lamp OFF" 1 "ABS Warning lamp ON" ;
VAL_ 1287 TCS_OFF_LAMP 0 "TCS/ESC OFF SW Lamp OFF" 1 "TCS/ESC OFF SW Lamp ON" ;
VAL_ 1287 TCS_LAMP 0 "TCS/ESC Function/Warning Lamp OFF" 1 "TCS/ESC Function/Warning Lamp ON" 2 "TCS/ESC Function/Warning Lamp BLINKING(2Hz)" 3 "Reserved" ;
VAL_ 1287 DBC_W_LAMP 0 "DBC Warning lamp OFF" 1 "DBC Warning lamp ON" ;
VAL_ 1287 DBC_F_LAMP 0 "DBC Function lamp OFF" 1 "DBC Function lamp ON" 2 "DBC Function lamp BLINKING(2Hz)" 3 "Reserved" ;
VAL_ 1287 ESC_Off_Step 0 "Normal Mode" 1 "Sports Mode" 2 "Off Mode" 3 "ESC OFF SW is defective (failed)" ;
VAL_ 1287 AVH_CLU 0 "AVH is off" 1 "AUTO HOLD to be deactivated Press Brake Pedal" 2 "Press Brake Pedal to Release AUTO HOLD" 3 "AUTO HOLD cannot be activated Close Seat Belt, Door, Hood, Trunk" 4 "AUTO HOLD cannot be deactivated, Close Seat Belt, Door, Hood" 5 "AUTO HOLD cannot be deactivated. Close Door" ;
VAL_ 1287 AVH_I_LAMP 0 "Lamp On" 1 "Lamp Off" 2 "Reserved" 3 "Reserved" ;
VAL_ 1287 EBD_W_LAMP 0 "EBD Warning lamp OFF" 1 "EBD Warning lamp ON" ;
VAL_ 1287 AVH_ALARM 0 "No alarm" 1 "On AVH Activation, Vehicle is not secured and driver is still inside = comfortable tone" ;
VAL_ 1287 AVH_LAMP 0 "AVH Off (Lamp Status" 1 "AVH failure (Lamp Status" 2 "AVH ACTIVE (Lamp Status" 3 "AVH READY (Lamp Status" 4 "Lamp Status" 5 "Lamp Status" 6 "Lamp Status" ;
VAL_ 356 CF_Esc_Act 0 "VSM control inactive0H" 1 "VSM control active" ;
VAL_ 356 CF_Esc_CtrMode 0 "Inactive" 1 "Mode 1 (sensor value overlay mode)" 2 "Mode 2 (output torque overlay mode)" 3 "Mode 3 (Particular control)" ;
VAL_ 356 CF_Esc_Def 0 "VSM is not defective" 1 "VSM is defective" ;
VAL_ 903 WHL_DIR_FL 0 "Unknown (Wheel moving stop state or Not applied wheel sensor for direction)" 1 "Forward direction" 2 "Backward direction" 3 "Error identifier" ;
VAL_ 903 WHL_DIR_FR 0 "Unknown (Wheel moving stop state or Not applied wheel sensor for direction)" 1 "Forward direction" 2 "Backward direction" 3 "Error identifier" ;
VAL_ 903 WHL_DIR_RL 0 "Unknown (Wheel moving stop state or Not applied wheel sensor for direction)" 1 "Forward direction" 2 "Backward direction" 3 "Error identifier" ;
VAL_ 903 WHL_DIR_RR 0 "Unknown (Wheel moving stop state or Not applied wheel sensor for direction)" 1 "Forward direction" 2 "Backward direction" 3 "Error identifier" ;
